VERSION ""

NS_ :

BS_:

BU_: EHR_Spare FEHR_3 PTO_SpeedSelector Dummy_Node_Ch2 FEHR_2 TrailerBrake OffBoardDiagnosticTool1_Ch2 PowerTakeOff_Ch2 Transmission1_Ch2 FEHR_1 REHR_5 REHR_4 REHR_3 REHR_2 REHR_1 InstrumentCluster_Ch2 ManagementComputer_Ch2 GWAY_OnBoardDiagnosticUnit_Ch2 GWAY_OffBoardDiagTool1_VB1_Ch2 GWAY_Engine1_Ch2 GWAY_CabDisplay1_Ch2 AuxiliaryValveControl_Ch2

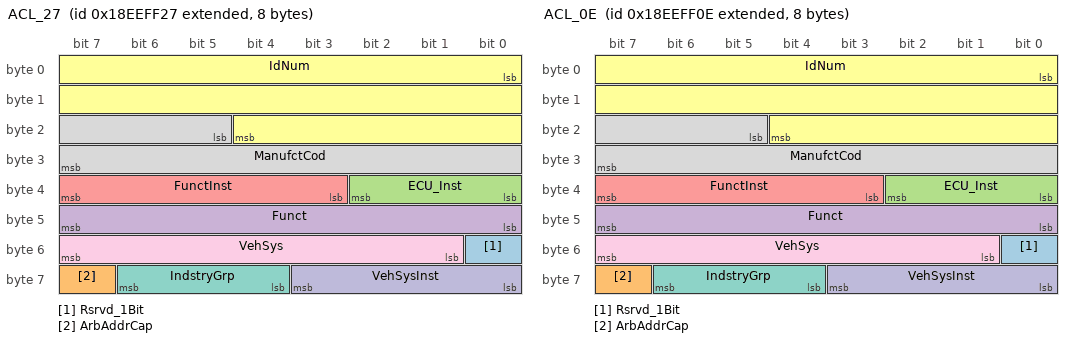
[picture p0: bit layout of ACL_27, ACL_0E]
BO_ 2565799719 ACL_27: 8 ManagementComputer_Ch2
 SG_ Rsrvd_1Bit : 48|1@1+ (1,0) [0|1] ""  Dummy_Node_Ch2
 SG_ ArbAddrCap : 63|1@1+ (1,0) [0|1] ""  Dummy_Node_Ch2
 SG_ ECU_Inst : 32|3@1+ (1,0) [0|7] ""  Dummy_Node_Ch2
 SG_ Funct : 40|8@1+ (1,0) [0|255] ""  Dummy_Node_Ch2
 SG_ FunctInst : 35|5@1+ (1,0) [0|31] ""  Dummy_Node_Ch2
 SG_ IdNum : 0|21@1+ (1,0) [0|2097151] ""  Dummy_Node_Ch2
 SG_ IndstryGrp M : 60|3@1+ (1,0) [0|7] ""  Dummy_Node_Ch2
 SG_ ManufctCod : 21|11@1+ (1,0) [0|2047] ""  Dummy_Node_Ch2
 SG_ VehSys : 49|7@1+ (1,0) [0|127] ""  Dummy_Node_Ch2
 SG_ VehSysInst : 56|4@1+ (1,0) [0|15] ""  Dummy_Node_Ch2

BO_ 2566838798 SOFT_0E: 60 TrailerBrake
 SG_ SupplrSW_VerNum_Byte_13 : 240|8@1+ (1,0) [0|255] ""  ManagementComputer_Ch2
 SG_ SupplrSW_VerNum_Byte_14 : 248|8@1+ (1,0) [0|255] ""  ManagementComputer_Ch2
 SG_ WarnErrDbVer : 472|8@1+ (1,0) [0|255] ""  ManagementComputer_Ch2
 SG_ ApplSW_PN : 8|8@1+ (1,0) [0|255] ""  ManagementComputer_Ch2
 SG_ ApplSW_PN_Byte_01 : 16|8@1+ (1,0) [0|255] ""  ManagementComputer_Ch2
 SG_ ApplSW_PN_Byte_02 : 24|8@1+ (1,0) [0|255] ""  ManagementComputer_Ch2
 SG_ ApplSW_PN_Byte_03 : 32|8@1+ (1,0) [0|255] ""  ManagementComputer_Ch2
 SG_ ApplSW_PN_Byte_04 : 40|8@1+ (1,0) [0|255] ""  ManagementComputer_Ch2
 SG_ ApplSW_PN_Byte_05 : 48|8@1+ (1,0) [0|255] ""  ManagementComputer_Ch2
 SG_ ApplSW_PN_Byte_06 : 56|8@1+ (1,0) [0|255] ""  ManagementComputer_Ch2
 SG_ ApplSW_PN_Byte_07 : 64|8@1+ (1,0) [0|255] ""  ManagementComputer_Ch2
 SG_ ApplSW_PN_Byte_08 : 72|8@1+ (1,0) [0|255] ""  ManagementComputer_Ch2
 SG_ ApplSW_PN_Byte_09 : 80|8@1+ (1,0) [0|255] ""  ManagementComputer_Ch2
 SG_ ApplSW_PN_Byte_10 : 88|8@1+ (1,0) [0|255] ""  ManagementComputer_Ch2
 SG_ ApplSW_PN_Byte_11 : 96|8@1+ (1,0) [0|255] ""  ManagementComputer_Ch2
 SG_ ApplSW_PN_Byte_12 : 104|8@1+ (1,0) [0|255] ""  ManagementComputer_Ch2
 SG_ ApplSW_PN_Byte_13 : 112|8@1+ (1,0) [0|255] ""  ManagementComputer_Ch2
 SG_ ApplSW_PN_Byte_14 : 120|8@1+ (1,0) [0|255] ""  ManagementComputer_Ch2
 SG_ CalibrId : 336|8@1+ (1,0) [0|255] "ASCII"  ManagementComputer_Ch2
 SG_ CalibrId_Byte_01 : 344|8@1+ (1,0) [0|255] "ASCII"  ManagementComputer_Ch2
 SG_ CalibrId_Byte_02 : 352|8@1+ (1,0) [0|255] "ASCII"  ManagementComputer_Ch2
 SG_ CalibrId_Byte_03 : 360|8@1+ (1,0) [0|255] "ASCII"  ManagementComputer_Ch2
 SG_ CalibrId_Byte_04 : 368|8@1+ (1,0) [0|255] "ASCII"  ManagementComputer_Ch2
 SG_ CalibrId_Byte_05 : 376|8@1+ (1,0) [0|255] "ASCII"  ManagementComputer_Ch2
 SG_ CalibrId_Byte_06 : 384|8@1+ (1,0) [0|255] "ASCII"  ManagementComputer_Ch2
 SG_ CalibrId_Byte_07 : 392|8@1+ (1,0) [0|255] "ASCII"  ManagementComputer_Ch2
 SG_ CalibrId_Byte_08 : 400|8@1+ (1,0) [0|255] "ASCII"  ManagementComputer_Ch2
 SG_ CalibrId_Byte_09 : 408|8@1+ (1,0) [0|255] "ASCII"  ManagementComputer_Ch2
 SG_ CalibrId_Byte_10 : 416|8@1+ (1,0) [0|255] "ASCII"  ManagementComputer_Ch2
 SG_ CalibrId_Byte_11 : 424|8@1+ (1,0) [0|255] "ASCII"  ManagementComputer_Ch2
 SG_ CalibrId_Byte_12 : 432|8@1+ (1,0) [0|255] "ASCII"  ManagementComputer_Ch2
 SG_ CalibrId_Byte_13 : 440|8@1+ (1,0) [0|255] "ASCII"  ManagementComputer_Ch2
 SG_ CalibrId_Byte_14 : 448|8@1+ (1,0) [0|255] "ASCII"  ManagementComputer_Ch2
 SG_ CalibrId_Byte_15 : 456|8@1+ (1,0) [0|255] "ASCII"  ManagementComputer_Ch2
 SG_ EndStrng_00 : 128|8@1+ (1,0) [0|255] "per byte"  ManagementComputer_Ch2
 SG_ EndStrng_01 : 256|8@1+ (1,0) [0|255] "per byte"  ManagementComputer_Ch2
 SG_ EndStrng_02 : 328|8@1+ (1,0) [0|255] ""  ManagementComputer_Ch2
 SG_ EndStrng_03 : 464|8@1+ (1,0) [0|255] ""  ManagementComputer_Ch2
 SG_ NumSW_IdField : 0|8@1+ (1,0) [0|250] "step"  ManagementComputer_Ch2
 SG_ ProgDate : 264|8@1+ (1,0) [0|255] ""  ManagementComputer_Ch2
 SG_ ProgDate_Byte_01 : 272|8@1+ (1,0) [0|255] ""  ManagementComputer_Ch2
 SG_ ProgDate_Byte_02 : 280|8@1+ (1,0) [0|255] ""  ManagementComputer_Ch2
 SG_ ProgDate_Byte_03 : 288|8@1+ (1,0) [0|255] ""  ManagementComputer_Ch2
 SG_ ProgDate_Byte_04 : 296|8@1+ (1,0) [0|255] ""  ManagementComputer_Ch2
 SG_ ProgDate_Byte_05 : 304|8@1+ (1,0) [0|255] ""  ManagementComputer_Ch2
 SG_ ProgDate_Byte_06 : 312|8@1+ (1,0) [0|255] ""  ManagementComputer_Ch2
 SG_ ProgDate_Byte_07 : 320|8@1+ (1,0) [0|255] ""  ManagementComputer_Ch2
 SG_ SupplrSW_VerNum : 136|8@1+ (1,0) [0|255] ""  ManagementComputer_Ch2
 SG_ SupplrSW_VerNum_Byte_01 : 144|8@1+ (1,0) [0|255] ""  ManagementComputer_Ch2
 SG_ SupplrSW_VerNum_Byte_02 : 152|8@1+ (1,0) [0|255] ""  ManagementComputer_Ch2
 SG_ SupplrSW_VerNum_Byte_03 : 160|8@1+ (1,0) [0|255] ""  ManagementComputer_Ch2
 SG_ SupplrSW_VerNum_Byte_04 : 168|8@1+ (1,0) [0|255] ""  ManagementComputer_Ch2
 SG_ SupplrSW_VerNum_Byte_05 : 176|8@1+ (1,0) [0|255] ""  ManagementComputer_Ch2
 SG_ SupplrSW_VerNum_Byte_06 : 184|8@1+ (1,0) [0|255] ""  ManagementComputer_Ch2
 SG_ SupplrSW_VerNum_Byte_07 : 192|8@1+ (1,0) [0|255] ""  ManagementComputer_Ch2
 SG_ SupplrSW_VerNum_Byte_08 : 200|8@1+ (1,0) [0|255] ""  ManagementComputer_Ch2
 SG_ SupplrSW_VerNum_Byte_09 : 208|8@1+ (1,0) [0|255] ""  ManagementComputer_Ch2
 SG_ SupplrSW_VerNum_Byte_10 : 216|8@1+ (1,0) [0|255] ""  ManagementComputer_Ch2
 SG_ SupplrSW_VerNum_Byte_11 : 224|8@1+ (1,0) [0|255] ""  ManagementComputer_Ch2
 SG_ SupplrSW_VerNum_Byte_12 : 232|8@1+ (1,0) [0|255] ""  ManagementComputer_Ch2

BO_ 2566835470 DM4_0E: 31 TrailerBrake
 SG_ EngIntakManifld_1Prs : 48|8@1+ (2,0) [0|500] "kPa"  ManagementComputer_Ch2
 SG_ EngSpd : 56|16@1+ (0.125,0) [0|8031.88] "rpm"  ManagementComputer_Ch2
 SG_ EngTorqMode : 40|4@1+ (1,0) [0|15] ""  ManagementComputer_Ch2
 SG_ EngTotHourOp : 200|32@1+ (0.05,0) [0|210554000] "h"  ManagementComputer_Ch2
 SG_ FailModeId : 24|5@1+ (1,0) [0|31] ""  ManagementComputer_Ch2
 SG_ FreezeFrameLen : 0|8@1+ (1,0) [0|255] "count"  ManagementComputer_Ch2
 SG_ HiResolTotVehDist : 168|32@1+ (5,0) [0|21055406075] "m"  ManagementComputer_Ch2
 SG_ Hour : 136|8@1+ (1,0) [0|250] "h"  ManagementComputer_Ch2
 SG_ Minut : 128|8@1+ (1,0) [0|250] "min"  ManagementComputer_Ch2
 SG_ Month : 152|8@1+ (1,0) [0|250] "months"  ManagementComputer_Ch2
 SG_ OC : 32|7@1+ (1,0) [0|127] "binary"  ManagementComputer_Ch2
 SG_ Sec : 120|8@1+ (0.25,0) [0|62.5] "s"  ManagementComputer_Ch2
 SG_ SPN : 8|16@1+ (1,0) [0|65535] ""  ManagementComputer_Ch2
 SG_ SPN1High : 29|3@1+ (1,0) [0|7] ""  ManagementComputer_Ch2
 SG_ SPN_CM : 39|1@1+ (1,0) [0|1] "bit"  ManagementComputer_Ch2
 SG_ WhBsdVehSpd : 88|16@1+ (0.00390625,0) [0|250.996] "km/h"  ManagementComputer_Ch2
 SG_ Year : 160|8@1+ (1,1985) [1985|2235] "years"  ManagementComputer_Ch2
 SG_ AmbrLmpDefSts : 234|2@1+ (1,0) [0|3] ""  ManagementComputer_Ch2
 SG_ EngCoolntTemp : 80|8@1+ (1,-40) [-40|210] "°C"  ManagementComputer_Ch2
 SG_ RedLmpDefSts : 236|2@1+ (1,0) [0|3] ""  ManagementComputer_Ch2
 SG_ AddrAssignNewSA : 240|8@1+ (1,0) [0|255] ""  ManagementComputer_Ch2
 SG_ BattPotentPwrInput_1 : 104|16@1+ (0.05,0) [0|3212.75] "V"  ManagementComputer_Ch2
 SG_ Day : 144|8@1+ (0.25,0) [0|62.5] "days"  ManagementComputer_Ch2
 SG_ Eng_pcLoadCurrSpd : 72|8@1+ (1,0) [0|250] "%"  ManagementComputer_Ch2

BO_ 2566843150 CI_0E: 34 TrailerBrake
 SG_ Make : 0|8@1+ (1,0) [0|255] "ASCII"  ManagementComputer_Ch2
 SG_ Mdl : 48|8@1+ (1,0) [0|255] "ASCII"  ManagementComputer_Ch2
 SG_ SN_2 : 176|8@1+ (1,0) [0|255] "ASCII"  ManagementComputer_Ch2
 SG_ UnitNumPwrUnit : 264|8@1+ (1,0) [0|255] "ASCII"  ManagementComputer_Ch2

BO_ 2566767886 ECUID_0E: 71 TrailerBrake
 SG_ EndStrng_04 : 560|8@1+ (1,0) [0|255] "" Vector__XXX
 SG_ EndStrng_03 : 432|8@1+ (1,0) [0|255] "" Vector__XXX
 SG_ EndStrng_02 : 296|8@1+ (1,0) [0|255] "" Vector__XXX
 SG_ EndStrng_01 : 208|8@1+ (1,0) [0|255] "per byte" Vector__XXX
 SG_ EndStrng_00 : 120|8@1+ (1,0) [0|255] "per byte" Vector__XXX
 SG_ ECU_SN_Byte_09 : 200|8@1+ (1,0) [0|255] "ASCII" Vector__XXX
 SG_ ECU_SN_Byte_08 : 192|8@1+ (1,0) [0|255] "ASCII" Vector__XXX
 SG_ ECU_SN_Byte_07 : 184|8@1+ (1,0) [0|255] "ASCII" Vector__XXX
 SG_ ECU_SN_Byte_06 : 176|8@1+ (1,0) [0|255] "ASCII" Vector__XXX
 SG_ ECU_SN_Byte_05 : 168|8@1+ (1,0) [0|255] "ASCII" Vector__XXX
 SG_ ECU_SN_Byte_04 : 160|8@1+ (1,0) [0|255] "ASCII" Vector__XXX
 SG_ ECU_SN_Byte_03 : 152|8@1+ (1,0) [0|255] "ASCII" Vector__XXX
 SG_ ECU_SN_Byte_02 : 144|8@1+ (1,0) [0|255] "ASCII" Vector__XXX
 SG_ ECU_SN_Byte_01 : 136|8@1+ (1,0) [0|255] "ASCII" Vector__XXX
 SG_ ECU_PN_Byte_14 : 112|8@1+ (1,0) [0|255] "ASCII" Vector__XXX
 SG_ ECU_PN_Byte_13 : 104|8@1+ (1,0) [0|255] "ASCII" Vector__XXX
 SG_ ECU_PN_Byte_12 : 96|8@1+ (1,0) [0|255] "ASCII" Vector__XXX
 SG_ ECU_PN_Byte_11 : 88|8@1+ (1,0) [0|255] "ASCII" Vector__XXX
 SG_ ECU_PN_Byte_10 : 80|8@1+ (1,0) [0|255] "ASCII" Vector__XXX
 SG_ ECU_PN_Byte_09 : 72|8@1+ (1,0) [0|255] "ASCII" Vector__XXX
 SG_ ECU_PN_Byte_08 : 64|8@1+ (1,0) [0|255] "ASCII" Vector__XXX
 SG_ ECU_PN_Byte_07 : 56|8@1+ (1,0) [0|255] "ASCII" Vector__XXX
 SG_ ECU_PN_Byte_06 : 48|8@1+ (1,0) [0|255] "ASCII" Vector__XXX
 SG_ ECU_PN_Byte_05 : 40|8@1+ (1,0) [0|255] "ASCII" Vector__XXX
 SG_ ECU_PN_Byte_04 : 32|8@1+ (1,0) [0|255] "ASCII" Vector__XXX
 SG_ ECU_PN_Byte_03 : 24|8@1+ (1,0) [0|255] "ASCII" Vector__XXX
 SG_ ECU_PN_Byte_02 : 16|8@1+ (1,0) [0|255] "ASCII" Vector__XXX
 SG_ ECU_PN_Byte_01 : 8|8@1+ (1,0) [0|255] "ASCII" Vector__XXX
 SG_ ECU_ManufctName_Byte_14 : 424|8@1+ (1,0) [0|255] "ASCII" Vector__XXX
 SG_ ECU_ManufctName_Byte_13 : 416|8@1+ (1,0) [0|255] "ASCII" Vector__XXX
 SG_ ECU_ManufctName_Byte_12 : 408|8@1+ (1,0) [0|255] "ASCII" Vector__XXX
 SG_ ECU_ManufctName_Byte_11 : 400|8@1+ (1,0) [0|255] "ASCII" Vector__XXX
 SG_ ECU_ManufctName_Byte_10 : 392|8@1+ (1,0) [0|255] "ASCII" Vector__XXX
 SG_ ECU_ManufctName_Byte_09 : 384|8@1+ (1,0) [0|255] "ASCII" Vector__XXX
 SG_ ECU_ManufctName_Byte_08 : 376|8@1+ (1,0) [0|255] "ASCII" Vector__XXX
 SG_ ECU_ManufctName_Byte_07 : 368|8@1+ (1,0) [0|255] "ASCII" Vector__XXX
 SG_ ECU_ManufctName_Byte_06 : 360|8@1+ (1,0) [0|255] "ASCII" Vector__XXX
 SG_ ECU_ManufctName_Byte_05 : 352|8@1+ (1,0) [0|255] "ASCII" Vector__XXX
 SG_ ECU_ManufctName_Byte_04 : 344|8@1+ (1,0) [0|255] "ASCII" Vector__XXX
 SG_ ECU_ManufctName_Byte_03 : 336|8@1+ (1,0) [0|255] "ASCII" Vector__XXX
 SG_ ECU_ManufctName_Byte_02 : 328|8@1+ (1,0) [0|255] "ASCII" Vector__XXX
 SG_ ECU_ManufctName_Byte_01 : 320|8@1+ (1,0) [0|255] "ASCII" Vector__XXX
 SG_ ECU_Locat_Byte_09 : 288|8@1+ (1,0) [0|255] "ASCII" Vector__XXX
 SG_ ECU_Locat_Byte_08 : 280|8@1+ (1,0) [0|255] "ASCII" Vector__XXX
 SG_ ECU_Locat_Byte_07 : 272|8@1+ (1,0) [0|255] "ASCII" Vector__XXX
 SG_ ECU_Locat_Byte_06 : 264|8@1+ (1,0) [0|255] "ASCII" Vector__XXX
 SG_ ECU_Locat_Byte_05 : 256|8@1+ (1,0) [0|255] "ASCII" Vector__XXX
 SG_ ECU_Locat_Byte_04 : 248|8@1+ (1,0) [0|255] "ASCII" Vector__XXX
 SG_ ECU_Locat_Byte_03 : 240|8@1+ (1,0) [0|255] "ASCII" Vector__XXX
 SG_ ECU_Locat_Byte_02 : 232|8@1+ (1,0) [0|255] "ASCII" Vector__XXX
 SG_ ECU_Locat_Byte_01 : 224|8@1+ (1,0) [0|255] "ASCII" Vector__XXX
 SG_ ECU_HW_Id_Byte_14 : 552|8@1+ (1,0) [0|255] "ASCII" Vector__XXX
 SG_ ECU_HW_Id_Byte_13 : 544|8@1+ (1,0) [0|255] "ASCII" Vector__XXX
 SG_ ECU_HW_Id_Byte_12 : 536|8@1+ (1,0) [0|255] "ASCII" Vector__XXX
 SG_ ECU_HW_Id_Byte_11 : 528|8@1+ (1,0) [0|255] "ASCII" Vector__XXX
 SG_ ECU_HW_Id_Byte_10 : 520|8@1+ (1,0) [0|255] "ASCII" Vector__XXX
 SG_ ECU_HW_Id_Byte_09 : 512|8@1+ (1,0) [0|255] "ASCII" Vector__XXX
 SG_ ECU_HW_Id_Byte_08 : 504|8@1+ (1,0) [0|255] "ASCII" Vector__XXX
 SG_ ECU_HW_Id_Byte_07 : 496|8@1+ (1,0) [0|255] "ASCII" Vector__XXX
 SG_ ECU_HW_Id_Byte_06 : 488|8@1+ (1,0) [0|255] "ASCII" Vector__XXX
 SG_ ECU_HW_Id_Byte_05 : 480|8@1+ (1,0) [0|255] "ASCII" Vector__XXX
 SG_ ECU_HW_Id_Byte_04 : 472|8@1+ (1,0) [0|255] "ASCII" Vector__XXX
 SG_ ECU_HW_Id_Byte_03 : 464|8@1+ (1,0) [0|255] "ASCII" Vector__XXX
 SG_ ECU_HW_Id_Byte_02 : 456|8@1+ (1,0) [0|255] "ASCII" Vector__XXX
 SG_ ECU_HW_Id_Byte_01 : 448|8@1+ (1,0) [0|255] "ASCII" Vector__XXX
 SG_ ECU_Locat : 216|8@1+ (1,0) [0|255] "ASCII"  ManagementComputer_Ch2
 SG_ ECU_ManufctName : 312|8@1+ (1,0) [0|255] "ASCII"  ManagementComputer_Ch2
 SG_ ECU_PN : 0|8@1+ (1,0) [0|255] "ASCII"  ManagementComputer_Ch2
 SG_ ECU_SN : 128|8@1+ (1,0) [0|255] "ASCII"  ManagementComputer_Ch2
 SG_ ECU_Typ : 304|8@1+ (1,0) [0|255] "ASCII"  ManagementComputer_Ch2
 SG_ ECUHardwareVersionIdentification : 440|8@1+ (1,0) [0|255] "ASCII"  ManagementComputer_Ch2

BO_ 2566837006 DM11_0E: 0 TrailerBrake

BO_ 2566835214 DM3_0E: 0 TrailerBrake

BO_ 2566834702 DM1_0E: 82 TrailerBrake
 SG_ AmbrWarnLmp : 2|2@1+ (1,0) [0|3] "" Vector__XXX
 SG_ DTC_01 : 16|32@1+ (1,0) [0|4294970000] "" Vector__XXX
 SG_ DTC_02 : 48|32@1+ (1,0) [0|4294970000] "" Vector__XXX
 SG_ DTC_03 : 80|32@1+ (1,0) [0|4294970000] "" Vector__XXX
 SG_ DTC_04 : 112|32@1+ (1,0) [0|4294970000] "" Vector__XXX
 SG_ DTC_05 : 144|32@1+ (1,0) [0|4294970000] "" Vector__XXX
 SG_ DTC_06 : 176|32@1+ (1,0) [0|4294970000] "" Vector__XXX
 SG_ DTC_07 : 208|32@1+ (1,0) [0|4294970000] "" Vector__XXX
 SG_ DTC_08 : 240|32@1+ (1,0) [0|4294970000] "" Vector__XXX
 SG_ DTC_09 : 272|32@1+ (1,0) [0|4294970000] "" Vector__XXX
 SG_ DTC_10 : 304|32@1+ (1,0) [0|4294970000] "" Vector__XXX
 SG_ DTC_11 : 336|32@1+ (1,0) [0|4294970000] "" Vector__XXX
 SG_ DTC_12 : 368|32@1+ (1,0) [0|4294970000] "" Vector__XXX
 SG_ DTC_13 : 400|32@1+ (1,0) [0|4294970000] "" Vector__XXX
 SG_ DTC_14 : 432|32@1+ (1,0) [0|4294970000] "" Vector__XXX
 SG_ DTC_15 : 464|32@1+ (1,0) [0|4294970000] "" Vector__XXX
 SG_ DTC_16 : 496|32@1+ (1,0) [0|4294970000] "" Vector__XXX
 SG_ DTC_17 : 528|32@1+ (1,0) [0|4294970000] "" Vector__XXX
 SG_ DTC_18 : 560|32@1+ (1,0) [0|4294970000] "" Vector__XXX
 SG_ DTC_19 : 592|32@1+ (1,0) [0|4294970000] "" Vector__XXX
 SG_ DTC_20 : 624|32@1+ (1,0) [0|4294970000] "" Vector__XXX
 SG_ FlashAmbrWarnLmpAWL : 10|2@1+ (1,0) [0|3] "" Vector__XXX
 SG_ FlashMIL : 14|2@1+ (1,0) [0|3] "" Vector__XXX
 SG_ FlashProtLmp : 8|2@1+ (1,0) [0|3] "" Vector__XXX
 SG_ FlashRedStopLmpRSL : 12|2@1+ (1,0) [0|3] "" Vector__XXX
 SG_ MIL : 6|2@1+ (1,0) [0|3] "" Vector__XXX
 SG_ ProtLmp : 0|2@1+ (1,0) [0|3] "" Vector__XXX
 SG_ RedStopLmp : 4|2@1+ (1,0) [0|3] "" Vector__XXX

BO_ 2566834958 DM2_0E: 82 TrailerBrake
 SG_ AmbrWarnLmp : 2|2@1+ (1,0) [0|3] "" Vector__XXX
 SG_ DTC_01 : 16|32@1+ (1,0) [0|4294970000] "" Vector__XXX
 SG_ DTC_02 : 48|32@1+ (1,0) [0|4294970000] "" Vector__XXX
 SG_ DTC_03 : 80|32@1+ (1,0) [0|4294970000] "" Vector__XXX
 SG_ DTC_04 : 112|32@1+ (1,0) [0|4294970000] "" Vector__XXX
 SG_ DTC_05 : 144|32@1+ (1,0) [0|4294970000] "" Vector__XXX
 SG_ DTC_06 : 176|32@1+ (1,0) [0|4294970000] "" Vector__XXX
 SG_ DTC_07 : 208|32@1+ (1,0) [0|4294970000] "" Vector__XXX
 SG_ DTC_08 : 240|32@1+ (1,0) [0|4294970000] "" Vector__XXX
 SG_ DTC_09 : 272|32@1+ (1,0) [0|4294970000] "" Vector__XXX
 SG_ DTC_10 : 304|32@1+ (1,0) [0|4294970000] "" Vector__XXX
 SG_ DTC_11 : 336|32@1+ (1,0) [0|4294970000] "" Vector__XXX
 SG_ DTC_12 : 368|32@1+ (1,0) [0|4294970000] "" Vector__XXX
 SG_ DTC_13 : 400|32@1+ (1,0) [0|4294970000] "" Vector__XXX
 SG_ DTC_14 : 432|32@1+ (1,0) [0|4294970000] "" Vector__XXX
 SG_ DTC_15 : 464|32@1+ (1,0) [0|4294970000] "" Vector__XXX
 SG_ DTC_16 : 496|32@1+ (1,0) [0|4294970000] "" Vector__XXX
 SG_ DTC_17 : 528|32@1+ (1,0) [0|4294970000] "" Vector__XXX
 SG_ DTC_18 : 560|32@1+ (1,0) [0|4294970000] "" Vector__XXX
 SG_ DTC_19 : 592|32@1+ (1,0) [0|4294970000] "" Vector__XXX
 SG_ DTC_20 : 624|32@1+ (1,0) [0|4294970000] "" Vector__XXX
 SG_ FlashAmbrWarnLmpAWL : 10|2@1+ (1,0) [0|3] "" Vector__XXX
 SG_ FlashMIL : 14|2@1+ (1,0) [0|3] "" Vector__XXX
 SG_ FlashProtLmp : 8|2@1+ (1,0) [0|3] "" Vector__XXX
 SG_ FlashRedStopLmpRSL : 12|2@1+ (1,0) [0|3] "" Vector__XXX
 SG_ MIL : 6|2@1+ (1,0) [0|3] "" Vector__XXX
 SG_ ProtLmp : 0|2@1+ (1,0) [0|3] "" Vector__XXX
 SG_ RedStopLmp : 4|2@1+ (1,0) [0|3] "" Vector__XXX

BO_ 2565799694 ACL_0E: 8 TrailerBrake
 SG_ Rsrvd_1Bit : 48|1@1+ (1,0) [0|1] ""  ManagementComputer_Ch2
 SG_ ArbAddrCap : 63|1@1+ (1,0) [0|1] ""  ManagementComputer_Ch2
 SG_ ECU_Inst : 32|3@1+ (1,0) [0|7] ""  ManagementComputer_Ch2
 SG_ Funct : 40|8@1+ (1,0) [0|255] ""  ManagementComputer_Ch2
 SG_ FunctInst : 35|5@1+ (1,0) [0|31] ""  ManagementComputer_Ch2
 SG_ IdNum : 0|21@1+ (1,0) [0|2097151] ""  ManagementComputer_Ch2
 SG_ IndstryGrp : 60|3@1+ (1,0) [0|7] ""  ManagementComputer_Ch2
 SG_ ManufctCod : 21|11@1+ (1,0) [0|2047] ""  ManagementComputer_Ch2
 SG_ VehSys : 49|7@1+ (1,0) [0|127] ""  ManagementComputer_Ch2
 SG_ VehSysInst : 56|4@1+ (1,0) [0|15] ""  ManagementComputer_Ch2

BO_ 2632777486 TPCM_0E: 8 TrailerBrake
 SG_ TotNumPktEoMA m19 : 24|8@1+ (1,0) [0|255] "" Vector__XXX
 SG_ CByteTPCM M : 0|8@1+ (1,0) [0|255] "" Vector__XXX
 SG_ ConnAbrtReason m255 : 8|8@1+ (1,0) [0|255] "" Vector__XXX
 SG_ MaxNumPktTPCM_RTS m16 : 32|8@1+ (1,0) [0|255] "" Vector__XXX
 SG_ NumPktSentTPCM_CTS m17 : 8|8@1+ (1,0) [0|255] "" Vector__XXX
 SG_ NxtPktNumSentTPCM_CTS m17 : 16|8@1+ (1,0) [0|255] "" Vector__XXX
 SG_ PGN_PktMsgTPCM_BAM m32 : 40|24@1+ (1,0) [0|16777200] "" Vector__XXX
 SG_ PGN_PktMsgTPCM_ConnAbort m255 : 40|24@1+ (1,0) [0|16777200] "" Vector__XXX
 SG_ PGN_PktMsgTPCM_CTS m17 : 40|24@1+ (1,0) [0|16777200] "" Vector__XXX
 SG_ PGN_PktMsgTPCM_RTS m16 : 40|24@1+ (1,0) [0|16777200] "" Vector__XXX
 SG_ PGN_PktMsgTPCM_RTS2 m19 : 40|24@1+ (1,0) [0|16777200] "" Vector__XXX
 SG_ TotMsgSizeBAM m32 : 8|16@1+ (1,0) [0|64255] "counts" Vector__XXX
 SG_ TotMsgSizeEoMA m19 : 8|16@1+ (1,0) [0|64255] "counts" Vector__XXX
 SG_ TotMsgSizeTPCM_RTS m16 : 8|16@1+ (1,0) [0|64255] "counts" Vector__XXX
 SG_ TotNumPktBAM m32 : 24|8@1+ (1,0) [0|255] "" Vector__XXX
 SG_ TotNumPktTPCM_RTS m16 : 24|8@1+ (1,0) [0|255] "" Vector__XXX

BO_ 2565352206 ACKM_0E_2B: 8 TrailerBrake
 SG_ AddrAccssDeny m2 : 32|8@1+ (1,0) [0|255] ""  GWAY_OnBoardDiagnosticUnit_Ch2
 SG_ AddrAck m0 : 32|8@1+ (1,0) [0|255] ""  GWAY_OnBoardDiagnosticUnit_Ch2
 SG_ AddrBusy m3 : 32|8@1+ (1,0) [0|255] ""  GWAY_OnBoardDiagnosticUnit_Ch2
 SG_ AddrNegAck m1 : 32|8@1+ (1,0) [0|255] ""  GWAY_OnBoardDiagnosticUnit_Ch2
 SG_ CByteAckm M : 0|8@1+ (1,0) [0|255] ""  GWAY_OnBoardDiagnosticUnit_Ch2
 SG_ GrpFunctValAck : 8|8@1+ (1,0) [0|255] ""  GWAY_OnBoardDiagnosticUnit_Ch2
 SG_ PGN_RQST2_0E_28 : 40|24@1+ (1,0) [0|16777200] ""  GWAY_OnBoardDiagnosticUnit_Ch2

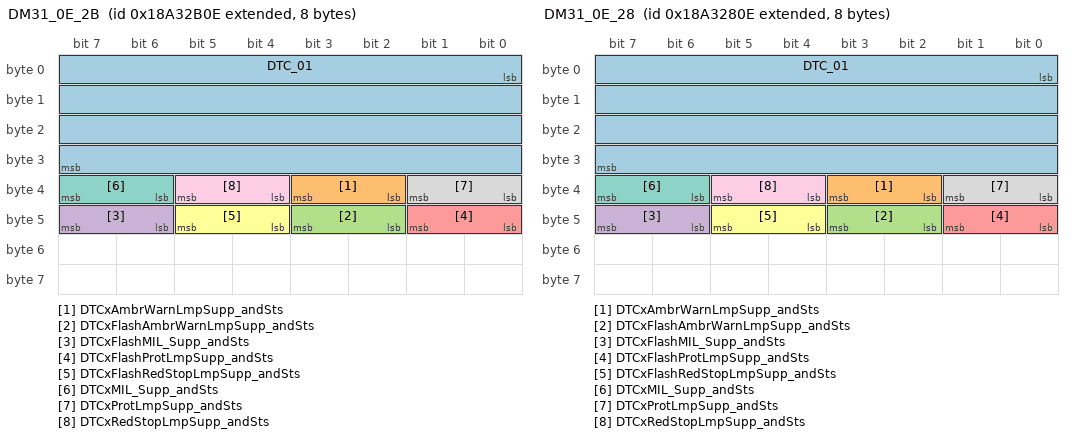
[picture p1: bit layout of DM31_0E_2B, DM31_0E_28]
BO_ 2560830222 DM31_0E_2B: 8 TrailerBrake
 SG_ DTC_01 : 0|32@1+ (1,0) [0|4294970000] ""  GWAY_OnBoardDiagnosticUnit_Ch2
 SG_ DTCxAmbrWarnLmpSupp_andSts : 34|2@1+ (1,0) [0|3] ""  GWAY_OnBoardDiagnosticUnit_Ch2
 SG_ DTCxFlashAmbrWarnLmpSupp_andSts : 42|2@1+ (1,0) [0|3] ""  GWAY_OnBoardDiagnosticUnit_Ch2
 SG_ DTCxFlashMIL_Supp_andSts : 46|2@1+ (1,0) [0|3] ""  GWAY_OnBoardDiagnosticUnit_Ch2
 SG_ DTCxFlashProtLmpSupp_andSts : 40|2@1+ (1,0) [0|3] ""  GWAY_OnBoardDiagnosticUnit_Ch2
 SG_ DTCxFlashRedStopLmpSupp_andSts : 44|2@1+ (1,0) [0|3] ""  GWAY_OnBoardDiagnosticUnit_Ch2
 SG_ DTCxMIL_Supp_andSts : 38|2@1+ (1,0) [0|3] ""  GWAY_OnBoardDiagnosticUnit_Ch2
 SG_ DTCxProtLmpSupp_andSts : 32|2@1+ (1,0) [0|3] ""  GWAY_OnBoardDiagnosticUnit_Ch2
 SG_ DTCxRedStopLmpSupp_andSts : 36|2@1+ (1,0) [0|3] ""  GWAY_OnBoardDiagnosticUnit_Ch2

BO_ 2565537579 RQST_2B: 3 GWAY_OnBoardDiagnosticUnit_Ch2
 SG_ PGN_RQST_2B : 0|24@1+ (1,0) [0|16777200] ""  TrailerBrake

BO_ 2565475883 RQST_2B_0E: 3 GWAY_OnBoardDiagnosticUnit_Ch2
 SG_ PGN_RQST_2B_0E : 0|24@1+ (1,0) [0|16777200] ""  TrailerBrake

BO_ 2564487438 ISO15765_Phys_0E_F9: 8 TrailerBrake
 SG_ BlkSize m3 : 8|8@1+ (1,0) [0|255] ""  GWAY_OffBoardDiagTool1_VB1_Ch2
 SG_ FlowSts m3 : 0|4@1+ (1,0) [0|3] ""  GWAY_OffBoardDiagTool1_VB1_Ch2
 SG_ N1FrameDataLen m1 : 3|12@0+ (1,0) [0|4095] "Byte"  GWAY_OffBoardDiagTool1_VB1_Ch2
 SG_ ProtocCntrlInfo M : 4|4@1+ (1,0) [0|3] ""  GWAY_OffBoardDiagTool1_VB1_Ch2
 SG_ SepTime m3 : 16|8@1+ (1,0) [0|255] "ms"  GWAY_OffBoardDiagTool1_VB1_Ch2
 SG_ SingFrameDataLen m0 : 0|4@1+ (1,0) [0|7] "Byte"  GWAY_OffBoardDiagTool1_VB1_Ch2
 SG_ SN m2 : 0|4@1+ (1,0) [0|15] ""  GWAY_OffBoardDiagTool1_VB1_Ch2

BO_ 2564427513 ISO15765_Phys_F9_0E: 8 GWAY_OffBoardDiagTool1_VB1_Ch2
 SG_ BlkSize m3 : 8|8@1+ (1,0) [0|255] ""  TrailerBrake
 SG_ FlowSts m3 : 0|4@1+ (1,0) [0|3] ""  TrailerBrake
 SG_ N1FrameDataLen m1 : 3|12@0+ (1,0) [0|4095] "Byte"  TrailerBrake
 SG_ ProtocCntrlInfo M : 4|4@1+ (1,0) [0|3] ""  TrailerBrake
 SG_ SepTime m3 : 16|8@1+ (1,0) [0|255] "ms"  TrailerBrake
 SG_ SingFrameDataLen m0 : 0|4@1+ (1,0) [0|7] "Byte"  TrailerBrake
 SG_ SN m2 : 0|4@1+ (1,0) [0|15] ""  TrailerBrake

BO_ 2565351438 ACKM_0E_28: 8 TrailerBrake
 SG_ AddrAccssDeny m2 : 32|8@1+ (1,0) [0|255] ""  GWAY_CabDisplay1_Ch2
 SG_ AddrAck m0 : 32|8@1+ (1,0) [0|255] ""  GWAY_CabDisplay1_Ch2
 SG_ AddrBusy m3 : 32|8@1+ (1,0) [0|255] ""  GWAY_CabDisplay1_Ch2
 SG_ AddrNegAck m1 : 32|8@1+ (1,0) [0|255] ""  GWAY_CabDisplay1_Ch2
 SG_ CByteAckm M : 0|8@1+ (1,0) [0|255] ""  GWAY_CabDisplay1_Ch2
 SG_ GrpFunctValAck : 8|8@1+ (1,0) [0|255] ""  GWAY_CabDisplay1_Ch2
 SG_ PGN_RQST2_0E_28 : 40|24@1+ (1,0) [0|16777200] ""  GWAY_CabDisplay1_Ch2

BO_ 2560829454 DM31_0E_28: 8 TrailerBrake
 SG_ DTC_01 : 0|32@1+ (1,0) [0|4294970000] ""  GWAY_CabDisplay1_Ch2
 SG_ DTCxAmbrWarnLmpSupp_andSts : 34|2@1+ (1,0) [0|3] ""  GWAY_CabDisplay1_Ch2
 SG_ DTCxFlashAmbrWarnLmpSupp_andSts : 42|2@1+ (1,0) [0|3] ""  GWAY_CabDisplay1_Ch2
 SG_ DTCxFlashMIL_Supp_andSts : 46|2@1+ (1,0) [0|3] ""  GWAY_CabDisplay1_Ch2
 SG_ DTCxFlashProtLmpSupp_andSts : 40|2@1+ (1,0) [0|3] ""  GWAY_CabDisplay1_Ch2
 SG_ DTCxFlashRedStopLmpSupp_andSts : 44|2@1+ (1,0) [0|3] ""  GWAY_CabDisplay1_Ch2
 SG_ DTCxMIL_Supp_andSts : 38|2@1+ (1,0) [0|3] ""  GWAY_CabDisplay1_Ch2
 SG_ DTCxProtLmpSupp_andSts : 32|2@1+ (1,0) [0|3] ""  GWAY_CabDisplay1_Ch2
 SG_ DTCxRedStopLmpSupp_andSts : 36|2@1+ (1,0) [0|3] ""  GWAY_CabDisplay1_Ch2

BO_ 2565537576 RQST_28: 3 GWAY_CabDisplay1_Ch2
 SG_ PGN_RQST_28 : 0|24@1+ (1,0) [0|16777200] ""  TrailerBrake

BO_ 2565475880 RQST_28_0E: 3 GWAY_CabDisplay1_Ch2
 SG_ PGN_RQST_28_0E : 0|24@1+ (1,0) [0|16777200] ""  TrailerBrake

BO_ 2564489209 ISO15765_Phys_F9: 8 GWAY_OffBoardDiagTool1_VB1_Ch2
 SG_ BlkSize m3 : 8|8@1+ (1,0) [0|255] ""  FEHR_3,TrailerBrake,FEHR_2,FEHR_1,REHR_5,REHR_4,REHR_3,REHR_2,REHR_1
 SG_ FlowSts m3 : 0|4@1+ (1,0) [0|3] ""  FEHR_3,TrailerBrake,FEHR_2,FEHR_1,REHR_5,REHR_4,REHR_3,REHR_2,REHR_1
 SG_ N1FrameDataLen m1 : 3|12@0+ (1,0) [0|4095] "Byte"  FEHR_3,TrailerBrake,FEHR_2,FEHR_1,REHR_5,REHR_4,REHR_3,REHR_2,REHR_1
 SG_ ProtocCntrlInfo M : 4|4@1+ (1,0) [0|3] ""  FEHR_3,TrailerBrake,FEHR_2,FEHR_1,REHR_5,REHR_4,REHR_3,REHR_2,REHR_1
 SG_ SepTime m3 : 16|8@1+ (1,0) [0|255] "ms"  FEHR_3,TrailerBrake,FEHR_2,FEHR_1,REHR_5,REHR_4,REHR_3,REHR_2,REHR_1
 SG_ SingFrameDataLen m0 : 0|4@1+ (1,0) [0|7] "Byte"  FEHR_3,TrailerBrake,FEHR_2,FEHR_1,REHR_5,REHR_4,REHR_3,REHR_2,REHR_1
 SG_ SN m2 : 0|4@1+ (1,0) [0|15] ""  FEHR_3,TrailerBrake,FEHR_2,FEHR_1,REHR_5,REHR_4,REHR_3,REHR_2,REHR_1

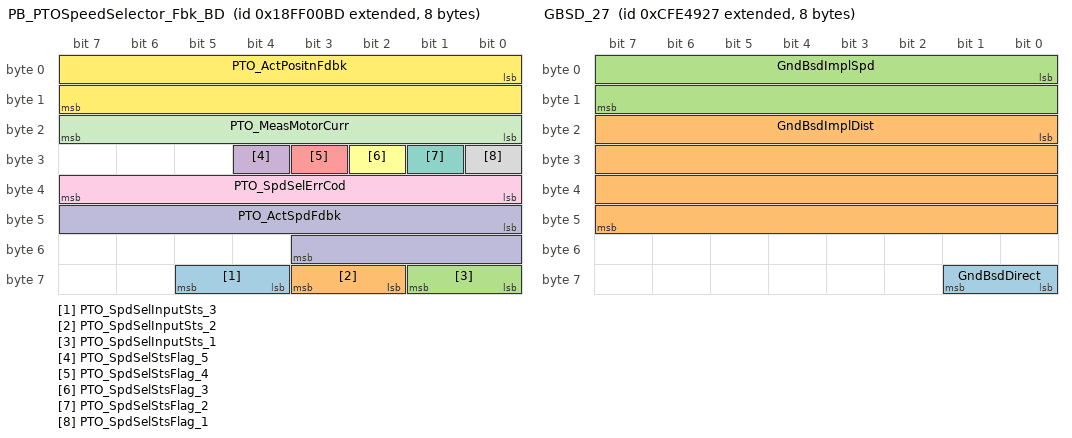
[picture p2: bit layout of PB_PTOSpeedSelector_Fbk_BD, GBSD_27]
BO_ 2566848701 PB_PTOSpeedSelector_Fbk_BD: 8 PTO_SpeedSelector
 SG_ PTO_SpdSelInputSts_3 : 60|2@1+ (25,25) [25|100] "%"  Transmission1_Ch2
 SG_ PTO_SpdSelInputSts_2 : 58|2@1+ (25,25) [25|100] "%"  Transmission1_Ch2
 SG_ PTO_SpdSelInputSts_1 : 56|2@1+ (25,25) [25|100] "%"  Transmission1_Ch2
 SG_ PTO_SpdSelStsFlag_5 : 28|1@1+ (1,0) [0|1] ""  Transmission1_Ch2
 SG_ PTO_SpdSelStsFlag_4 : 27|1@1+ (1,0) [0|1] ""  Transmission1_Ch2
 SG_ PTO_SpdSelStsFlag_3 : 26|1@1+ (1,0) [0|1] ""  Transmission1_Ch2
 SG_ PTO_SpdSelStsFlag_2 : 25|1@1+ (1,0) [0|1] ""  Transmission1_Ch2
 SG_ PTO_SpdSelStsFlag_1 : 24|1@1+ (1,0) [0|1] ""  Transmission1_Ch2
 SG_ PTO_SpdSelErrCod : 32|8@1+ (1,0) [0|255] ""  Transmission1_Ch2
 SG_ PTO_ActSpdFdbk : 40|12@1+ (0.1,0) [0|409.5] "mm/s"  Transmission1_Ch2
 SG_ PTO_MeasMotorCurr : 16|8@1+ (0.25,0) [0|62.5] "A"  Transmission1_Ch2
 SG_ PTO_ActPositnFdbk : 0|16@1+ (0.1,0) [0|6425.5] "mm"  Transmission1_Ch2

BO_ 2365475111 GBSD_27: 8 ManagementComputer_Ch2
 SG_ GndBsdDirect : 56|2@1+ (1,0) [0|3] ""  InstrumentCluster_Ch2
 SG_ GndBsdImplDist : 16|32@1+ (0.001,0) [0|4211081.215] "m"  InstrumentCluster_Ch2
 SG_ GndBsdImplSpd : 0|16@1+ (0.001,0) [0|64255] "m/s"  Transmission1_Ch2,InstrumentCluster_Ch2

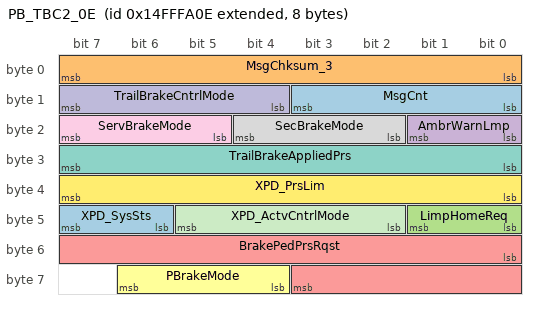
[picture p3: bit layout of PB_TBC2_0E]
BO_ 2499803662 PB_TBC2_0E: 8 TrailerBrake
 SG_ MsgCnt : 8|4@1+ (1,0) [0|15] "count"  ManagementComputer_Ch2
 SG_ MsgChksum_3 : 0|8@1+ (1,0) [0|255] "count"  ManagementComputer_Ch2
 SG_ LimpHomeReq : 40|2@1+ (1,0) [0|3] ""  ManagementComputer_Ch2
 SG_ AmbrWarnLmp : 16|2@1+ (1,0) [0|3] ""  ManagementComputer_Ch2
 SG_ BrakePedPrsRqst : 48|12@1+ (5,0) [0|20475] "kPa"  ManagementComputer_Ch2
 SG_ PBrakeMode : 60|3@1+ (1,0) [0|7] ""  ManagementComputer_Ch2
 SG_ TrailBrakeAppliedPrs : 24|8@1+ (5,0) [0|1250] "kPa"  ManagementComputer_Ch2
 SG_ SecBrakeMode : 18|3@1+ (1,0) [0|7] ""  ManagementComputer_Ch2
 SG_ ServBrakeMode : 21|3@1+ (1,0) [0|7] ""  ManagementComputer_Ch2
 SG_ TrailBrakeCntrlMode : 12|4@1+ (1,0) [0|15] ""  ManagementComputer_Ch2
 SG_ XPD_ActvCntrlMode : 42|4@1+ (1,0) [0|15] ""  ManagementComputer_Ch2
 SG_ XPD_PrsLim : 32|8@1+ (5,0) [0|1250] "kPa"  ManagementComputer_Ch2
 SG_ XPD_SysSts : 46|2@1+ (1,0) [0|3] ""  ManagementComputer_Ch2

BO_ 2564459257 ISO15765_Phys_F9_8A: 8 OffBoardDiagnosticTool1_Ch2
 SG_ SingFrameDataLen m0 : 0|4@1+ (1,0) [0|7] "Byte" Vector__XXX
 SG_ SN m2 : 0|4@1+ (1,0) [0|15] "" Vector__XXX
 SG_ ProtocCntrlInfo M : 4|4@1+ (1,0) [0|3] ""  FEHR_2
 SG_ N1FrameDataLen m1 : 3|12@0+ (1,0) [0|4095] "Byte" Vector__XXX
 SG_ BlkSize m3 : 8|8@1+ (1,0) [0|255] "" Vector__XXX
 SG_ FlowSts m3 : 0|4@1+ (1,0) [0|3] "" Vector__XXX
 SG_ SepTime m3 : 16|8@1+ (1,0) [0|255] "ms" Vector__XXX

BO_TX_BU_ 2564489209 : OffBoardDiagnosticTool1_Ch2,GWAY_OffBoardDiagTool1_VB1_Ch2;
CM_ BO_ 2565799719 "Address Claimed";
CM_ SG_ 2565799719 Rsrvd_1Bit "Set to 0 for J1939-81";
CM_ BO_ 2566838798 "Byte: 1 Number of software identification fields. 2-n Software identification(s) . Delimiter (ASCII “*”)  NOTE- The software identification field is variable in length and may contain up to 125 software identification designators.";
CM_ SG_ 2566838798 SupplrSW_VerNum_Byte_13 "Software ID. ";
CM_ SG_ 2566838798 SupplrSW_VerNum_Byte_14 "Software ID. ";
CM_ SG_ 2566838798 WarnErrDbVer "Software ID. Set to P826vxx or to P662vxx";
CM_ SG_ 2566838798 ApplSW_PN "Software ID. ";
CM_ SG_ 2566838798 ApplSW_PN_Byte_01 "Software ID. ";
CM_ SG_ 2566838798 ApplSW_PN_Byte_02 "Software ID. ";
CM_ SG_ 2566838798 ApplSW_PN_Byte_03 "Software ID. ";
CM_ SG_ 2566838798 ApplSW_PN_Byte_04 "Software ID. ";
CM_ SG_ 2566838798 ApplSW_PN_Byte_05 "Software ID. ";
CM_ SG_ 2566838798 ApplSW_PN_Byte_06 "Software ID. ";
CM_ SG_ 2566838798 ApplSW_PN_Byte_07 "Software ID. ";
CM_ SG_ 2566838798 ApplSW_PN_Byte_08 "Software ID. ";
CM_ SG_ 2566838798 ApplSW_PN_Byte_09 "Software ID. ";
CM_ SG_ 2566838798 ApplSW_PN_Byte_10 "Software ID. ";
CM_ SG_ 2566838798 ApplSW_PN_Byte_11 "Software ID. ";
CM_ SG_ 2566838798 ApplSW_PN_Byte_12 "Software ID. ";
CM_ SG_ 2566838798 ApplSW_PN_Byte_13 "Software ID. ";
CM_ SG_ 2566838798 ApplSW_PN_Byte_14 "Software ID. ";
CM_ SG_ 2566838798 CalibrId "this signal has a lenght of 16 bytes";
CM_ SG_ 2566838798 CalibrId_Byte_01 "this signal has a lenght of 16 bytes";
CM_ SG_ 2566838798 CalibrId_Byte_02 "this signal has a lenght of 16 bytes";
CM_ SG_ 2566838798 CalibrId_Byte_03 "this signal has a lenght of 16 bytes";
CM_ SG_ 2566838798 CalibrId_Byte_04 "this signal has a lenght of 16 bytes";
CM_ SG_ 2566838798 CalibrId_Byte_05 "this signal has a lenght of 16 bytes";
CM_ SG_ 2566838798 CalibrId_Byte_06 "this signal has a lenght of 16 bytes";
CM_ SG_ 2566838798 CalibrId_Byte_07 "this signal has a lenght of 16 bytes";
CM_ SG_ 2566838798 CalibrId_Byte_08 "this signal has a lenght of 16 bytes";
CM_ SG_ 2566838798 CalibrId_Byte_09 "this signal has a lenght of 16 bytes";
CM_ SG_ 2566838798 CalibrId_Byte_10 "this signal has a lenght of 16 bytes";
CM_ SG_ 2566838798 CalibrId_Byte_11 "this signal has a lenght of 16 bytes";
CM_ SG_ 2566838798 CalibrId_Byte_12 "this signal has a lenght of 16 bytes";
CM_ SG_ 2566838798 CalibrId_Byte_13 "this signal has a lenght of 16 bytes";
CM_ SG_ 2566838798 CalibrId_Byte_14 "this signal has a lenght of 16 bytes";
CM_ SG_ 2566838798 CalibrId_Byte_15 "this signal has a lenght of 16 bytes";
CM_ SG_ 2566838798 EndStrng_00 "Software ID. ";
CM_ SG_ 2566838798 EndStrng_01 "Software ID. ";
CM_ SG_ 2566838798 EndStrng_02 "Software ID. ";
CM_ SG_ 2566838798 EndStrng_03 "Software ID. ";
CM_ SG_ 2566838798 NumSW_IdField "Number of software identification designators represented in the software identification parameter group.";
CM_ SG_ 2566838798 ProgDate "Software ID. Set to P826vxx or to P662vxx";
CM_ SG_ 2566838798 ProgDate_Byte_01 "Software ID. Set to P826vxx or to P662vxx";
CM_ SG_ 2566838798 ProgDate_Byte_02 "Software ID. Set to P826vxx or to P662vxx";
CM_ SG_ 2566838798 ProgDate_Byte_03 "Software ID. Set to P826vxx or to P662vxx";
CM_ SG_ 2566838798 ProgDate_Byte_04 "Software ID. Set to P826vxx or to P662vxx";
CM_ SG_ 2566838798 ProgDate_Byte_05 "Software ID. Set to P826vxx or to P662vxx";
CM_ SG_ 2566838798 ProgDate_Byte_06 "Software ID. Set to P826vxx or to P662vxx";
CM_ SG_ 2566838798 ProgDate_Byte_07 "Software ID. Set to P826vxx or to P662vxx";
CM_ SG_ 2566838798 SupplrSW_VerNum "Software ID. ";
CM_ SG_ 2566838798 SupplrSW_VerNum_Byte_01 "Software ID. ";
CM_ SG_ 2566838798 SupplrSW_VerNum_Byte_02 "Software ID. ";
CM_ SG_ 2566838798 SupplrSW_VerNum_Byte_03 "Software ID. ";
CM_ SG_ 2566838798 SupplrSW_VerNum_Byte_04 "Software ID. ";
CM_ SG_ 2566838798 SupplrSW_VerNum_Byte_05 "Software ID. ";
CM_ SG_ 2566838798 SupplrSW_VerNum_Byte_06 "Software ID. ";
CM_ SG_ 2566838798 SupplrSW_VerNum_Byte_07 "Software ID. ";
CM_ SG_ 2566838798 SupplrSW_VerNum_Byte_08 "Software ID. ";
CM_ SG_ 2566838798 SupplrSW_VerNum_Byte_09 "Software ID. ";
CM_ SG_ 2566838798 SupplrSW_VerNum_Byte_10 "Software ID. ";
CM_ SG_ 2566838798 SupplrSW_VerNum_Byte_11 "Software ID. ";
CM_ SG_ 2566838798 SupplrSW_VerNum_Byte_12 "Software ID. ";
CM_ BO_ 2566835470 "Freeze frame parameters";
CM_ SG_ 2566835470 EngIntakManifld_1Prs "The gage pressure measurement of the air intake manifold. Boost pressure. This value is absolute pressure, not relative.";
CM_ SG_ 2566835470 EngSpd "Actual engine speed which is calculated over a minimum crankshaft angle of 720 degrees divided by the number of cylinders. Current engine speed as sensed at crankshaft 0xFE00 in case of error";
CM_ SG_ 2566835470 EngTorqMode "State signal which indicates which engine or retarder torque mode is currently generating, limiting, or controlling the torque. Other modes are under control of VCM";
CM_ SG_ 2566835470 EngTotHourOp "Accumulated time of operation of engine.";
CM_ SG_ 2566835470 FailModeId "The FMI defines the type of failure detected in the subsystem identified by an SPN.";
CM_ SG_ 2566835470 FreezeFrameLen "The freeze frame length shall be equal to the number of bytes in the required parameters plus the number of bytes in the...";
CM_ SG_ 2566835470 HiResolTotVehDist "Accumulated distance traveled by the vehicle during its operation.";
CM_ SG_ 2566835470 Hour "Description_Ref:_A003";
CM_ SG_ 2566835470 Minut "Description_Ref:_A002";
CM_ SG_ 2566835470 Month "Description_Ref:_A004";
CM_ SG_ 2566835470 OC "The 7-bit occurrence count field contains the number of times a fault has been independently detected.  The occurrence count is reported as 1 the first time the DTC is detected. The occurrence count is not incremented again, until after the DTC has go...";
CM_ SG_ 2566835470 Sec "Description_Ref:_A001";
CM_ SG_ 2566835470 SPN "SPN #1 (Conversion Version 4)";
CM_ SG_ 2566835470 SPN1High "SPN #1 (Conversion Version 4)";
CM_ SG_ 2566835470 SPN_CM "When this 1-bit field is equal to a zero, the SPN should be converted as it is defined.  The February 1996 version of J1939-73 contained inadequate definitions to assure consistent implementations. Products implementing to February 1996 version of the...";
CM_ SG_ 2566835470 WhBsdVehSpd "A value of the speed of a machine as calculated from the measured wheel or tail shaft speed. If available from VCM. Out of operating range values are not considered and 0 km/h replacement value is used";
CM_ SG_ 2566835470 Year "Description_Ref:_A006";
CM_ SG_ 2566835470 AmbrLmpDefSts "Values 10b and 11b are interpreted by the display the same as 00b.  If a fault does not support any lamp (not Amber or Red), then both the Amber and Red Lamp Definition Status values shall be 00b.";
CM_ SG_ 2566835470 EngCoolntTemp "Temperature of liquid found in engine cooling system. FEh in case of defective sensor.";
CM_ SG_ 2566835470 RedLmpDefSts "Values 10b and 11b are interpreted by the display the same as 00b.  If a fault does not support any lamp (not Amber or Red), then both the Amber and Red Lamp Definition Status values shall be 00b.";
CM_ SG_ 2566835470 AddrAssignNewSA "The source address that is to be assigned to the CA that has the NAME corresponding to the one conveyed in the first eight bytes of this Commanded Address message.";
CM_ SG_ 2566835470 BattPotentPwrInput_1 "For SFB: Battery potential measured at the input of the electronic control unit supplied direct from battery. For Engine: This parameter measures the first source of battery potential as measured at the input of the ECM/actuator etc.";
CM_ SG_ 2566835470 Day "Description_Ref:_A005";
CM_ SG_ 2566835470 Eng_pcLoadCurrSpd "The ratio of current engine inner torque to the maximum inner torque available at the current engine speed, clipped to zero torque during engine braking";
CM_ BO_ 2566843150 "Component Identificator.NOTE - The make, model, serial number and unit number fields in this message are optional and separated by an ASCII  “*”.  It is not necessary to include all fields;the delimiter (“*”) is always required.";
CM_ SG_ 2566843150 Make "Owner assigned unit number for the power unit of the vehicle.";
CM_ SG_ 2566843150 Mdl "Model of the component.";
CM_ SG_ 2566843150 SN_2 "Serial number of the component.";
CM_ SG_ 2566843150 UnitNumPwrUnit "Owner assigned unit number for the power unit of the vehicle.";
CM_ BO_ 2566767886 "Message for reporting identification and information about the physical ECU and its hardware, such as the ECU's part  number, serial number, build date, etc.  Information about the software within the ECU should be reported using the Software Identifi";
CM_ SG_ 2566767886 EndStrng_04 "Software ID. ";
CM_ SG_ 2566767886 EndStrng_03 "Software ID. ";
CM_ SG_ 2566767886 EndStrng_02 "Software ID. ";
CM_ SG_ 2566767886 EndStrng_01 "Software ID. ";
CM_ SG_ 2566767886 EndStrng_00 "Software ID. ";
CM_ SG_ 2566767886 ECU_SN_Byte_09 "The serial number of the physical ECU.";
CM_ SG_ 2566767886 ECU_SN_Byte_08 "The serial number of the physical ECU.";
CM_ SG_ 2566767886 ECU_SN_Byte_07 "The serial number of the physical ECU.";
CM_ SG_ 2566767886 ECU_SN_Byte_06 "The serial number of the physical ECU.";
CM_ SG_ 2566767886 ECU_SN_Byte_05 "The serial number of the physical ECU.";
CM_ SG_ 2566767886 ECU_SN_Byte_04 "The serial number of the physical ECU.";
CM_ SG_ 2566767886 ECU_SN_Byte_03 "The serial number of the physical ECU.";
CM_ SG_ 2566767886 ECU_SN_Byte_02 "The serial number of the physical ECU.";
CM_ SG_ 2566767886 ECU_SN_Byte_01 "The serial number of the physical ECU.";
CM_ SG_ 2566767886 ECU_PN_Byte_14 "The part number of the physical ECU.";
CM_ SG_ 2566767886 ECU_PN_Byte_13 "The part number of the physical ECU.";
CM_ SG_ 2566767886 ECU_PN_Byte_12 "The part number of the physical ECU.";
CM_ SG_ 2566767886 ECU_PN_Byte_11 "The part number of the physical ECU.";
CM_ SG_ 2566767886 ECU_PN_Byte_10 "The part number of the physical ECU.";
CM_ SG_ 2566767886 ECU_PN_Byte_09 "The part number of the physical ECU.";
CM_ SG_ 2566767886 ECU_PN_Byte_08 "The part number of the physical ECU.";
CM_ SG_ 2566767886 ECU_PN_Byte_07 "The part number of the physical ECU.";
CM_ SG_ 2566767886 ECU_PN_Byte_06 "The part number of the physical ECU.";
CM_ SG_ 2566767886 ECU_PN_Byte_05 "The part number of the physical ECU.";
CM_ SG_ 2566767886 ECU_PN_Byte_04 "The part number of the physical ECU.";
CM_ SG_ 2566767886 ECU_PN_Byte_03 "The part number of the physical ECU.";
CM_ SG_ 2566767886 ECU_PN_Byte_02 "The part number of the physical ECU.";
CM_ SG_ 2566767886 ECU_PN_Byte_01 "The part number of the physical ECU.";
CM_ SG_ 2566767886 ECU_Locat_Byte_09 "The location of the ECU within a network.";
CM_ SG_ 2566767886 ECU_Locat_Byte_08 "The location of the ECU within a network.";
CM_ SG_ 2566767886 ECU_Locat_Byte_07 "The location of the ECU within a network.";
CM_ SG_ 2566767886 ECU_Locat_Byte_06 "The location of the ECU within a network.";
CM_ SG_ 2566767886 ECU_Locat_Byte_05 "The location of the ECU within a network.";
CM_ SG_ 2566767886 ECU_Locat_Byte_04 "The location of the ECU within a network.";
CM_ SG_ 2566767886 ECU_Locat_Byte_03 "The location of the ECU within a network.";
CM_ SG_ 2566767886 ECU_Locat_Byte_02 "The location of the ECU within a network.";
CM_ SG_ 2566767886 ECU_Locat_Byte_01 "The location of the ECU within a network.";
CM_ SG_ 2566767886 ECU_HW_Id_Byte_14 "The part number of the physical ECU.";
CM_ SG_ 2566767886 ECU_HW_Id_Byte_13 "The part number of the physical ECU.";
CM_ SG_ 2566767886 ECU_HW_Id_Byte_12 "The part number of the physical ECU.";
CM_ SG_ 2566767886 ECU_HW_Id_Byte_11 "The part number of the physical ECU.";
CM_ SG_ 2566767886 ECU_HW_Id_Byte_10 "The part number of the physical ECU.";
CM_ SG_ 2566767886 ECU_HW_Id_Byte_09 "The part number of the physical ECU.";
CM_ SG_ 2566767886 ECU_HW_Id_Byte_08 "The part number of the physical ECU.";
CM_ SG_ 2566767886 ECU_HW_Id_Byte_07 "The part number of the physical ECU.";
CM_ SG_ 2566767886 ECU_HW_Id_Byte_06 "The part number of the physical ECU.";
CM_ SG_ 2566767886 ECU_HW_Id_Byte_05 "The part number of the physical ECU.";
CM_ SG_ 2566767886 ECU_HW_Id_Byte_04 "The part number of the physical ECU.";
CM_ SG_ 2566767886 ECU_HW_Id_Byte_03 "The part number of the physical ECU.";
CM_ SG_ 2566767886 ECU_HW_Id_Byte_02 "The part number of the physical ECU.";
CM_ SG_ 2566767886 ECU_HW_Id_Byte_01 "The part number of the physical ECU.";
CM_ SG_ 2566767886 ECU_Locat "The location of the ECU within a network.";
CM_ SG_ 2566767886 ECU_PN "The part number of the physical ECU.";
CM_ SG_ 2566767886 ECU_SN "The serial number of the physical ECU.";
CM_ SG_ 2566767886 ECU_Typ "The type of ECU.  One example of a use of the ECU type could be for classifying ECU capabilities, such as I/O.";
CM_ SG_ 2566767886 ECUHardwareVersionIdentification "The part number of the physical ECU.";
CM_ BO_ 2566837006 "Diagnostic data clear/Reset for active DTCs";
CM_ BO_ 2566835214 "Diagnostic data clear/reset of previously active DTCs.";
CM_ BO_ 2566834702 "Active diagnostic trouble codes";
CM_ SG_ 2566834702 AmbrWarnLmp "This lamp is used to relay trouble code information that is reporting a problem with the vehicle system but the vehicle need...";
CM_ SG_ 2566834702 DTC_01 "Diagnostic Trouble Code";
CM_ SG_ 2566834702 DTC_02 "Diagnostic Trouble Code";
CM_ SG_ 2566834702 DTC_03 "Diagnostic Trouble Code";
CM_ SG_ 2566834702 DTC_04 "Diagnostic Trouble Code";
CM_ SG_ 2566834702 DTC_05 "Diagnostic Trouble Code";
CM_ SG_ 2566834702 DTC_06 "Diagnostic Trouble Code";
CM_ SG_ 2566834702 DTC_07 "Diagnostic Trouble Code";
CM_ SG_ 2566834702 DTC_08 "Diagnostic Trouble Code";
CM_ SG_ 2566834702 DTC_09 "Diagnostic Trouble Code";
CM_ SG_ 2566834702 DTC_10 "Diagnostic Trouble Code";
CM_ SG_ 2566834702 DTC_11 "Diagnostic Trouble Code";
CM_ SG_ 2566834702 DTC_12 "Diagnostic Trouble Code";
CM_ SG_ 2566834702 DTC_13 "Diagnostic Trouble Code";
CM_ SG_ 2566834702 DTC_14 "Diagnostic Trouble Code";
CM_ SG_ 2566834702 DTC_15 "Diagnostic Trouble Code";
CM_ SG_ 2566834702 DTC_16 "Diagnostic Trouble Code";
CM_ SG_ 2566834702 DTC_17 "Diagnostic Trouble Code";
CM_ SG_ 2566834702 DTC_18 "Diagnostic Trouble Code";
CM_ SG_ 2566834702 DTC_19 "Diagnostic Trouble Code";
CM_ SG_ 2566834702 DTC_20 "Diagnostic Trouble Code";
CM_ SG_ 2566834702 FlashAmbrWarnLmpAWL "This parameter provides the capability to flash the AWL (SPN 3040).";
CM_ SG_ 2566834702 FlashMIL "This parameter provides the capability to flash the MIL (SPN 3038).";
CM_ SG_ 2566834702 FlashProtLmp "This parameter provides the capability to flash the engine protect lamp (SPN 3041).";
CM_ SG_ 2566834702 FlashRedStopLmpRSL "This parameter provides the capability to flash the RSL (SPN 3039).";
CM_ SG_ 2566834702 MIL "A lamp used to relay only emissions-related trouble code information.";
CM_ SG_ 2566834702 ProtLmp "This lamp is used to relay trouble code informatio that is reporting a problem with a vehicle system that is most...";
CM_ SG_ 2566834702 RedStopLmp "This lamp is used to relay trouble code information that is of a severe enought condition that it warrants stopping the vehicle.";
CM_ BO_ 2566834958 "Previously active diagnostic trouble codes";
CM_ SG_ 2566834958 AmbrWarnLmp "This lamp is used to relay trouble code information that is reporting a problem with the vehicle system but the vehicle need...";
CM_ SG_ 2566834958 DTC_01 "Diagnostic Trouble Code";
CM_ SG_ 2566834958 DTC_02 "Diagnostic Trouble Code";
CM_ SG_ 2566834958 DTC_03 "Diagnostic Trouble Code";
CM_ SG_ 2566834958 DTC_04 "Diagnostic Trouble Code";
CM_ SG_ 2566834958 DTC_05 "Diagnostic Trouble Code";
CM_ SG_ 2566834958 DTC_06 "Diagnostic Trouble Code";
CM_ SG_ 2566834958 DTC_07 "Diagnostic Trouble Code";
CM_ SG_ 2566834958 DTC_08 "Diagnostic Trouble Code";
CM_ SG_ 2566834958 DTC_09 "Diagnostic Trouble Code";
CM_ SG_ 2566834958 DTC_10 "Diagnostic Trouble Code";
CM_ SG_ 2566834958 DTC_11 "Diagnostic Trouble Code";
CM_ SG_ 2566834958 DTC_12 "Diagnostic Trouble Code";
CM_ SG_ 2566834958 DTC_13 "Diagnostic Trouble Code";
CM_ SG_ 2566834958 DTC_14 "Diagnostic Trouble Code";
CM_ SG_ 2566834958 DTC_15 "Diagnostic Trouble Code";
CM_ SG_ 2566834958 DTC_16 "Diagnostic Trouble Code";
CM_ SG_ 2566834958 DTC_17 "Diagnostic Trouble Code";
CM_ SG_ 2566834958 DTC_18 "Diagnostic Trouble Code";
CM_ SG_ 2566834958 DTC_19 "Diagnostic Trouble Code";
CM_ SG_ 2566834958 DTC_20 "Diagnostic Trouble Code";
CM_ SG_ 2566834958 FlashAmbrWarnLmpAWL "This parameter provides the capability to flash the AWL (SPN 3040).";
CM_ SG_ 2566834958 FlashMIL "This parameter provides the capability to flash the MIL (SPN 3038).";
CM_ SG_ 2566834958 FlashProtLmp "This parameter provides the capability to flash the engine protect lamp (SPN 3041).";
CM_ SG_ 2566834958 FlashRedStopLmpRSL "This parameter provides the capability to flash the RSL (SPN 3039).";
CM_ SG_ 2566834958 MIL "A lamp used to relay only emissions-related trouble code information.";
CM_ SG_ 2566834958 ProtLmp "This lamp is used to relay trouble code informatio that is reporting a problem with a vehicle system that is most...";
CM_ SG_ 2566834958 RedStopLmp "This lamp is used to relay trouble code information that is of a severe enought condition that it warrants stopping the vehicle.";
CM_ BO_ 2565799694 "Address Claimed";
CM_ SG_ 2565799694 Rsrvd_1Bit "Set to 0 for J1939-81";
CM_ BO_ 2632777486 "Transport Protocol - Connection Management";
CM_ SG_ 2632777486 TotNumPktEoMA "Total number of packets for BAM message.Total number of packets received for RTS/CTS message.Total number of packets for RTS/CTS message.";
CM_ SG_ 2632777486 ConnAbrtReason "Reason for connection abort message.";
CM_ SG_ 2632777486 MaxNumPktTPCM_RTS "Maximum number of packets for RTS/CTS message.";
CM_ SG_ 2632777486 NumPktSentTPCM_CTS "Number of Packets that can be sent (TP.CM_CTS)";
CM_ SG_ 2632777486 NxtPktNumSentTPCM_CTS "Next Packet Number to be sent (TP.CM_CTS)";
CM_ SG_ 2632777486 TotMsgSizeBAM "Total message size (in bytes) for BAM message.Total message size (in bytes) for RTS/CTS message.Total message size (in bytes) for RTS/CTS message.";
CM_ SG_ 2632777486 TotMsgSizeEoMA "Total message size (in bytes) for BAM message.Total message size (in bytes) for RTS/CTS message.Total message size (in bytes) for RTS/CTS message.";
CM_ SG_ 2632777486 TotMsgSizeTPCM_RTS "Total message size (in bytes) for BAM message.Total message size (in bytes) for RTS/CTS message.Total message size (in bytes) for RTS/CTS message.";
CM_ SG_ 2632777486 TotNumPktBAM "Total number of packets for BAM message.Total number of packets received for RTS/CTS message.Total number of packets for RTS/CTS message.";
CM_ SG_ 2632777486 TotNumPktTPCM_RTS "Total number of packets for BAM message.Total number of packets received for RTS/CTS message.Total number of packets for RTS/CTS message.";
CM_ BO_ 2565352206 "The Acknowledgment PG is used to provide a handshake mechanism between transmitting and receiving devices";
CM_ SG_ 2565352206 GrpFunctValAck "Group Function of PGN being acknowledged. This field identifies for a device the specific group function of a PGN being acknowledged or declined.  This field is not used if the PGN being acknowledged or declined is not a group function PGN.";
CM_ SG_ 2565352206 PGN_RQST2_0E_28 "PGN which is requested by Request2 message";
CM_ BO_ 2560830222 "This message shall provide the applicable lamp for each individual DTC";
CM_ SG_ 2560830222 DTC_01 "Diagnostic Trouble Code";
CM_ SG_ 2560830222 DTCxAmbrWarnLmpSupp_andSts "Lamp support status";
CM_ SG_ 2560830222 DTCxFlashAmbrWarnLmpSupp_andSts "Lamp support status. Not evaluated by ECM.";
CM_ SG_ 2560830222 DTCxFlashMIL_Supp_andSts "Lamp support status. Not evaluated by ECM.";
CM_ SG_ 2560830222 DTCxFlashProtLmpSupp_andSts "Lamp support status. Not evaluated by ECM.";
CM_ SG_ 2560830222 DTCxFlashRedStopLmpSupp_andSts "Lamp support status. Not evaluated by ECM.";
CM_ SG_ 2560830222 DTCxMIL_Supp_andSts "Lamp support status";
CM_ SG_ 2560830222 DTCxProtLmpSupp_andSts "Lamp support status";
CM_ SG_ 2560830222 DTCxRedStopLmpSupp_andSts "Lamp support status";
CM_ BO_ 2565537579 "Used to Request a PGN from network device or devices.";
CM_ SG_ 2565537579 PGN_RQST_2B "ACKN on PGN which is requested by Request message";
CM_ BO_ 2565475883 "Used to Request a PGN from network device or devices.";
CM_ SG_ 2565475883 PGN_RQST_2B_0E "Whenever it is necessary to identify a Parameter Group Number in the data field of a CAN data frame, it will be expressed in 24 bits.";
CM_ BO_ 2564487438 "Reserved for ISO 15765";
CM_ SG_ 2564487438 ProtocCntrlInfo "Part of Network Protocol Control Information (N_PCI) of a ISO 15765 message.";
CM_ BO_ 2564427513 "Reserved for ISO 15765";
CM_ SG_ 2564427513 ProtocCntrlInfo "Part of Network Protocol Control Information (N_PCI) of a ISO 15765 message.";
CM_ BO_ 2565351438 "The Acknowledgment PG is used to provide a handshake mechanism between transmitting and receiving devices";
CM_ SG_ 2565351438 GrpFunctValAck "Group Function of PGN being acknowledged. This field identifies for a device the specific group function of a PGN being acknowledged or declined.  This field is not used if the PGN being acknowledged or declined is not a group function PGN.";
CM_ SG_ 2565351438 PGN_RQST2_0E_28 "PGN which is requested by Request2 message";
CM_ BO_ 2560829454 "This message shall provide the applicable lamp for each individual DTC";
CM_ SG_ 2560829454 DTC_01 "Diagnostic Trouble Code";
CM_ SG_ 2560829454 DTCxAmbrWarnLmpSupp_andSts "Lamp support status";
CM_ SG_ 2560829454 DTCxFlashAmbrWarnLmpSupp_andSts "Lamp support status. Not evaluated by ECM.";
CM_ SG_ 2560829454 DTCxFlashMIL_Supp_andSts "Lamp support status. Not evaluated by ECM.";
CM_ SG_ 2560829454 DTCxFlashProtLmpSupp_andSts "Lamp support status. Not evaluated by ECM.";
CM_ SG_ 2560829454 DTCxFlashRedStopLmpSupp_andSts "Lamp support status. Not evaluated by ECM.";
CM_ SG_ 2560829454 DTCxMIL_Supp_andSts "Lamp support status";
CM_ SG_ 2560829454 DTCxProtLmpSupp_andSts "Lamp support status";
CM_ SG_ 2560829454 DTCxRedStopLmpSupp_andSts "Lamp support status";
CM_ BO_ 2565537576 "Used to Request a PGN from network device or devices.";
CM_ SG_ 2565537576 PGN_RQST_28 "ACKN on PGN which is requested by Request message";
CM_ BO_ 2565475880 "Used to Request a PGN from network device or devices.";
CM_ SG_ 2565475880 PGN_RQST_28_0E "Whenever it is necessary to identify a Parameter Group Number in the data field of a CAN data frame, it will be expressed in 24 bits.";
CM_ BO_ 2564489209 "UDS or Keyword 2000 protocol. Reserved for ISO 15765.";
CM_ SG_ 2564489209 ProtocCntrlInfo "Part of Network Protocol Control Information (N_PCI) of a ISO 15765 message.";
CM_ BO_ 2365475111 "Ground-based Speed and Distance";
CM_ BO_ 2499803662 "Used for information on brake control.";
CM_ SG_ 2499803662 MsgCnt "Init Value 12. The transmitter will increase the counter in every cycle,  0 to 11 and then wrap.14 Error, 15 NA. Used to detect situations where the transmitting ECU malfunction repeats the same frame all the time";
CM_ SG_ 2499803662 MsgChksum_3 "The message checksum is used to verify the signal path from the transmitting device to the receiving device. The message checksum is calculated using the first 7 data bytes, the message counter and the bytes of the message identifier. It is calculated...";
CM_ SG_ 2499803662 AmbrWarnLmp "This lamp is used to relay trouble code information that is reporting a problem with the vehicle system but the vehicle need...";
CM_ SG_ 2499803662 PBrakeMode "Not relevant for CNHi";
CM_ SG_ 2499803662 SecBrakeMode "Signal which indicates the current mode of Secondary brake function.";
CM_ SG_ 2499803662 ServBrakeMode "Signal which indicates the current mode of Service brake function.";
CM_ SG_ 2499803662 TrailBrakeCntrlMode "Trailer Brake Control Mode";
CM_ SG_ 2499803662 XPD_ActvCntrlMode "This parameter indicates which Control Mode is executed by the brake system.";
CM_ SG_ 2499803662 XPD_PrsLim "The brake system may temporarily or generally limit the maximum brake performance available for external systems.";
CM_ SG_ 2499803662 XPD_SysSts "This parameter indicates which external pressure control is allowed.";
CM_ BO_ 2564459257 "Reserved for ISO 15765";
CM_ SG_ 2564459257 ProtocCntrlInfo "Part of Network Protocol Control Information (N_PCI) of a ISO 15765 message.";
BA_DEF_ SG_  "GenSigReceiveSetting" STRING ;
BA_DEF_ SG_  "GenSigPreSetting" STRING ;
BA_DEF_ SG_  "GenSigPreIfSetting" STRING ;
BA_DEF_ SG_  "GenSigPostSetting" STRING ;
BA_DEF_ SG_  "GenSigPostIfSetting" STRING ;
BA_DEF_ SG_  "GenSigEnvVarType" ENUM  "int","float","undef";
BA_DEF_ SG_  "GenSigConditionalSend" STRING ;
BA_DEF_ SG_  "GenSigAutoGenSnd" ENUM  "No","Yes";
BA_DEF_ SG_  "GenSigAutoGenDsp" ENUM  "No","Yes";
BA_DEF_ SG_  "GenSigAssignSetting" STRING ;
BA_DEF_ SG_  "GenSigAltSetting" STRING ;
BA_DEF_ SG_  "SPN_Definition" STRING ;
BA_DEF_ SG_  "External_Reference_decod" STRING ;
BA_DEF_ SG_  "UtilizationOnNetwork" ENUM  "Used","NOT USED";
BA_DEF_ SG_  "CI_RepetitionNum" ENUM  "1","2";
BA_DEF_ SG_  "CI_RepetitionType" ENUM  "NA","1","2","3","4";
BA_DEF_ SG_  "CI_RepetitionComplemented" ENUM  "0","1","vector_leerstring";
BA_DEF_ SG_  "DDI" INT 0 65535;
BA_DEF_ SG_  "CI_FullName" STRING ;
BA_DEF_ SG_  "GenSigTimeoutTime" INT 0 3600000;
BA_DEF_ SG_  "CI_ParId" STRING ;
BA_DEF_ SG_  "CI_SLOT_Name" STRING ;
BA_DEF_ SG_  "CI_ParVersion" STRING ;
BA_DEF_ SG_  "GenSigSendType" ENUM  "Cyclic","OnWrite","OnWriteWithRepetition","OnChange","OnChangeWithRepetition","IfActive","IfActiveWithRepetition","NoSigSendType";
BA_DEF_ SG_  "GenSigInactiveValue" INT 0 2147483647;
BA_DEF_ SG_  "GenSigStartValue" INT 0 2147483647;
BA_DEF_ SG_  "GenSigEVName" STRING ;
BA_DEF_ SG_  "SPN" INT 0 524287;
BA_DEF_ SG_  "SigType" ENUM  "Default","Range","RangeSigned","ASCII","Discrete","Control","ReferencePGN","DTC","StringDelimiter","StringLength","StringLengthControl";
BA_DEF_ SG_  "GenSigILSupport" ENUM  "Yes","No";
BA_DEF_ BO_  "ShowSignals" INT -1 0;
BA_DEF_ BO_  "GroupSignals" INT 1 100;
BA_DEF_ BO_  "PGN_Definition" STRING ;
BA_DEF_ BO_  "External_Reference" STRING ;
BA_DEF_ BO_  "SingleFrame" INT 0 1;
BA_DEF_ BO_  "CI_AllowedLostMessages" ENUM  "NA","0","1","2","3","4";
BA_DEF_ BO_  "CI_AliveTimeout" INT 0 3600000;
BA_DEF_ BO_  "TpJ1939VarDlc" ENUM  "No","Yes";
BA_DEF_ BO_  "CI_ShowSignals" INT -1 0;
BA_DEF_ BO_  "CI_PgVersion" STRING ;
BA_DEF_ BO_  "CI_GroupSignals" INT 1 100;
BA_DEF_ BO_  "DiagUUDTResponse" ENUM  "No","Yes";
BA_DEF_ BO_  "DiagState" ENUM  "No","Yes";
BA_DEF_ BO_  "DiagResponse" ENUM  "No","Yes";
BA_DEF_ BO_  "DiagRequest" ENUM  "No","Yes";
BA_DEF_ BO_  "DiagConnection" INT 0 65535;
BA_DEF_ BO_  "GenMsgNrOfRepetition" INT 0 1000000;
BA_DEF_ BO_  "GenMsgILSupport" ENUM  "No","Yes";
BA_DEF_ BO_  "GenMsgFastOnStart" INT 0 100000;
BA_DEF_ BO_  "GenMsgCycleTimeFast" INT 0 3600000;
BA_DEF_ BO_  "GenMsgStartDelayTime" INT 0 100000;
BA_DEF_ BO_  "GenMsgDelayTime" INT 0 3600000;
BA_DEF_ BO_  "VFrameFormat" ENUM  "StandardCAN","ExtendedCAN","reserved","J1939PG";
BA_DEF_ BO_  "GenMsgCycleTime" INT 0 3600000;
BA_DEF_ BO_  "GenMsgRequestable" INT 0 1;
BA_DEF_ BO_  "GenMsgSendType" ENUM  "cyclic","reserved","cyclicIfActive","reserved","reserved","reserved","reserved","reserved","noMsgSendType";
BA_DEF_DEF_  "GenSigReceiveSetting" "";
BA_DEF_DEF_  "GenSigPreSetting" "";
BA_DEF_DEF_  "GenSigPreIfSetting" "";
BA_DEF_DEF_  "GenSigPostSetting" "";
BA_DEF_DEF_  "GenSigPostIfSetting" "";
BA_DEF_DEF_  "GenSigEnvVarType" "undef";
BA_DEF_DEF_  "GenSigConditionalSend" "";
BA_DEF_DEF_  "GenSigAutoGenSnd" "";
BA_DEF_DEF_  "GenSigAutoGenDsp" "";
BA_DEF_DEF_  "GenSigAssignSetting" "";
BA_DEF_DEF_  "GenSigAltSetting" "";
BA_DEF_DEF_  "SPN_Definition" "";
BA_DEF_DEF_  "External_Reference_decod" "";
BA_DEF_DEF_  "UtilizationOnNetwork" "Used";
BA_DEF_DEF_  "CI_RepetitionNum" "1";
BA_DEF_DEF_  "CI_RepetitionType" "NA";
BA_DEF_DEF_  "CI_RepetitionComplemented" "0";
BA_DEF_DEF_  "DDI" 0;
BA_DEF_DEF_  "CI_FullName" "";
BA_DEF_DEF_  "GenSigTimeoutTime" 0;
BA_DEF_DEF_  "CI_ParId" "";
BA_DEF_DEF_  "CI_SLOT_Name" "0";
BA_DEF_DEF_  "CI_ParVersion" "0";
BA_DEF_DEF_  "GenSigSendType" "NoSigSendType";
BA_DEF_DEF_  "GenSigInactiveValue" 0;
BA_DEF_DEF_  "GenSigStartValue" 0;
BA_DEF_DEF_  "GenSigEVName" "Env@Nodename_@Signame";
BA_DEF_DEF_  "SPN" 0;
BA_DEF_DEF_  "SigType" "Default";
BA_DEF_DEF_  "GenSigILSupport" "Yes";
BA_DEF_DEF_  "ShowSignals" -1;
BA_DEF_DEF_  "GroupSignals" 1;
BA_DEF_DEF_  "PGN_Definition" "N/A";
BA_DEF_DEF_  "External_Reference" "";
BA_DEF_DEF_  "SingleFrame" 1;
BA_DEF_DEF_  "CI_AllowedLostMessages" "NA";
BA_DEF_DEF_  "CI_AliveTimeout" 0;
BA_DEF_DEF_  "TpJ1939VarDlc" "No";
BA_DEF_DEF_  "CI_ShowSignals" -1;
BA_DEF_DEF_  "CI_PgVersion" "0";
BA_DEF_DEF_  "CI_GroupSignals" 1;
BA_DEF_DEF_  "DiagUUDTResponse" "No";
BA_DEF_DEF_  "DiagState" "No";
BA_DEF_DEF_  "DiagResponse" "No";
BA_DEF_DEF_  "DiagRequest" "No";
BA_DEF_DEF_  "DiagConnection" 0;
BA_DEF_DEF_  "GenMsgNrOfRepetition" 0;
BA_DEF_DEF_  "GenMsgILSupport" "Yes";
BA_DEF_DEF_  "GenMsgFastOnStart" 0;
BA_DEF_DEF_  "GenMsgCycleTimeFast" 0;
BA_DEF_DEF_  "GenMsgStartDelayTime" 0;
BA_DEF_DEF_  "GenMsgDelayTime" 1;
BA_DEF_DEF_  "VFrameFormat" "J1939PG";
BA_DEF_DEF_  "GenMsgCycleTime" 0;
BA_DEF_DEF_  "GenMsgRequestable" 0;
BA_DEF_DEF_  "GenMsgSendType" "noMsgSendType";
BA_ "TpJ1939VarDlc" BO_ 2565799719 1;
BA_ "CI_ShowSignals" BO_ 2565799719 0;
BA_ "TpJ1939VarDlc" BO_ 2566838798 1;
BA_ "CI_GroupSignals" BO_ 2566838798 4;
BA_ "GenMsgRequestable" BO_ 2566838798 1;
BA_ "TpJ1939VarDlc" BO_ 2566835470 1;
BA_ "CI_GroupSignals" BO_ 2566835470 2;
BA_ "GenMsgRequestable" BO_ 2566835470 1;
BA_ "TpJ1939VarDlc" BO_ 2566843150 1;
BA_ "CI_ShowSignals" BO_ 2566843150 0;
BA_ "GenMsgRequestable" BO_ 2566843150 1;
BA_ "TpJ1939VarDlc" BO_ 2566767886 1;
BA_ "CI_GroupSignals" BO_ 2566767886 3;
BA_ "GenMsgRequestable" BO_ 2566767886 1;
BA_ "TpJ1939VarDlc" BO_ 2566837006 1;
BA_ "GenMsgRequestable" BO_ 2566837006 1;
BA_ "TpJ1939VarDlc" BO_ 2566835214 1;
BA_ "CI_GroupSignals" BO_ 2566835214 3;
BA_ "GenMsgRequestable" BO_ 2566835214 1;
BA_ "CI_AliveTimeout" BO_ 2566834702 4000;
BA_ "TpJ1939VarDlc" BO_ 2566834702 1;
BA_ "CI_ShowSignals" BO_ 2566834702 0;
BA_ "CI_GroupSignals" BO_ 2566834702 3;
BA_ "GenMsgCycleTime" BO_ 2566834702 1000;
BA_ "GenMsgSendType" BO_ 2566834702 0;
BA_ "TpJ1939VarDlc" BO_ 2566834958 1;
BA_ "CI_ShowSignals" BO_ 2566834958 0;
BA_ "CI_GroupSignals" BO_ 2566834958 2;
BA_ "GenMsgRequestable" BO_ 2566834958 1;
BA_ "CI_ShowSignals" BO_ 2565799694 0;
BA_ "GenMsgRequestable" BO_ 2565799694 1;
BA_ "TpJ1939VarDlc" BO_ 2632777486 1;
BA_ "CI_ShowSignals" BO_ 2632777486 0;
BA_ "CI_ShowSignals" BO_ 2565352206 0;
BA_ "CI_PgVersion" BO_ 2565352206 "-1";
BA_ "CI_GroupSignals" BO_ 2565352206 9;
BA_ "TpJ1939VarDlc" BO_ 2560830222 1;
BA_ "CI_ShowSignals" BO_ 2560830222 0;
BA_ "GenMsgRequestable" BO_ 2560830222 1;
BA_ "CI_PgVersion" BO_ 2565537579 "-1";
BA_ "CI_GroupSignals" BO_ 2565537579 34;
BA_ "TpJ1939VarDlc" BO_ 2565475883 1;
BA_ "CI_GroupSignals" BO_ 2565475883 71;
BA_ "GenMsgRequestable" BO_ 2565475883 1;
BA_ "TpJ1939VarDlc" BO_ 2564487438 1;
BA_ "CI_ShowSignals" BO_ 2564487438 0;
BA_ "DiagResponse" BO_ 2564487438 1;
BA_ "GenMsgRequestable" BO_ 2564487438 1;
BA_ "TpJ1939VarDlc" BO_ 2564427513 1;
BA_ "DiagRequest" BO_ 2564427513 1;
BA_ "GenMsgRequestable" BO_ 2564427513 1;
BA_ "CI_ShowSignals" BO_ 2565351438 0;
BA_ "CI_PgVersion" BO_ 2565351438 "-1";
BA_ "CI_GroupSignals" BO_ 2565351438 7;
BA_ "TpJ1939VarDlc" BO_ 2560829454 1;
BA_ "CI_ShowSignals" BO_ 2560829454 0;
BA_ "GenMsgRequestable" BO_ 2560829454 1;
BA_ "CI_PgVersion" BO_ 2565537576 "-1";
BA_ "CI_GroupSignals" BO_ 2565537576 14;
BA_ "TpJ1939VarDlc" BO_ 2565475880 1;
BA_ "CI_GroupSignals" BO_ 2565475880 40;
BA_ "GenMsgRequestable" BO_ 2565475880 1;
BA_ "TpJ1939VarDlc" BO_ 2564489209 1;
BA_ "CI_ShowSignals" BO_ 2564489209 0;
BA_ "GenMsgRequestable" BO_ 2564489209 1;
BA_ "GenMsgCycleTime" BO_ 2566848701 50;
BA_ "GenMsgSendType" BO_ 2566848701 0;
BA_ "CI_AliveTimeout" BO_ 2365475111 400;
BA_ "GenMsgStartDelayTime" BO_ 2365475111 80;
BA_ "GenMsgCycleTime" BO_ 2365475111 100;
BA_ "GenMsgSendType" BO_ 2365475111 0;
BA_ "CI_AliveTimeout" BO_ 2499803662 300;
BA_ "TpJ1939VarDlc" BO_ 2499803662 1;
BA_ "GenMsgCycleTimeFast" BO_ 2499803662 10;
BA_ "GenMsgCycleTime" BO_ 2499803662 100;
BA_ "GenMsgSendType" BO_ 2499803662 0;
BA_ "TpJ1939VarDlc" BO_ 2564459257 1;
BA_ "CI_ShowSignals" BO_ 2564459257 0;
BA_ "DiagRequest" BO_ 2564459257 1;
BA_ "CI_FullName" SG_ 2565799719 Rsrvd_1Bit "Reserved 1 Bit";
BA_ "CI_ParId" SG_ 2565799719 Rsrvd_1Bit "ESMD_23062";
BA_ "GenSigAutoGenSnd" SG_ 2565799719 ArbAddrCap 0;
BA_ "GenSigAutoGenDsp" SG_ 2565799719 ArbAddrCap 0;
BA_ "CI_RepetitionComplemented" SG_ 2565799719 ArbAddrCap 2;
BA_ "CI_FullName" SG_ 2565799719 ArbAddrCap "Arbitrary Address Capable";
BA_ "CI_ParId" SG_ 2565799719 ArbAddrCap "ESMD_08115";
BA_ "SPN" SG_ 2565799719 ArbAddrCap 2844;
BA_ "GenSigAutoGenSnd" SG_ 2565799719 ECU_Inst 0;
BA_ "GenSigAutoGenDsp" SG_ 2565799719 ECU_Inst 0;
BA_ "CI_RepetitionComplemented" SG_ 2565799719 ECU_Inst 2;
BA_ "CI_FullName" SG_ 2565799719 ECU_Inst "ECU Instance";
BA_ "CI_ParId" SG_ 2565799719 ECU_Inst "ESMD_08387";
BA_ "SPN" SG_ 2565799719 ECU_Inst 2840;
BA_ "GenSigAutoGenSnd" SG_ 2565799719 Funct 0;
BA_ "GenSigAutoGenDsp" SG_ 2565799719 Funct 0;
BA_ "CI_RepetitionComplemented" SG_ 2565799719 Funct 2;
BA_ "CI_FullName" SG_ 2565799719 Funct "Function";
BA_ "CI_ParId" SG_ 2565799719 Funct "ESMD_08663";
BA_ "SPN" SG_ 2565799719 Funct 2841;
BA_ "GenSigAutoGenSnd" SG_ 2565799719 FunctInst 0;
BA_ "GenSigAutoGenDsp" SG_ 2565799719 FunctInst 0;
BA_ "CI_RepetitionComplemented" SG_ 2565799719 FunctInst 2;
BA_ "CI_FullName" SG_ 2565799719 FunctInst "Function Instance";
BA_ "CI_ParId" SG_ 2565799719 FunctInst "ESMD_08670";
BA_ "SPN" SG_ 2565799719 FunctInst 2839;
BA_ "GenSigAutoGenSnd" SG_ 2565799719 IdNum 0;
BA_ "GenSigAutoGenDsp" SG_ 2565799719 IdNum 0;
BA_ "CI_RepetitionComplemented" SG_ 2565799719 IdNum 2;
BA_ "CI_FullName" SG_ 2565799719 IdNum "Identity Number";
BA_ "CI_ParId" SG_ 2565799719 IdNum "ESMD_08726";
BA_ "SPN" SG_ 2565799719 IdNum 2837;
BA_ "GenSigAutoGenSnd" SG_ 2565799719 IndstryGrp 0;
BA_ "GenSigAutoGenDsp" SG_ 2565799719 IndstryGrp 0;
BA_ "CI_RepetitionComplemented" SG_ 2565799719 IndstryGrp 2;
BA_ "CI_FullName" SG_ 2565799719 IndstryGrp "Industry Group";
BA_ "CI_ParId" SG_ 2565799719 IndstryGrp "ESMD_02136";
BA_ "SPN" SG_ 2565799719 IndstryGrp 2846;
BA_ "GenSigAutoGenSnd" SG_ 2565799719 ManufctCod 0;
BA_ "GenSigAutoGenDsp" SG_ 2565799719 ManufctCod 0;
BA_ "CI_RepetitionComplemented" SG_ 2565799719 ManufctCod 2;
BA_ "CI_FullName" SG_ 2565799719 ManufctCod "Manufacturer Code";
BA_ "CI_ParId" SG_ 2565799719 ManufctCod "ESMD_08852";
BA_ "SPN" SG_ 2565799719 ManufctCod 2838;
BA_ "SigType" SG_ 2565799719 ManufctCod 1;
BA_ "GenSigAutoGenSnd" SG_ 2565799719 VehSys 0;
BA_ "GenSigAutoGenDsp" SG_ 2565799719 VehSys 0;
BA_ "CI_RepetitionComplemented" SG_ 2565799719 VehSys 2;
BA_ "CI_FullName" SG_ 2565799719 VehSys "Vehicle system";
BA_ "CI_ParId" SG_ 2565799719 VehSys "ESMD_16375";
BA_ "SPN" SG_ 2565799719 VehSys 2842;
BA_ "GenSigAutoGenSnd" SG_ 2565799719 VehSysInst 0;
BA_ "GenSigAutoGenDsp" SG_ 2565799719 VehSysInst 0;
BA_ "CI_RepetitionComplemented" SG_ 2565799719 VehSysInst 2;
BA_ "CI_FullName" SG_ 2565799719 VehSysInst "Vehicle System Instance";
BA_ "CI_ParId" SG_ 2565799719 VehSysInst "ESMD_09571";
BA_ "SPN" SG_ 2565799719 VehSysInst 2843;
BA_ "CI_FullName" SG_ 2566838798 SupplrSW_VerNum_Byte_13 "Software Identification";
BA_ "CI_ParId" SG_ 2566838798 SupplrSW_VerNum_Byte_13 "ESMD_03139";
BA_ "CI_SLOT_Name" SG_ 2566838798 SupplrSW_VerNum_Byte_13 "SAEatad0200";
BA_ "SPN" SG_ 2566838798 SupplrSW_VerNum_Byte_13 234;
BA_ "SigType" SG_ 2566838798 SupplrSW_VerNum_Byte_13 3;
BA_ "CI_FullName" SG_ 2566838798 SupplrSW_VerNum_Byte_14 "Software Identification";
BA_ "CI_ParId" SG_ 2566838798 SupplrSW_VerNum_Byte_14 "ESMD_03139";
BA_ "CI_SLOT_Name" SG_ 2566838798 SupplrSW_VerNum_Byte_14 "SAEatad0200";
BA_ "SPN" SG_ 2566838798 SupplrSW_VerNum_Byte_14 234;
BA_ "SigType" SG_ 2566838798 SupplrSW_VerNum_Byte_14 3;
BA_ "CI_FullName" SG_ 2566838798 WarnErrDbVer "Software Identification";
BA_ "CI_ParId" SG_ 2566838798 WarnErrDbVer "ESMD_03139";
BA_ "CI_SLOT_Name" SG_ 2566838798 WarnErrDbVer "SAEatad0200";
BA_ "SPN" SG_ 2566838798 WarnErrDbVer 234;
BA_ "SigType" SG_ 2566838798 WarnErrDbVer 8;
BA_ "CI_FullName" SG_ 2566838798 ApplSW_PN "Software Identification";
BA_ "CI_ParId" SG_ 2566838798 ApplSW_PN "ESMD_03139";
BA_ "CI_SLOT_Name" SG_ 2566838798 ApplSW_PN "SAEatad0200";
BA_ "SPN" SG_ 2566838798 ApplSW_PN 234;
BA_ "SigType" SG_ 2566838798 ApplSW_PN 8;
BA_ "CI_FullName" SG_ 2566838798 ApplSW_PN_Byte_01 "Software Identification";
BA_ "CI_ParId" SG_ 2566838798 ApplSW_PN_Byte_01 "ESMD_03139";
BA_ "CI_SLOT_Name" SG_ 2566838798 ApplSW_PN_Byte_01 "SAEatad0200";
BA_ "SPN" SG_ 2566838798 ApplSW_PN_Byte_01 234;
BA_ "SigType" SG_ 2566838798 ApplSW_PN_Byte_01 3;
BA_ "CI_FullName" SG_ 2566838798 ApplSW_PN_Byte_02 "Software Identification";
BA_ "CI_ParId" SG_ 2566838798 ApplSW_PN_Byte_02 "ESMD_03139";
BA_ "CI_SLOT_Name" SG_ 2566838798 ApplSW_PN_Byte_02 "SAEatad0200";
BA_ "SPN" SG_ 2566838798 ApplSW_PN_Byte_02 234;
BA_ "SigType" SG_ 2566838798 ApplSW_PN_Byte_02 3;
BA_ "CI_FullName" SG_ 2566838798 ApplSW_PN_Byte_03 "Software Identification";
BA_ "CI_ParId" SG_ 2566838798 ApplSW_PN_Byte_03 "ESMD_03139";
BA_ "CI_SLOT_Name" SG_ 2566838798 ApplSW_PN_Byte_03 "SAEatad0200";
BA_ "SPN" SG_ 2566838798 ApplSW_PN_Byte_03 234;
BA_ "SigType" SG_ 2566838798 ApplSW_PN_Byte_03 3;
BA_ "CI_FullName" SG_ 2566838798 ApplSW_PN_Byte_04 "Software Identification";
BA_ "CI_ParId" SG_ 2566838798 ApplSW_PN_Byte_04 "ESMD_03139";
BA_ "CI_SLOT_Name" SG_ 2566838798 ApplSW_PN_Byte_04 "SAEatad0200";
BA_ "SPN" SG_ 2566838798 ApplSW_PN_Byte_04 234;
BA_ "SigType" SG_ 2566838798 ApplSW_PN_Byte_04 3;
BA_ "CI_FullName" SG_ 2566838798 ApplSW_PN_Byte_05 "Software Identification";
BA_ "CI_ParId" SG_ 2566838798 ApplSW_PN_Byte_05 "ESMD_03139";
BA_ "CI_SLOT_Name" SG_ 2566838798 ApplSW_PN_Byte_05 "SAEatad0200";
BA_ "SPN" SG_ 2566838798 ApplSW_PN_Byte_05 234;
BA_ "SigType" SG_ 2566838798 ApplSW_PN_Byte_05 3;
BA_ "CI_FullName" SG_ 2566838798 ApplSW_PN_Byte_06 "Software Identification";
BA_ "CI_ParId" SG_ 2566838798 ApplSW_PN_Byte_06 "ESMD_03139";
BA_ "CI_SLOT_Name" SG_ 2566838798 ApplSW_PN_Byte_06 "SAEatad0200";
BA_ "SPN" SG_ 2566838798 ApplSW_PN_Byte_06 234;
BA_ "SigType" SG_ 2566838798 ApplSW_PN_Byte_06 3;
BA_ "CI_FullName" SG_ 2566838798 ApplSW_PN_Byte_07 "Software Identification";
BA_ "CI_ParId" SG_ 2566838798 ApplSW_PN_Byte_07 "ESMD_03139";
BA_ "CI_SLOT_Name" SG_ 2566838798 ApplSW_PN_Byte_07 "SAEatad0200";
BA_ "SPN" SG_ 2566838798 ApplSW_PN_Byte_07 234;
BA_ "SigType" SG_ 2566838798 ApplSW_PN_Byte_07 3;
BA_ "CI_FullName" SG_ 2566838798 ApplSW_PN_Byte_08 "Software Identification";
BA_ "CI_ParId" SG_ 2566838798 ApplSW_PN_Byte_08 "ESMD_03139";
BA_ "CI_SLOT_Name" SG_ 2566838798 ApplSW_PN_Byte_08 "SAEatad0200";
BA_ "SPN" SG_ 2566838798 ApplSW_PN_Byte_08 234;
BA_ "SigType" SG_ 2566838798 ApplSW_PN_Byte_08 3;
BA_ "CI_FullName" SG_ 2566838798 ApplSW_PN_Byte_09 "Software Identification";
BA_ "CI_ParId" SG_ 2566838798 ApplSW_PN_Byte_09 "ESMD_03139";
BA_ "CI_SLOT_Name" SG_ 2566838798 ApplSW_PN_Byte_09 "SAEatad0200";
BA_ "SPN" SG_ 2566838798 ApplSW_PN_Byte_09 234;
BA_ "SigType" SG_ 2566838798 ApplSW_PN_Byte_09 3;
BA_ "CI_FullName" SG_ 2566838798 ApplSW_PN_Byte_10 "Software Identification";
BA_ "CI_ParId" SG_ 2566838798 ApplSW_PN_Byte_10 "ESMD_03139";
BA_ "CI_SLOT_Name" SG_ 2566838798 ApplSW_PN_Byte_10 "SAEatad0200";
BA_ "SPN" SG_ 2566838798 ApplSW_PN_Byte_10 234;
BA_ "SigType" SG_ 2566838798 ApplSW_PN_Byte_10 3;
BA_ "CI_FullName" SG_ 2566838798 ApplSW_PN_Byte_11 "Software Identification";
BA_ "CI_ParId" SG_ 2566838798 ApplSW_PN_Byte_11 "ESMD_03139";
BA_ "CI_SLOT_Name" SG_ 2566838798 ApplSW_PN_Byte_11 "SAEatad0200";
BA_ "SPN" SG_ 2566838798 ApplSW_PN_Byte_11 234;
BA_ "SigType" SG_ 2566838798 ApplSW_PN_Byte_11 3;
BA_ "CI_FullName" SG_ 2566838798 ApplSW_PN_Byte_12 "Software Identification";
BA_ "CI_ParId" SG_ 2566838798 ApplSW_PN_Byte_12 "ESMD_03139";
BA_ "CI_SLOT_Name" SG_ 2566838798 ApplSW_PN_Byte_12 "SAEatad0200";
BA_ "SPN" SG_ 2566838798 ApplSW_PN_Byte_12 234;
BA_ "SigType" SG_ 2566838798 ApplSW_PN_Byte_12 3;
BA_ "CI_FullName" SG_ 2566838798 ApplSW_PN_Byte_13 "Software Identification";
BA_ "CI_ParId" SG_ 2566838798 ApplSW_PN_Byte_13 "ESMD_03139";
BA_ "CI_SLOT_Name" SG_ 2566838798 ApplSW_PN_Byte_13 "SAEatad0200";
BA_ "SPN" SG_ 2566838798 ApplSW_PN_Byte_13 234;
BA_ "SigType" SG_ 2566838798 ApplSW_PN_Byte_13 3;
BA_ "CI_FullName" SG_ 2566838798 ApplSW_PN_Byte_14 "Software Identification";
BA_ "CI_ParId" SG_ 2566838798 ApplSW_PN_Byte_14 "ESMD_03139";
BA_ "CI_SLOT_Name" SG_ 2566838798 ApplSW_PN_Byte_14 "SAEatad0200";
BA_ "SPN" SG_ 2566838798 ApplSW_PN_Byte_14 234;
BA_ "SigType" SG_ 2566838798 ApplSW_PN_Byte_14 3;
BA_ "SPN_Definition" SG_ 2566838798 CalibrId "N/A";
BA_ "CI_FullName" SG_ 2566838798 CalibrId "Calibration Identification";
BA_ "CI_ParId" SG_ 2566838798 CalibrId "ESMD_00885";
BA_ "CI_SLOT_Name" SG_ 2566838798 CalibrId "SAEatf0016";
BA_ "SPN" SG_ 2566838798 CalibrId 1635;
BA_ "SigType" SG_ 2566838798 CalibrId 8;
BA_ "SPN_Definition" SG_ 2566838798 CalibrId_Byte_01 "N/A";
BA_ "CI_FullName" SG_ 2566838798 CalibrId_Byte_01 "Calibration Identification";
BA_ "CI_ParId" SG_ 2566838798 CalibrId_Byte_01 "ESMD_00885";
BA_ "CI_SLOT_Name" SG_ 2566838798 CalibrId_Byte_01 "SAEatf0016";
BA_ "SPN" SG_ 2566838798 CalibrId_Byte_01 1635;
BA_ "SPN_Definition" SG_ 2566838798 CalibrId_Byte_02 "N/A";
BA_ "CI_FullName" SG_ 2566838798 CalibrId_Byte_02 "Calibration Identification";
BA_ "CI_ParId" SG_ 2566838798 CalibrId_Byte_02 "ESMD_00885";
BA_ "CI_SLOT_Name" SG_ 2566838798 CalibrId_Byte_02 "SAEatf0016";
BA_ "SPN" SG_ 2566838798 CalibrId_Byte_02 1635;
BA_ "SPN_Definition" SG_ 2566838798 CalibrId_Byte_03 "N/A";
BA_ "CI_FullName" SG_ 2566838798 CalibrId_Byte_03 "Calibration Identification";
BA_ "CI_ParId" SG_ 2566838798 CalibrId_Byte_03 "ESMD_00885";
BA_ "CI_SLOT_Name" SG_ 2566838798 CalibrId_Byte_03 "SAEatf0016";
BA_ "SPN" SG_ 2566838798 CalibrId_Byte_03 1635;
BA_ "SPN_Definition" SG_ 2566838798 CalibrId_Byte_04 "N/A";
BA_ "CI_FullName" SG_ 2566838798 CalibrId_Byte_04 "Calibration Identification";
BA_ "CI_ParId" SG_ 2566838798 CalibrId_Byte_04 "ESMD_00885";
BA_ "CI_SLOT_Name" SG_ 2566838798 CalibrId_Byte_04 "SAEatf0016";
BA_ "SPN" SG_ 2566838798 CalibrId_Byte_04 1635;
BA_ "SPN_Definition" SG_ 2566838798 CalibrId_Byte_05 "N/A";
BA_ "CI_FullName" SG_ 2566838798 CalibrId_Byte_05 "Calibration Identification";
BA_ "CI_ParId" SG_ 2566838798 CalibrId_Byte_05 "ESMD_00885";
BA_ "CI_SLOT_Name" SG_ 2566838798 CalibrId_Byte_05 "SAEatf0016";
BA_ "SPN" SG_ 2566838798 CalibrId_Byte_05 1635;
BA_ "SPN_Definition" SG_ 2566838798 CalibrId_Byte_06 "N/A";
BA_ "CI_FullName" SG_ 2566838798 CalibrId_Byte_06 "Calibration Identification";
BA_ "CI_ParId" SG_ 2566838798 CalibrId_Byte_06 "ESMD_00885";
BA_ "CI_SLOT_Name" SG_ 2566838798 CalibrId_Byte_06 "SAEatf0016";
BA_ "SPN" SG_ 2566838798 CalibrId_Byte_06 1635;
BA_ "SPN_Definition" SG_ 2566838798 CalibrId_Byte_07 "N/A";
BA_ "CI_FullName" SG_ 2566838798 CalibrId_Byte_07 "Calibration Identification";
BA_ "CI_ParId" SG_ 2566838798 CalibrId_Byte_07 "ESMD_00885";
BA_ "CI_SLOT_Name" SG_ 2566838798 CalibrId_Byte_07 "SAEatf0016";
BA_ "SPN" SG_ 2566838798 CalibrId_Byte_07 1635;
BA_ "SPN_Definition" SG_ 2566838798 CalibrId_Byte_08 "N/A";
BA_ "CI_FullName" SG_ 2566838798 CalibrId_Byte_08 "Calibration Identification";
BA_ "CI_ParId" SG_ 2566838798 CalibrId_Byte_08 "ESMD_00885";
BA_ "CI_SLOT_Name" SG_ 2566838798 CalibrId_Byte_08 "SAEatf0016";
BA_ "SPN" SG_ 2566838798 CalibrId_Byte_08 1635;
BA_ "SPN_Definition" SG_ 2566838798 CalibrId_Byte_09 "N/A";
BA_ "CI_FullName" SG_ 2566838798 CalibrId_Byte_09 "Calibration Identification";
BA_ "CI_ParId" SG_ 2566838798 CalibrId_Byte_09 "ESMD_00885";
BA_ "CI_SLOT_Name" SG_ 2566838798 CalibrId_Byte_09 "SAEatf0016";
BA_ "SPN" SG_ 2566838798 CalibrId_Byte_09 1635;
BA_ "SPN_Definition" SG_ 2566838798 CalibrId_Byte_10 "N/A";
BA_ "CI_FullName" SG_ 2566838798 CalibrId_Byte_10 "Calibration Identification";
BA_ "CI_ParId" SG_ 2566838798 CalibrId_Byte_10 "ESMD_00885";
BA_ "CI_SLOT_Name" SG_ 2566838798 CalibrId_Byte_10 "SAEatf0016";
BA_ "SPN" SG_ 2566838798 CalibrId_Byte_10 1635;
BA_ "SPN_Definition" SG_ 2566838798 CalibrId_Byte_11 "N/A";
BA_ "CI_FullName" SG_ 2566838798 CalibrId_Byte_11 "Calibration Identification";
BA_ "CI_ParId" SG_ 2566838798 CalibrId_Byte_11 "ESMD_00885";
BA_ "CI_SLOT_Name" SG_ 2566838798 CalibrId_Byte_11 "SAEatf0016";
BA_ "SPN" SG_ 2566838798 CalibrId_Byte_11 1635;
BA_ "SPN_Definition" SG_ 2566838798 CalibrId_Byte_12 "N/A";
BA_ "CI_FullName" SG_ 2566838798 CalibrId_Byte_12 "Calibration Identification";
BA_ "CI_ParId" SG_ 2566838798 CalibrId_Byte_12 "ESMD_00885";
BA_ "CI_SLOT_Name" SG_ 2566838798 CalibrId_Byte_12 "SAEatf0016";
BA_ "SPN" SG_ 2566838798 CalibrId_Byte_12 1635;
BA_ "SPN_Definition" SG_ 2566838798 CalibrId_Byte_13 "N/A";
BA_ "CI_FullName" SG_ 2566838798 CalibrId_Byte_13 "Calibration Identification";
BA_ "CI_ParId" SG_ 2566838798 CalibrId_Byte_13 "ESMD_00885";
BA_ "CI_SLOT_Name" SG_ 2566838798 CalibrId_Byte_13 "SAEatf0016";
BA_ "SPN" SG_ 2566838798 CalibrId_Byte_13 1635;
BA_ "SPN_Definition" SG_ 2566838798 CalibrId_Byte_14 "N/A";
BA_ "CI_FullName" SG_ 2566838798 CalibrId_Byte_14 "Calibration Identification";
BA_ "CI_ParId" SG_ 2566838798 CalibrId_Byte_14 "ESMD_00885";
BA_ "CI_SLOT_Name" SG_ 2566838798 CalibrId_Byte_14 "SAEatf0016";
BA_ "SPN" SG_ 2566838798 CalibrId_Byte_14 1635;
BA_ "SPN_Definition" SG_ 2566838798 CalibrId_Byte_15 "N/A";
BA_ "CI_FullName" SG_ 2566838798 CalibrId_Byte_15 "Calibration Identification";
BA_ "CI_ParId" SG_ 2566838798 CalibrId_Byte_15 "ESMD_00885";
BA_ "CI_SLOT_Name" SG_ 2566838798 CalibrId_Byte_15 "SAEatf0016";
BA_ "SPN" SG_ 2566838798 CalibrId_Byte_15 1635;
BA_ "CI_FullName" SG_ 2566838798 EndStrng_00 "Software Identification";
BA_ "CI_ParId" SG_ 2566838798 EndStrng_00 "ESMD_21930";
BA_ "CI_SLOT_Name" SG_ 2566838798 EndStrng_00 "SAEatad0200";
BA_ "GenSigStartValue" SG_ 2566838798 EndStrng_00 42;
BA_ "SigType" SG_ 2566838798 EndStrng_00 8;
BA_ "CI_FullName" SG_ 2566838798 EndStrng_01 "Software Identification";
BA_ "CI_ParId" SG_ 2566838798 EndStrng_01 "ESMD_21931";
BA_ "CI_SLOT_Name" SG_ 2566838798 EndStrng_01 "SAEatad0200";
BA_ "GenSigStartValue" SG_ 2566838798 EndStrng_01 42;
BA_ "SigType" SG_ 2566838798 EndStrng_01 8;
BA_ "CI_FullName" SG_ 2566838798 EndStrng_02 "Software Identification";
BA_ "CI_ParId" SG_ 2566838798 EndStrng_02 "ESMD_21932";
BA_ "CI_SLOT_Name" SG_ 2566838798 EndStrng_02 "SAEatad0200";
BA_ "GenSigStartValue" SG_ 2566838798 EndStrng_02 42;
BA_ "CI_FullName" SG_ 2566838798 EndStrng_03 "Software Identification";
BA_ "CI_ParId" SG_ 2566838798 EndStrng_03 "ESMD_21933";
BA_ "CI_SLOT_Name" SG_ 2566838798 EndStrng_03 "SAEatad0200";
BA_ "GenSigStartValue" SG_ 2566838798 EndStrng_03 42;
BA_ "GenSigAutoGenSnd" SG_ 2566838798 NumSW_IdField 0;
BA_ "GenSigAutoGenDsp" SG_ 2566838798 NumSW_IdField 0;
BA_ "CI_RepetitionComplemented" SG_ 2566838798 NumSW_IdField 2;
BA_ "CI_FullName" SG_ 2566838798 NumSW_IdField "Number of Software Identification Fields";
BA_ "CI_ParId" SG_ 2566838798 NumSW_IdField "ESMD_02746";
BA_ "CI_SLOT_Name" SG_ 2566838798 NumSW_IdField "SAEst01";
BA_ "SPN" SG_ 2566838798 NumSW_IdField 965;
BA_ "SigType" SG_ 2566838798 NumSW_IdField 1;
BA_ "CI_FullName" SG_ 2566838798 ProgDate "Software Identification";
BA_ "CI_ParId" SG_ 2566838798 ProgDate "ESMD_03139";
BA_ "CI_SLOT_Name" SG_ 2566838798 ProgDate "SAEatad0200";
BA_ "SPN" SG_ 2566838798 ProgDate 234;
BA_ "SigType" SG_ 2566838798 ProgDate 8;
BA_ "CI_FullName" SG_ 2566838798 ProgDate_Byte_01 "Software Identification";
BA_ "CI_ParId" SG_ 2566838798 ProgDate_Byte_01 "ESMD_03139";
BA_ "CI_SLOT_Name" SG_ 2566838798 ProgDate_Byte_01 "SAEatad0200";
BA_ "SPN" SG_ 2566838798 ProgDate_Byte_01 234;
BA_ "CI_FullName" SG_ 2566838798 ProgDate_Byte_02 "Software Identification";
BA_ "CI_ParId" SG_ 2566838798 ProgDate_Byte_02 "ESMD_03139";
BA_ "CI_SLOT_Name" SG_ 2566838798 ProgDate_Byte_02 "SAEatad0200";
BA_ "SPN" SG_ 2566838798 ProgDate_Byte_02 234;
BA_ "CI_FullName" SG_ 2566838798 ProgDate_Byte_03 "Software Identification";
BA_ "CI_ParId" SG_ 2566838798 ProgDate_Byte_03 "ESMD_03139";
BA_ "CI_SLOT_Name" SG_ 2566838798 ProgDate_Byte_03 "SAEatad0200";
BA_ "SPN" SG_ 2566838798 ProgDate_Byte_03 234;
BA_ "CI_FullName" SG_ 2566838798 ProgDate_Byte_04 "Software Identification";
BA_ "CI_ParId" SG_ 2566838798 ProgDate_Byte_04 "ESMD_03139";
BA_ "CI_SLOT_Name" SG_ 2566838798 ProgDate_Byte_04 "SAEatad0200";
BA_ "SPN" SG_ 2566838798 ProgDate_Byte_04 234;
BA_ "CI_FullName" SG_ 2566838798 ProgDate_Byte_05 "Software Identification";
BA_ "CI_ParId" SG_ 2566838798 ProgDate_Byte_05 "ESMD_03139";
BA_ "CI_SLOT_Name" SG_ 2566838798 ProgDate_Byte_05 "SAEatad0200";
BA_ "SPN" SG_ 2566838798 ProgDate_Byte_05 234;
BA_ "CI_FullName" SG_ 2566838798 ProgDate_Byte_06 "Software Identification";
BA_ "CI_ParId" SG_ 2566838798 ProgDate_Byte_06 "ESMD_03139";
BA_ "CI_SLOT_Name" SG_ 2566838798 ProgDate_Byte_06 "SAEatad0200";
BA_ "SPN" SG_ 2566838798 ProgDate_Byte_06 234;
BA_ "CI_FullName" SG_ 2566838798 ProgDate_Byte_07 "Software Identification";
BA_ "CI_ParId" SG_ 2566838798 ProgDate_Byte_07 "ESMD_03139";
BA_ "CI_SLOT_Name" SG_ 2566838798 ProgDate_Byte_07 "SAEatad0200";
BA_ "SPN" SG_ 2566838798 ProgDate_Byte_07 234;
BA_ "CI_FullName" SG_ 2566838798 SupplrSW_VerNum "Software Identification";
BA_ "CI_ParId" SG_ 2566838798 SupplrSW_VerNum "ESMD_03139";
BA_ "CI_SLOT_Name" SG_ 2566838798 SupplrSW_VerNum "SAEatad0200";
BA_ "SPN" SG_ 2566838798 SupplrSW_VerNum 234;
BA_ "SigType" SG_ 2566838798 SupplrSW_VerNum 3;
BA_ "CI_FullName" SG_ 2566838798 SupplrSW_VerNum_Byte_01 "Software Identification";
BA_ "CI_ParId" SG_ 2566838798 SupplrSW_VerNum_Byte_01 "ESMD_03139";
BA_ "CI_SLOT_Name" SG_ 2566838798 SupplrSW_VerNum_Byte_01 "SAEatad0200";
BA_ "SPN" SG_ 2566838798 SupplrSW_VerNum_Byte_01 234;
BA_ "SigType" SG_ 2566838798 SupplrSW_VerNum_Byte_01 3;
BA_ "CI_FullName" SG_ 2566838798 SupplrSW_VerNum_Byte_02 "Software Identification";
BA_ "CI_ParId" SG_ 2566838798 SupplrSW_VerNum_Byte_02 "ESMD_03139";
BA_ "CI_SLOT_Name" SG_ 2566838798 SupplrSW_VerNum_Byte_02 "SAEatad0200";
BA_ "SPN" SG_ 2566838798 SupplrSW_VerNum_Byte_02 234;
BA_ "SigType" SG_ 2566838798 SupplrSW_VerNum_Byte_02 3;
BA_ "CI_FullName" SG_ 2566838798 SupplrSW_VerNum_Byte_03 "Software Identification";
BA_ "CI_ParId" SG_ 2566838798 SupplrSW_VerNum_Byte_03 "ESMD_03139";
BA_ "CI_SLOT_Name" SG_ 2566838798 SupplrSW_VerNum_Byte_03 "SAEatad0200";
BA_ "SPN" SG_ 2566838798 SupplrSW_VerNum_Byte_03 234;
BA_ "SigType" SG_ 2566838798 SupplrSW_VerNum_Byte_03 3;
BA_ "CI_FullName" SG_ 2566838798 SupplrSW_VerNum_Byte_04 "Software Identification";
BA_ "CI_ParId" SG_ 2566838798 SupplrSW_VerNum_Byte_04 "ESMD_03139";
BA_ "CI_SLOT_Name" SG_ 2566838798 SupplrSW_VerNum_Byte_04 "SAEatad0200";
BA_ "SPN" SG_ 2566838798 SupplrSW_VerNum_Byte_04 234;
BA_ "SigType" SG_ 2566838798 SupplrSW_VerNum_Byte_04 3;
BA_ "CI_FullName" SG_ 2566838798 SupplrSW_VerNum_Byte_05 "Software Identification";
BA_ "CI_ParId" SG_ 2566838798 SupplrSW_VerNum_Byte_05 "ESMD_03139";
BA_ "CI_SLOT_Name" SG_ 2566838798 SupplrSW_VerNum_Byte_05 "SAEatad0200";
BA_ "SPN" SG_ 2566838798 SupplrSW_VerNum_Byte_05 234;
BA_ "SigType" SG_ 2566838798 SupplrSW_VerNum_Byte_05 3;
BA_ "CI_FullName" SG_ 2566838798 SupplrSW_VerNum_Byte_06 "Software Identification";
BA_ "CI_ParId" SG_ 2566838798 SupplrSW_VerNum_Byte_06 "ESMD_03139";
BA_ "CI_SLOT_Name" SG_ 2566838798 SupplrSW_VerNum_Byte_06 "SAEatad0200";
BA_ "SPN" SG_ 2566838798 SupplrSW_VerNum_Byte_06 234;
BA_ "SigType" SG_ 2566838798 SupplrSW_VerNum_Byte_06 3;
BA_ "CI_FullName" SG_ 2566838798 SupplrSW_VerNum_Byte_07 "Software Identification";
BA_ "CI_ParId" SG_ 2566838798 SupplrSW_VerNum_Byte_07 "ESMD_03139";
BA_ "CI_SLOT_Name" SG_ 2566838798 SupplrSW_VerNum_Byte_07 "SAEatad0200";
BA_ "SPN" SG_ 2566838798 SupplrSW_VerNum_Byte_07 234;
BA_ "SigType" SG_ 2566838798 SupplrSW_VerNum_Byte_07 3;
BA_ "CI_FullName" SG_ 2566838798 SupplrSW_VerNum_Byte_08 "Software Identification";
BA_ "CI_ParId" SG_ 2566838798 SupplrSW_VerNum_Byte_08 "ESMD_03139";
BA_ "CI_SLOT_Name" SG_ 2566838798 SupplrSW_VerNum_Byte_08 "SAEatad0200";
BA_ "SPN" SG_ 2566838798 SupplrSW_VerNum_Byte_08 234;
BA_ "SigType" SG_ 2566838798 SupplrSW_VerNum_Byte_08 3;
BA_ "CI_FullName" SG_ 2566838798 SupplrSW_VerNum_Byte_09 "Software Identification";
BA_ "CI_ParId" SG_ 2566838798 SupplrSW_VerNum_Byte_09 "ESMD_03139";
BA_ "CI_SLOT_Name" SG_ 2566838798 SupplrSW_VerNum_Byte_09 "SAEatad0200";
BA_ "SPN" SG_ 2566838798 SupplrSW_VerNum_Byte_09 234;
BA_ "SigType" SG_ 2566838798 SupplrSW_VerNum_Byte_09 3;
BA_ "CI_FullName" SG_ 2566838798 SupplrSW_VerNum_Byte_10 "Software Identification";
BA_ "CI_ParId" SG_ 2566838798 SupplrSW_VerNum_Byte_10 "ESMD_03139";
BA_ "CI_SLOT_Name" SG_ 2566838798 SupplrSW_VerNum_Byte_10 "SAEatad0200";
BA_ "SPN" SG_ 2566838798 SupplrSW_VerNum_Byte_10 234;
BA_ "SigType" SG_ 2566838798 SupplrSW_VerNum_Byte_10 3;
BA_ "CI_FullName" SG_ 2566838798 SupplrSW_VerNum_Byte_11 "Software Identification";
BA_ "CI_ParId" SG_ 2566838798 SupplrSW_VerNum_Byte_11 "ESMD_03139";
BA_ "CI_SLOT_Name" SG_ 2566838798 SupplrSW_VerNum_Byte_11 "SAEatad0200";
BA_ "SPN" SG_ 2566838798 SupplrSW_VerNum_Byte_11 234;
BA_ "SigType" SG_ 2566838798 SupplrSW_VerNum_Byte_11 3;
BA_ "CI_FullName" SG_ 2566838798 SupplrSW_VerNum_Byte_12 "Software Identification";
BA_ "CI_ParId" SG_ 2566838798 SupplrSW_VerNum_Byte_12 "ESMD_03139";
BA_ "CI_SLOT_Name" SG_ 2566838798 SupplrSW_VerNum_Byte_12 "SAEatad0200";
BA_ "SPN" SG_ 2566838798 SupplrSW_VerNum_Byte_12 234;
BA_ "SigType" SG_ 2566838798 SupplrSW_VerNum_Byte_12 3;
BA_ "CI_FullName" SG_ 2566835470 EngIntakManifld_1Prs "Engine Intake Manifold #1 Pressure";
BA_ "CI_ParId" SG_ 2566835470 EngIntakManifld_1Prs "ESMD_01641";
BA_ "CI_SLOT_Name" SG_ 2566835470 EngIntakManifld_1Prs "SAEpr07";
BA_ "SPN" SG_ 2566835470 EngIntakManifld_1Prs 102;
BA_ "SigType" SG_ 2566835470 EngIntakManifld_1Prs 1;
BA_ "GenSigAutoGenSnd" SG_ 2566835470 EngSpd 0;
BA_ "GenSigAutoGenDsp" SG_ 2566835470 EngSpd 0;
BA_ "CI_RepetitionComplemented" SG_ 2566835470 EngSpd 2;
BA_ "CI_FullName" SG_ 2566835470 EngSpd "Engine Speed";
BA_ "CI_ParId" SG_ 2566835470 EngSpd "ESMD_01792";
BA_ "CI_SLOT_Name" SG_ 2566835470 EngSpd "SAEvr01";
BA_ "SPN" SG_ 2566835470 EngSpd 190;
BA_ "GenSigAutoGenSnd" SG_ 2566835470 EngTorqMode 0;
BA_ "GenSigAutoGenDsp" SG_ 2566835470 EngTorqMode 0;
BA_ "CI_RepetitionComplemented" SG_ 2566835470 EngTorqMode 2;
BA_ "CI_FullName" SG_ 2566835470 EngTorqMode "Engine Torque Mode";
BA_ "CI_ParId" SG_ 2566835470 EngTorqMode "ESMD_01836";
BA_ "CI_SLOT_Name" SG_ 2566835470 EngTorqMode "SAEbs04";
BA_ "SPN" SG_ 2566835470 EngTorqMode 899;
BA_ "GenSigAutoGenSnd" SG_ 2566835470 EngTotHourOp 0;
BA_ "GenSigAutoGenDsp" SG_ 2566835470 EngTotHourOp 0;
BA_ "CI_RepetitionComplemented" SG_ 2566835470 EngTotHourOp 2;
BA_ "CI_FullName" SG_ 2566835470 EngTotHourOp "Engine Total Hours of Operation";
BA_ "CI_ParId" SG_ 2566835470 EngTotHourOp "ESMD_01840";
BA_ "CI_SLOT_Name" SG_ 2566835470 EngTotHourOp "SAEtm09";
BA_ "SPN" SG_ 2566835470 EngTotHourOp 247;
BA_ "CI_FullName" SG_ 2566835470 FailModeId "Failure Mode Identifier";
BA_ "CI_ParId" SG_ 2566835470 FailModeId "ESMD_01931";
BA_ "CI_SLOT_Name" SG_ 2566835470 FailModeId "SAEfm00";
BA_ "SPN" SG_ 2566835470 FailModeId 1215;
BA_ "CI_FullName" SG_ 2566835470 FreezeFrameLen "Freeze Frame Length";
BA_ "CI_ParId" SG_ 2566835470 FreezeFrameLen "ESMD_01974";
BA_ "CI_SLOT_Name" SG_ 2566835470 FreezeFrameLen "SAEct03";
BA_ "SPN" SG_ 2566835470 FreezeFrameLen 1217;
BA_ "CI_FullName" SG_ 2566835470 HiResolTotVehDist "High Resolution Total Vehicle Distance";
BA_ "CI_ParId" SG_ 2566835470 HiResolTotVehDist "ESMD_02076";
BA_ "CI_SLOT_Name" SG_ 2566835470 HiResolTotVehDist "SAEds09";
BA_ "SPN" SG_ 2566835470 HiResolTotVehDist 917;
BA_ "GenSigAutoGenSnd" SG_ 2566835470 Hour 0;
BA_ "GenSigAutoGenDsp" SG_ 2566835470 Hour 0;
BA_ "CI_RepetitionComplemented" SG_ 2566835470 Hour 2;
BA_ "CI_FullName" SG_ 2566835470 Hour "Hours";
BA_ "CI_ParId" SG_ 2566835470 Hour "ESMD_02087";
BA_ "CI_SLOT_Name" SG_ 2566835470 Hour "SAEtm11";
BA_ "SPN" SG_ 2566835470 Hour 961;
BA_ "GenSigAutoGenSnd" SG_ 2566835470 Minut 0;
BA_ "GenSigAutoGenDsp" SG_ 2566835470 Minut 0;
BA_ "CI_RepetitionComplemented" SG_ 2566835470 Minut 2;
BA_ "CI_FullName" SG_ 2566835470 Minut "Minutes";
BA_ "CI_ParId" SG_ 2566835470 Minut "ESMD_02704";
BA_ "CI_SLOT_Name" SG_ 2566835470 Minut "SAEtm08";
BA_ "SPN" SG_ 2566835470 Minut 960;
BA_ "GenSigAutoGenSnd" SG_ 2566835470 Month 0;
BA_ "GenSigAutoGenDsp" SG_ 2566835470 Month 0;
BA_ "CI_RepetitionComplemented" SG_ 2566835470 Month 2;
BA_ "CI_FullName" SG_ 2566835470 Month "Month";
BA_ "CI_ParId" SG_ 2566835470 Month "ESMD_02719";
BA_ "CI_SLOT_Name" SG_ 2566835470 Month "SAEcm01";
BA_ "SPN" SG_ 2566835470 Month 963;
BA_ "CI_FullName" SG_ 2566835470 OC "Occurrence Count";
BA_ "CI_ParId" SG_ 2566835470 OC "ESMD_15183";
BA_ "CI_SLOT_Name" SG_ 2566835470 OC "SAEOC00";
BA_ "SPN" SG_ 2566835470 OC 1216;
BA_ "GenSigAutoGenSnd" SG_ 2566835470 Sec 0;
BA_ "GenSigAutoGenDsp" SG_ 2566835470 Sec 0;
BA_ "CI_RepetitionComplemented" SG_ 2566835470 Sec 2;
BA_ "CI_FullName" SG_ 2566835470 Sec "Seconds";
BA_ "CI_ParId" SG_ 2566835470 Sec "ESMD_03098";
BA_ "CI_SLOT_Name" SG_ 2566835470 Sec "SAEtm04";
BA_ "SPN" SG_ 2566835470 Sec 959;
BA_ "CI_FullName" SG_ 2566835470 SPN "Suspect Parameter Number";
BA_ "CI_ParId" SG_ 2566835470 SPN "ESMD_03237";
BA_ "CI_SLOT_Name" SG_ 2566835470 SPN "SAESP00";
BA_ "SPN" SG_ 2566835470 SPN 1214;
BA_ "CI_FullName" SG_ 2566835470 SPN1High "_";
BA_ "CI_ParId" SG_ 2566835470 SPN1High "ESMD_03238";
BA_ "CI_FullName" SG_ 2566835470 SPN_CM "SPN Conversion Method";
BA_ "CI_ParId" SG_ 2566835470 SPN_CM "ESMD_15184";
BA_ "CI_SLOT_Name" SG_ 2566835470 SPN_CM "SAEbs01";
BA_ "SPN" SG_ 2566835470 SPN_CM 1706;
BA_ "GenSigAutoGenSnd" SG_ 2566835470 WhBsdVehSpd 0;
BA_ "GenSigAutoGenDsp" SG_ 2566835470 WhBsdVehSpd 0;
BA_ "CI_RepetitionNum" SG_ 2566835470 WhBsdVehSpd 1;
BA_ "CI_RepetitionType" SG_ 2566835470 WhBsdVehSpd 3;
BA_ "CI_RepetitionComplemented" SG_ 2566835470 WhBsdVehSpd 2;
BA_ "CI_FullName" SG_ 2566835470 WhBsdVehSpd "Wheel-Based Vehicle Speed";
BA_ "CI_ParId" SG_ 2566835470 WhBsdVehSpd "ESMD_03807";
BA_ "CI_SLOT_Name" SG_ 2566835470 WhBsdVehSpd "SAEvl02";
BA_ "SPN" SG_ 2566835470 WhBsdVehSpd 84;
BA_ "GenSigAutoGenSnd" SG_ 2566835470 Year 0;
BA_ "GenSigAutoGenDsp" SG_ 2566835470 Year 0;
BA_ "CI_RepetitionComplemented" SG_ 2566835470 Year 2;
BA_ "CI_FullName" SG_ 2566835470 Year "Year";
BA_ "CI_ParId" SG_ 2566835470 Year "ESMD_03830";
BA_ "CI_SLOT_Name" SG_ 2566835470 Year "SAEcy01";
BA_ "SPN" SG_ 2566835470 Year 964;
BA_ "CI_FullName" SG_ 2566835470 AmbrLmpDefSts "Amber Lamp Definition Status";
BA_ "CI_ParId" SG_ 2566835470 AmbrLmpDefSts "ESMD_21636";
BA_ "CI_SLOT_Name" SG_ 2566835470 AmbrLmpDefSts "SAEbs02";
BA_ "SPN" SG_ 2566835470 AmbrLmpDefSts 519814;
BA_ "CI_FullName" SG_ 2566835470 EngCoolntTemp "Engine Coolant Temperature";
BA_ "CI_ParId" SG_ 2566835470 EngCoolntTemp "ESMD_01292";
BA_ "CI_SLOT_Name" SG_ 2566835470 EngCoolntTemp "SAEtp01";
BA_ "SPN" SG_ 2566835470 EngCoolntTemp 110;
BA_ "CI_FullName" SG_ 2566835470 RedLmpDefSts "Red Lamp Definition Status";
BA_ "CI_ParId" SG_ 2566835470 RedLmpDefSts "ESMD_26983";
BA_ "CI_SLOT_Name" SG_ 2566835470 RedLmpDefSts "SAEbs02";
BA_ "SPN" SG_ 2566835470 RedLmpDefSts 519815;
BA_ "CI_FullName" SG_ 2566835470 AddrAssignNewSA "Address Assignment (new source address)";
BA_ "CI_ParId" SG_ 2566835470 AddrAssignNewSA "ESMD_00042";
BA_ "SPN" SG_ 2566835470 AddrAssignNewSA 2847;
BA_ "CI_FullName" SG_ 2566835470 BattPotentPwrInput_1 "Battery Potential / Power Input 1";
BA_ "CI_ParId" SG_ 2566835470 BattPotentPwrInput_1 "ESMD_00778";
BA_ "CI_SLOT_Name" SG_ 2566835470 BattPotentPwrInput_1 "SAEev01";
BA_ "GenSigStartValue" SG_ 2566835470 BattPotentPwrInput_1 65535;
BA_ "SPN" SG_ 2566835470 BattPotentPwrInput_1 168;
BA_ "SigType" SG_ 2566835470 BattPotentPwrInput_1 1;
BA_ "GenSigAutoGenSnd" SG_ 2566835470 Day 0;
BA_ "GenSigAutoGenDsp" SG_ 2566835470 Day 0;
BA_ "CI_RepetitionComplemented" SG_ 2566835470 Day 2;
BA_ "CI_FullName" SG_ 2566835470 Day "Day";
BA_ "CI_ParId" SG_ 2566835470 Day "ESMD_01022";
BA_ "CI_SLOT_Name" SG_ 2566835470 Day "SAEcd01";
BA_ "SPN" SG_ 2566835470 Day 962;
BA_ "CI_FullName" SG_ 2566835470 Eng_pcLoadCurrSpd "Engine Percent Load At Current Speed";
BA_ "CI_ParId" SG_ 2566835470 Eng_pcLoadCurrSpd "ESMD_01725";
BA_ "CI_SLOT_Name" SG_ 2566835470 Eng_pcLoadCurrSpd "SAEpc06";
BA_ "SPN" SG_ 2566835470 Eng_pcLoadCurrSpd 92;
BA_ "SigType" SG_ 2566835470 Eng_pcLoadCurrSpd 1;
BA_ "CI_FullName" SG_ 2566843150 Make "Make";
BA_ "CI_ParId" SG_ 2566843150 Make "ESMD_02671";
BA_ "CI_SLOT_Name" SG_ 2566843150 Make "SAEatad0005";
BA_ "SPN" SG_ 2566843150 Make 586;
BA_ "CI_FullName" SG_ 2566843150 Mdl "Model";
BA_ "CI_ParId" SG_ 2566843150 Mdl "ESMD_02715";
BA_ "CI_SLOT_Name" SG_ 2566843150 Mdl "SAEatad0200";
BA_ "SPN" SG_ 2566843150 Mdl 587;
BA_ "CI_FullName" SG_ 2566843150 SN_2 "Serial Number 2";
BA_ "CI_ParId" SG_ 2566843150 SN_2 "ESMD_03115";
BA_ "CI_SLOT_Name" SG_ 2566843150 SN_2 "SAEatad0200";
BA_ "SPN" SG_ 2566843150 SN_2 588;
BA_ "CI_FullName" SG_ 2566843150 UnitNumPwrUnit "Unit Number (Power Unit)";
BA_ "CI_ParId" SG_ 2566843150 UnitNumPwrUnit "ESMD_03702";
BA_ "CI_SLOT_Name" SG_ 2566843150 UnitNumPwrUnit "SAEatad0200";
BA_ "SPN" SG_ 2566843150 UnitNumPwrUnit 233;
BA_ "CI_FullName" SG_ 2566767886 EndStrng_04 "Software Identification";
BA_ "CI_ParId" SG_ 2566767886 EndStrng_04 "ESMD_21933";
BA_ "CI_SLOT_Name" SG_ 2566767886 EndStrng_04 "SAEatad0200";
BA_ "GenSigStartValue" SG_ 2566767886 EndStrng_04 42;
BA_ "CI_FullName" SG_ 2566767886 EndStrng_03 "Software Identification";
BA_ "CI_ParId" SG_ 2566767886 EndStrng_03 "ESMD_21933";
BA_ "CI_SLOT_Name" SG_ 2566767886 EndStrng_03 "SAEatad0200";
BA_ "GenSigStartValue" SG_ 2566767886 EndStrng_03 42;
BA_ "CI_FullName" SG_ 2566767886 EndStrng_02 "Software Identification";
BA_ "CI_ParId" SG_ 2566767886 EndStrng_02 "ESMD_21932";
BA_ "CI_SLOT_Name" SG_ 2566767886 EndStrng_02 "SAEatad0200";
BA_ "GenSigStartValue" SG_ 2566767886 EndStrng_02 42;
BA_ "CI_FullName" SG_ 2566767886 EndStrng_01 "Software Identification";
BA_ "CI_ParId" SG_ 2566767886 EndStrng_01 "ESMD_21931";
BA_ "CI_SLOT_Name" SG_ 2566767886 EndStrng_01 "SAEatad0200";
BA_ "GenSigStartValue" SG_ 2566767886 EndStrng_01 42;
BA_ "SigType" SG_ 2566767886 EndStrng_01 8;
BA_ "CI_FullName" SG_ 2566767886 EndStrng_00 "Software Identification";
BA_ "CI_ParId" SG_ 2566767886 EndStrng_00 "ESMD_21930";
BA_ "CI_SLOT_Name" SG_ 2566767886 EndStrng_00 "SAEatad0200";
BA_ "GenSigStartValue" SG_ 2566767886 EndStrng_00 42;
BA_ "SigType" SG_ 2566767886 EndStrng_00 8;
BA_ "CI_FullName" SG_ 2566767886 ECU_SN_Byte_09 "ECU Serial Number";
BA_ "CI_ParId" SG_ 2566767886 ECU_SN_Byte_09 "ESMD_01167";
BA_ "CI_SLOT_Name" SG_ 2566767886 ECU_SN_Byte_09 "SAEatad0200";
BA_ "SPN" SG_ 2566767886 ECU_SN_Byte_09 2902;
BA_ "CI_FullName" SG_ 2566767886 ECU_SN_Byte_08 "ECU Serial Number";
BA_ "CI_ParId" SG_ 2566767886 ECU_SN_Byte_08 "ESMD_01167";
BA_ "CI_SLOT_Name" SG_ 2566767886 ECU_SN_Byte_08 "SAEatad0200";
BA_ "SPN" SG_ 2566767886 ECU_SN_Byte_08 2902;
BA_ "CI_FullName" SG_ 2566767886 ECU_SN_Byte_07 "ECU Serial Number";
BA_ "CI_ParId" SG_ 2566767886 ECU_SN_Byte_07 "ESMD_01167";
BA_ "CI_SLOT_Name" SG_ 2566767886 ECU_SN_Byte_07 "SAEatad0200";
BA_ "SPN" SG_ 2566767886 ECU_SN_Byte_07 2902;
BA_ "CI_FullName" SG_ 2566767886 ECU_SN_Byte_06 "ECU Serial Number";
BA_ "CI_ParId" SG_ 2566767886 ECU_SN_Byte_06 "ESMD_01167";
BA_ "CI_SLOT_Name" SG_ 2566767886 ECU_SN_Byte_06 "SAEatad0200";
BA_ "SPN" SG_ 2566767886 ECU_SN_Byte_06 2902;
BA_ "CI_FullName" SG_ 2566767886 ECU_SN_Byte_05 "ECU Serial Number";
BA_ "CI_ParId" SG_ 2566767886 ECU_SN_Byte_05 "ESMD_01167";
BA_ "CI_SLOT_Name" SG_ 2566767886 ECU_SN_Byte_05 "SAEatad0200";
BA_ "SPN" SG_ 2566767886 ECU_SN_Byte_05 2902;
BA_ "CI_FullName" SG_ 2566767886 ECU_SN_Byte_04 "ECU Serial Number";
BA_ "CI_ParId" SG_ 2566767886 ECU_SN_Byte_04 "ESMD_01167";
BA_ "CI_SLOT_Name" SG_ 2566767886 ECU_SN_Byte_04 "SAEatad0200";
BA_ "SPN" SG_ 2566767886 ECU_SN_Byte_04 2902;
BA_ "CI_FullName" SG_ 2566767886 ECU_SN_Byte_03 "ECU Serial Number";
BA_ "CI_ParId" SG_ 2566767886 ECU_SN_Byte_03 "ESMD_01167";
BA_ "CI_SLOT_Name" SG_ 2566767886 ECU_SN_Byte_03 "SAEatad0200";
BA_ "SPN" SG_ 2566767886 ECU_SN_Byte_03 2902;
BA_ "CI_FullName" SG_ 2566767886 ECU_SN_Byte_02 "ECU Serial Number";
BA_ "CI_ParId" SG_ 2566767886 ECU_SN_Byte_02 "ESMD_01167";
BA_ "CI_SLOT_Name" SG_ 2566767886 ECU_SN_Byte_02 "SAEatad0200";
BA_ "SPN" SG_ 2566767886 ECU_SN_Byte_02 2902;
BA_ "CI_FullName" SG_ 2566767886 ECU_SN_Byte_01 "ECU Serial Number";
BA_ "CI_ParId" SG_ 2566767886 ECU_SN_Byte_01 "ESMD_01167";
BA_ "CI_SLOT_Name" SG_ 2566767886 ECU_SN_Byte_01 "SAEatad0200";
BA_ "SPN" SG_ 2566767886 ECU_SN_Byte_01 2902;
BA_ "CI_FullName" SG_ 2566767886 ECU_PN_Byte_14 "ECU Part Number";
BA_ "CI_ParId" SG_ 2566767886 ECU_PN_Byte_14 "ESMD_01163";
BA_ "CI_SLOT_Name" SG_ 2566767886 ECU_PN_Byte_14 "SAEatad0200";
BA_ "SPN" SG_ 2566767886 ECU_PN_Byte_14 2901;
BA_ "CI_FullName" SG_ 2566767886 ECU_PN_Byte_13 "ECU Part Number";
BA_ "CI_ParId" SG_ 2566767886 ECU_PN_Byte_13 "ESMD_01163";
BA_ "CI_SLOT_Name" SG_ 2566767886 ECU_PN_Byte_13 "SAEatad0200";
BA_ "SPN" SG_ 2566767886 ECU_PN_Byte_13 2901;
BA_ "CI_FullName" SG_ 2566767886 ECU_PN_Byte_12 "ECU Part Number";
BA_ "CI_ParId" SG_ 2566767886 ECU_PN_Byte_12 "ESMD_01163";
BA_ "CI_SLOT_Name" SG_ 2566767886 ECU_PN_Byte_12 "SAEatad0200";
BA_ "SPN" SG_ 2566767886 ECU_PN_Byte_12 2901;
BA_ "CI_FullName" SG_ 2566767886 ECU_PN_Byte_11 "ECU Part Number";
BA_ "CI_ParId" SG_ 2566767886 ECU_PN_Byte_11 "ESMD_01163";
BA_ "CI_SLOT_Name" SG_ 2566767886 ECU_PN_Byte_11 "SAEatad0200";
BA_ "SPN" SG_ 2566767886 ECU_PN_Byte_11 2901;
BA_ "CI_FullName" SG_ 2566767886 ECU_PN_Byte_10 "ECU Part Number";
BA_ "CI_ParId" SG_ 2566767886 ECU_PN_Byte_10 "ESMD_01163";
BA_ "CI_SLOT_Name" SG_ 2566767886 ECU_PN_Byte_10 "SAEatad0200";
BA_ "SPN" SG_ 2566767886 ECU_PN_Byte_10 2901;
BA_ "CI_FullName" SG_ 2566767886 ECU_PN_Byte_09 "ECU Part Number";
BA_ "CI_ParId" SG_ 2566767886 ECU_PN_Byte_09 "ESMD_01163";
BA_ "CI_SLOT_Name" SG_ 2566767886 ECU_PN_Byte_09 "SAEatad0200";
BA_ "SPN" SG_ 2566767886 ECU_PN_Byte_09 2901;
BA_ "CI_FullName" SG_ 2566767886 ECU_PN_Byte_08 "ECU Part Number";
BA_ "CI_ParId" SG_ 2566767886 ECU_PN_Byte_08 "ESMD_01163";
BA_ "CI_SLOT_Name" SG_ 2566767886 ECU_PN_Byte_08 "SAEatad0200";
BA_ "SPN" SG_ 2566767886 ECU_PN_Byte_08 2901;
BA_ "CI_FullName" SG_ 2566767886 ECU_PN_Byte_07 "ECU Part Number";
BA_ "CI_ParId" SG_ 2566767886 ECU_PN_Byte_07 "ESMD_01163";
BA_ "CI_SLOT_Name" SG_ 2566767886 ECU_PN_Byte_07 "SAEatad0200";
BA_ "SPN" SG_ 2566767886 ECU_PN_Byte_07 2901;
BA_ "CI_FullName" SG_ 2566767886 ECU_PN_Byte_06 "ECU Part Number";
BA_ "CI_ParId" SG_ 2566767886 ECU_PN_Byte_06 "ESMD_01163";
BA_ "CI_SLOT_Name" SG_ 2566767886 ECU_PN_Byte_06 "SAEatad0200";
BA_ "SPN" SG_ 2566767886 ECU_PN_Byte_06 2901;
BA_ "CI_FullName" SG_ 2566767886 ECU_PN_Byte_05 "ECU Part Number";
BA_ "CI_ParId" SG_ 2566767886 ECU_PN_Byte_05 "ESMD_01163";
BA_ "CI_SLOT_Name" SG_ 2566767886 ECU_PN_Byte_05 "SAEatad0200";
BA_ "SPN" SG_ 2566767886 ECU_PN_Byte_05 2901;
BA_ "CI_FullName" SG_ 2566767886 ECU_PN_Byte_04 "ECU Part Number";
BA_ "CI_ParId" SG_ 2566767886 ECU_PN_Byte_04 "ESMD_01163";
BA_ "CI_SLOT_Name" SG_ 2566767886 ECU_PN_Byte_04 "SAEatad0200";
BA_ "SPN" SG_ 2566767886 ECU_PN_Byte_04 2901;
BA_ "CI_FullName" SG_ 2566767886 ECU_PN_Byte_03 "ECU Part Number";
BA_ "CI_ParId" SG_ 2566767886 ECU_PN_Byte_03 "ESMD_01163";
BA_ "CI_SLOT_Name" SG_ 2566767886 ECU_PN_Byte_03 "SAEatad0200";
BA_ "SPN" SG_ 2566767886 ECU_PN_Byte_03 2901;
BA_ "CI_FullName" SG_ 2566767886 ECU_PN_Byte_02 "ECU Part Number";
BA_ "CI_ParId" SG_ 2566767886 ECU_PN_Byte_02 "ESMD_01163";
BA_ "CI_SLOT_Name" SG_ 2566767886 ECU_PN_Byte_02 "SAEatad0200";
BA_ "SPN" SG_ 2566767886 ECU_PN_Byte_02 2901;
BA_ "CI_FullName" SG_ 2566767886 ECU_PN_Byte_01 "ECU Part Number";
BA_ "CI_ParId" SG_ 2566767886 ECU_PN_Byte_01 "ESMD_01163";
BA_ "CI_SLOT_Name" SG_ 2566767886 ECU_PN_Byte_01 "SAEatad0200";
BA_ "SPN" SG_ 2566767886 ECU_PN_Byte_01 2901;
BA_ "CI_FullName" SG_ 2566767886 ECU_ManufctName_Byte_14 "ECU Manufacturer Name";
BA_ "CI_ParId" SG_ 2566767886 ECU_ManufctName_Byte_14 "ESMD_08390";
BA_ "CI_SLOT_Name" SG_ 2566767886 ECU_ManufctName_Byte_14 "SAEatad0200";
BA_ "SPN" SG_ 2566767886 ECU_ManufctName_Byte_14 4304;
BA_ "CI_FullName" SG_ 2566767886 ECU_ManufctName_Byte_13 "ECU Manufacturer Name";
BA_ "CI_ParId" SG_ 2566767886 ECU_ManufctName_Byte_13 "ESMD_08390";
BA_ "CI_SLOT_Name" SG_ 2566767886 ECU_ManufctName_Byte_13 "SAEatad0200";
BA_ "SPN" SG_ 2566767886 ECU_ManufctName_Byte_13 4304;
BA_ "CI_FullName" SG_ 2566767886 ECU_ManufctName_Byte_12 "ECU Manufacturer Name";
BA_ "CI_ParId" SG_ 2566767886 ECU_ManufctName_Byte_12 "ESMD_08390";
BA_ "CI_SLOT_Name" SG_ 2566767886 ECU_ManufctName_Byte_12 "SAEatad0200";
BA_ "SPN" SG_ 2566767886 ECU_ManufctName_Byte_12 4304;
BA_ "CI_FullName" SG_ 2566767886 ECU_ManufctName_Byte_11 "ECU Manufacturer Name";
BA_ "CI_ParId" SG_ 2566767886 ECU_ManufctName_Byte_11 "ESMD_08390";
BA_ "CI_SLOT_Name" SG_ 2566767886 ECU_ManufctName_Byte_11 "SAEatad0200";
BA_ "SPN" SG_ 2566767886 ECU_ManufctName_Byte_11 4304;
BA_ "CI_FullName" SG_ 2566767886 ECU_ManufctName_Byte_10 "ECU Manufacturer Name";
BA_ "CI_ParId" SG_ 2566767886 ECU_ManufctName_Byte_10 "ESMD_08390";
BA_ "CI_SLOT_Name" SG_ 2566767886 ECU_ManufctName_Byte_10 "SAEatad0200";
BA_ "SPN" SG_ 2566767886 ECU_ManufctName_Byte_10 4304;
BA_ "CI_FullName" SG_ 2566767886 ECU_ManufctName_Byte_09 "ECU Manufacturer Name";
BA_ "CI_ParId" SG_ 2566767886 ECU_ManufctName_Byte_09 "ESMD_08390";
BA_ "CI_SLOT_Name" SG_ 2566767886 ECU_ManufctName_Byte_09 "SAEatad0200";
BA_ "SPN" SG_ 2566767886 ECU_ManufctName_Byte_09 4304;
BA_ "CI_FullName" SG_ 2566767886 ECU_ManufctName_Byte_08 "ECU Manufacturer Name";
BA_ "CI_ParId" SG_ 2566767886 ECU_ManufctName_Byte_08 "ESMD_08390";
BA_ "CI_SLOT_Name" SG_ 2566767886 ECU_ManufctName_Byte_08 "SAEatad0200";
BA_ "SPN" SG_ 2566767886 ECU_ManufctName_Byte_08 4304;
BA_ "CI_FullName" SG_ 2566767886 ECU_ManufctName_Byte_07 "ECU Manufacturer Name";
BA_ "CI_ParId" SG_ 2566767886 ECU_ManufctName_Byte_07 "ESMD_08390";
BA_ "CI_SLOT_Name" SG_ 2566767886 ECU_ManufctName_Byte_07 "SAEatad0200";
BA_ "SPN" SG_ 2566767886 ECU_ManufctName_Byte_07 4304;
BA_ "CI_FullName" SG_ 2566767886 ECU_ManufctName_Byte_06 "ECU Manufacturer Name";
BA_ "CI_ParId" SG_ 2566767886 ECU_ManufctName_Byte_06 "ESMD_08390";
BA_ "CI_SLOT_Name" SG_ 2566767886 ECU_ManufctName_Byte_06 "SAEatad0200";
BA_ "SPN" SG_ 2566767886 ECU_ManufctName_Byte_06 4304;
BA_ "CI_FullName" SG_ 2566767886 ECU_ManufctName_Byte_05 "ECU Manufacturer Name";
BA_ "CI_ParId" SG_ 2566767886 ECU_ManufctName_Byte_05 "ESMD_08390";
BA_ "CI_SLOT_Name" SG_ 2566767886 ECU_ManufctName_Byte_05 "SAEatad0200";
BA_ "SPN" SG_ 2566767886 ECU_ManufctName_Byte_05 4304;
BA_ "CI_FullName" SG_ 2566767886 ECU_ManufctName_Byte_04 "ECU Manufacturer Name";
BA_ "CI_ParId" SG_ 2566767886 ECU_ManufctName_Byte_04 "ESMD_08390";
BA_ "CI_SLOT_Name" SG_ 2566767886 ECU_ManufctName_Byte_04 "SAEatad0200";
BA_ "SPN" SG_ 2566767886 ECU_ManufctName_Byte_04 4304;
BA_ "CI_FullName" SG_ 2566767886 ECU_ManufctName_Byte_03 "ECU Manufacturer Name";
BA_ "CI_ParId" SG_ 2566767886 ECU_ManufctName_Byte_03 "ESMD_08390";
BA_ "CI_SLOT_Name" SG_ 2566767886 ECU_ManufctName_Byte_03 "SAEatad0200";
BA_ "SPN" SG_ 2566767886 ECU_ManufctName_Byte_03 4304;
BA_ "CI_FullName" SG_ 2566767886 ECU_ManufctName_Byte_02 "ECU Manufacturer Name";
BA_ "CI_ParId" SG_ 2566767886 ECU_ManufctName_Byte_02 "ESMD_08390";
BA_ "CI_SLOT_Name" SG_ 2566767886 ECU_ManufctName_Byte_02 "SAEatad0200";
BA_ "SPN" SG_ 2566767886 ECU_ManufctName_Byte_02 4304;
BA_ "CI_FullName" SG_ 2566767886 ECU_ManufctName_Byte_01 "ECU Manufacturer Name";
BA_ "CI_ParId" SG_ 2566767886 ECU_ManufctName_Byte_01 "ESMD_08390";
BA_ "CI_SLOT_Name" SG_ 2566767886 ECU_ManufctName_Byte_01 "SAEatad0200";
BA_ "SPN" SG_ 2566767886 ECU_ManufctName_Byte_01 4304;
BA_ "CI_FullName" SG_ 2566767886 ECU_Locat_Byte_09 "ECU Location";
BA_ "CI_ParId" SG_ 2566767886 ECU_Locat_Byte_09 "ESMD_01162";
BA_ "CI_SLOT_Name" SG_ 2566767886 ECU_Locat_Byte_09 "SAEatad0200";
BA_ "SPN" SG_ 2566767886 ECU_Locat_Byte_09 2903;
BA_ "CI_FullName" SG_ 2566767886 ECU_Locat_Byte_08 "ECU Location";
BA_ "CI_ParId" SG_ 2566767886 ECU_Locat_Byte_08 "ESMD_01162";
BA_ "CI_SLOT_Name" SG_ 2566767886 ECU_Locat_Byte_08 "SAEatad0200";
BA_ "SPN" SG_ 2566767886 ECU_Locat_Byte_08 2903;
BA_ "CI_FullName" SG_ 2566767886 ECU_Locat_Byte_07 "ECU Location";
BA_ "CI_ParId" SG_ 2566767886 ECU_Locat_Byte_07 "ESMD_01162";
BA_ "CI_SLOT_Name" SG_ 2566767886 ECU_Locat_Byte_07 "SAEatad0200";
BA_ "SPN" SG_ 2566767886 ECU_Locat_Byte_07 2903;
BA_ "CI_FullName" SG_ 2566767886 ECU_Locat_Byte_06 "ECU Location";
BA_ "CI_ParId" SG_ 2566767886 ECU_Locat_Byte_06 "ESMD_01162";
BA_ "CI_SLOT_Name" SG_ 2566767886 ECU_Locat_Byte_06 "SAEatad0200";
BA_ "SPN" SG_ 2566767886 ECU_Locat_Byte_06 2903;
BA_ "CI_FullName" SG_ 2566767886 ECU_Locat_Byte_05 "ECU Location";
BA_ "CI_ParId" SG_ 2566767886 ECU_Locat_Byte_05 "ESMD_01162";
BA_ "CI_SLOT_Name" SG_ 2566767886 ECU_Locat_Byte_05 "SAEatad0200";
BA_ "SPN" SG_ 2566767886 ECU_Locat_Byte_05 2903;
BA_ "CI_FullName" SG_ 2566767886 ECU_Locat_Byte_04 "ECU Location";
BA_ "CI_ParId" SG_ 2566767886 ECU_Locat_Byte_04 "ESMD_01162";
BA_ "CI_SLOT_Name" SG_ 2566767886 ECU_Locat_Byte_04 "SAEatad0200";
BA_ "SPN" SG_ 2566767886 ECU_Locat_Byte_04 2903;
BA_ "CI_FullName" SG_ 2566767886 ECU_Locat_Byte_03 "ECU Location";
BA_ "CI_ParId" SG_ 2566767886 ECU_Locat_Byte_03 "ESMD_01162";
BA_ "CI_SLOT_Name" SG_ 2566767886 ECU_Locat_Byte_03 "SAEatad0200";
BA_ "SPN" SG_ 2566767886 ECU_Locat_Byte_03 2903;
BA_ "CI_FullName" SG_ 2566767886 ECU_Locat_Byte_02 "ECU Location";
BA_ "CI_ParId" SG_ 2566767886 ECU_Locat_Byte_02 "ESMD_01162";
BA_ "CI_SLOT_Name" SG_ 2566767886 ECU_Locat_Byte_02 "SAEatad0200";
BA_ "SPN" SG_ 2566767886 ECU_Locat_Byte_02 2903;
BA_ "CI_FullName" SG_ 2566767886 ECU_Locat_Byte_01 "ECU Location";
BA_ "CI_ParId" SG_ 2566767886 ECU_Locat_Byte_01 "ESMD_01162";
BA_ "CI_SLOT_Name" SG_ 2566767886 ECU_Locat_Byte_01 "SAEatad0200";
BA_ "SPN" SG_ 2566767886 ECU_Locat_Byte_01 2903;
BA_ "CI_FullName" SG_ 2566767886 ECU_HW_Id_Byte_14 "_";
BA_ "CI_ParId" SG_ 2566767886 ECU_HW_Id_Byte_14 "ESMD_08386";
BA_ "SPN" SG_ 2566767886 ECU_HW_Id_Byte_14 6714;
BA_ "CI_FullName" SG_ 2566767886 ECU_HW_Id_Byte_13 "_";
BA_ "CI_ParId" SG_ 2566767886 ECU_HW_Id_Byte_13 "ESMD_08386";
BA_ "SPN" SG_ 2566767886 ECU_HW_Id_Byte_13 6714;
BA_ "CI_FullName" SG_ 2566767886 ECU_HW_Id_Byte_12 "_";
BA_ "CI_ParId" SG_ 2566767886 ECU_HW_Id_Byte_12 "ESMD_08386";
BA_ "SPN" SG_ 2566767886 ECU_HW_Id_Byte_12 6714;
BA_ "CI_FullName" SG_ 2566767886 ECU_HW_Id_Byte_11 "_";
BA_ "CI_ParId" SG_ 2566767886 ECU_HW_Id_Byte_11 "ESMD_08386";
BA_ "SPN" SG_ 2566767886 ECU_HW_Id_Byte_11 6714;
BA_ "CI_FullName" SG_ 2566767886 ECU_HW_Id_Byte_10 "_";
BA_ "CI_ParId" SG_ 2566767886 ECU_HW_Id_Byte_10 "ESMD_08386";
BA_ "SPN" SG_ 2566767886 ECU_HW_Id_Byte_10 6714;
BA_ "CI_FullName" SG_ 2566767886 ECU_HW_Id_Byte_09 "_";
BA_ "CI_ParId" SG_ 2566767886 ECU_HW_Id_Byte_09 "ESMD_08386";
BA_ "SPN" SG_ 2566767886 ECU_HW_Id_Byte_09 6714;
BA_ "CI_FullName" SG_ 2566767886 ECU_HW_Id_Byte_08 "_";
BA_ "CI_ParId" SG_ 2566767886 ECU_HW_Id_Byte_08 "ESMD_08386";
BA_ "SPN" SG_ 2566767886 ECU_HW_Id_Byte_08 6714;
BA_ "CI_FullName" SG_ 2566767886 ECU_HW_Id_Byte_07 "_";
BA_ "CI_ParId" SG_ 2566767886 ECU_HW_Id_Byte_07 "ESMD_08386";
BA_ "SPN" SG_ 2566767886 ECU_HW_Id_Byte_07 6714;
BA_ "CI_FullName" SG_ 2566767886 ECU_HW_Id_Byte_06 "_";
BA_ "CI_ParId" SG_ 2566767886 ECU_HW_Id_Byte_06 "ESMD_08386";
BA_ "SPN" SG_ 2566767886 ECU_HW_Id_Byte_06 6714;
BA_ "CI_FullName" SG_ 2566767886 ECU_HW_Id_Byte_05 "_";
BA_ "CI_ParId" SG_ 2566767886 ECU_HW_Id_Byte_05 "ESMD_08386";
BA_ "SPN" SG_ 2566767886 ECU_HW_Id_Byte_05 6714;
BA_ "CI_FullName" SG_ 2566767886 ECU_HW_Id_Byte_04 "_";
BA_ "CI_ParId" SG_ 2566767886 ECU_HW_Id_Byte_04 "ESMD_08386";
BA_ "SPN" SG_ 2566767886 ECU_HW_Id_Byte_04 6714;
BA_ "CI_FullName" SG_ 2566767886 ECU_HW_Id_Byte_03 "_";
BA_ "CI_ParId" SG_ 2566767886 ECU_HW_Id_Byte_03 "ESMD_08386";
BA_ "SPN" SG_ 2566767886 ECU_HW_Id_Byte_03 6714;
BA_ "CI_FullName" SG_ 2566767886 ECU_HW_Id_Byte_02 "_";
BA_ "CI_ParId" SG_ 2566767886 ECU_HW_Id_Byte_02 "ESMD_08386";
BA_ "SPN" SG_ 2566767886 ECU_HW_Id_Byte_02 6714;
BA_ "CI_FullName" SG_ 2566767886 ECU_HW_Id_Byte_01 "_";
BA_ "CI_ParId" SG_ 2566767886 ECU_HW_Id_Byte_01 "ESMD_08386";
BA_ "SPN" SG_ 2566767886 ECU_HW_Id_Byte_01 6714;
BA_ "CI_FullName" SG_ 2566767886 ECU_Locat "ECU Location";
BA_ "CI_ParId" SG_ 2566767886 ECU_Locat "ESMD_01162";
BA_ "CI_SLOT_Name" SG_ 2566767886 ECU_Locat "SAEatad0200";
BA_ "SPN" SG_ 2566767886 ECU_Locat 2903;
BA_ "CI_FullName" SG_ 2566767886 ECU_ManufctName "ECU Manufacturer Name";
BA_ "CI_ParId" SG_ 2566767886 ECU_ManufctName "ESMD_08390";
BA_ "CI_SLOT_Name" SG_ 2566767886 ECU_ManufctName "SAEatad0200";
BA_ "SPN" SG_ 2566767886 ECU_ManufctName 4304;
BA_ "CI_FullName" SG_ 2566767886 ECU_PN "ECU Part Number";
BA_ "CI_ParId" SG_ 2566767886 ECU_PN "ESMD_01163";
BA_ "CI_SLOT_Name" SG_ 2566767886 ECU_PN "SAEatad0200";
BA_ "SPN" SG_ 2566767886 ECU_PN 2901;
BA_ "CI_FullName" SG_ 2566767886 ECU_SN "ECU Serial Number";
BA_ "CI_ParId" SG_ 2566767886 ECU_SN "ESMD_01167";
BA_ "CI_SLOT_Name" SG_ 2566767886 ECU_SN "SAEatad0200";
BA_ "SPN" SG_ 2566767886 ECU_SN 2902;
BA_ "CI_FullName" SG_ 2566767886 ECU_Typ "ECU Type";
BA_ "CI_ParId" SG_ 2566767886 ECU_Typ "ESMD_01168";
BA_ "CI_SLOT_Name" SG_ 2566767886 ECU_Typ "SAEatad0200";
BA_ "SPN" SG_ 2566767886 ECU_Typ 2904;
BA_ "CI_FullName" SG_ 2566767886 ECUHardwareVersionIdentification "_";
BA_ "CI_ParId" SG_ 2566767886 ECUHardwareVersionIdentification "ESMD_08386";
BA_ "SPN" SG_ 2566767886 ECUHardwareVersionIdentification 6714;
BA_ "CI_FullName" SG_ 2566834702 AmbrWarnLmp "Amber Warning Lamp";
BA_ "CI_ParId" SG_ 2566834702 AmbrWarnLmp "ESMD_00554";
BA_ "CI_SLOT_Name" SG_ 2566834702 AmbrWarnLmp "SAEbs02";
BA_ "SPN" SG_ 2566834702 AmbrWarnLmp 624;
BA_ "CI_FullName" SG_ 2566834702 DTC_01 "Diagnostic Trouble Code 01";
BA_ "CI_ParId" SG_ 2566834702 DTC_01 "ESMD_01142";
BA_ "CI_FullName" SG_ 2566834702 DTC_02 "Diagnostic Trouble Code 02";
BA_ "CI_ParId" SG_ 2566834702 DTC_02 "ESMD_01143";
BA_ "CI_FullName" SG_ 2566834702 DTC_03 "Diagnostic Trouble Code 03";
BA_ "CI_ParId" SG_ 2566834702 DTC_03 "ESMD_01144";
BA_ "CI_FullName" SG_ 2566834702 DTC_04 "Diagnostic Trouble Code 04";
BA_ "CI_ParId" SG_ 2566834702 DTC_04 "ESMD_01145";
BA_ "CI_FullName" SG_ 2566834702 DTC_05 "Diagnostic Trouble Code 05";
BA_ "CI_ParId" SG_ 2566834702 DTC_05 "ESMD_01146";
BA_ "CI_FullName" SG_ 2566834702 DTC_06 "Diagnostic Trouble Code 06";
BA_ "CI_ParId" SG_ 2566834702 DTC_06 "ESMD_03832";
BA_ "CI_FullName" SG_ 2566834702 DTC_07 "Diagnostic Trouble Code 07";
BA_ "CI_ParId" SG_ 2566834702 DTC_07 "ESMD_03833";
BA_ "CI_FullName" SG_ 2566834702 DTC_08 "Diagnostic Trouble Code 08";
BA_ "CI_ParId" SG_ 2566834702 DTC_08 "ESMD_03834";
BA_ "CI_FullName" SG_ 2566834702 DTC_09 "Diagnostic Trouble Code 09";
BA_ "CI_ParId" SG_ 2566834702 DTC_09 "ESMD_03835";
BA_ "CI_FullName" SG_ 2566834702 DTC_10 "Diagnostic Trouble Code 10";
BA_ "CI_ParId" SG_ 2566834702 DTC_10 "ESMD_03836";
BA_ "CI_FullName" SG_ 2566834702 DTC_11 "Diagnostic Trouble Code 11";
BA_ "CI_ParId" SG_ 2566834702 DTC_11 "ESMD_03837";
BA_ "CI_FullName" SG_ 2566834702 DTC_12 "Diagnostic Trouble Code 12";
BA_ "CI_ParId" SG_ 2566834702 DTC_12 "ESMD_03838";
BA_ "CI_FullName" SG_ 2566834702 DTC_13 "Diagnostic Trouble Code 13";
BA_ "CI_ParId" SG_ 2566834702 DTC_13 "ESMD_03839";
BA_ "CI_FullName" SG_ 2566834702 DTC_14 "Diagnostic Trouble Code 14";
BA_ "CI_ParId" SG_ 2566834702 DTC_14 "ESMD_03840";
BA_ "CI_FullName" SG_ 2566834702 DTC_15 "Diagnostic Trouble Code 15";
BA_ "CI_ParId" SG_ 2566834702 DTC_15 "ESMD_03841";
BA_ "CI_FullName" SG_ 2566834702 DTC_16 "Diagnostic Trouble Code 16";
BA_ "CI_ParId" SG_ 2566834702 DTC_16 "ESMD_03842";
BA_ "CI_FullName" SG_ 2566834702 DTC_17 "Diagnostic Trouble Code 17";
BA_ "CI_ParId" SG_ 2566834702 DTC_17 "ESMD_03843";
BA_ "CI_FullName" SG_ 2566834702 DTC_18 "Diagnostic Trouble Code 18";
BA_ "CI_ParId" SG_ 2566834702 DTC_18 "ESMD_03844";
BA_ "CI_FullName" SG_ 2566834702 DTC_19 "Diagnostic Trouble Code 19";
BA_ "CI_ParId" SG_ 2566834702 DTC_19 "ESMD_03845";
BA_ "CI_FullName" SG_ 2566834702 DTC_20 "Diagnostic Trouble Code 20";
BA_ "CI_ParId" SG_ 2566834702 DTC_20 "ESMD_03846";
BA_ "CI_FullName" SG_ 2566834702 FlashAmbrWarnLmpAWL "Flash Amber Warning Lamp (AWL)";
BA_ "CI_ParId" SG_ 2566834702 FlashAmbrWarnLmpAWL "ESMD_01963";
BA_ "CI_SLOT_Name" SG_ 2566834702 FlashAmbrWarnLmpAWL "SAEbs02";
BA_ "SPN" SG_ 2566834702 FlashAmbrWarnLmpAWL 3040;
BA_ "CI_FullName" SG_ 2566834702 FlashMIL "Flash Malfunction Indicator Lamp";
BA_ "CI_ParId" SG_ 2566834702 FlashMIL "ESMD_01964";
BA_ "CI_SLOT_Name" SG_ 2566834702 FlashMIL "SAEbs02";
BA_ "SPN" SG_ 2566834702 FlashMIL 3038;
BA_ "CI_FullName" SG_ 2566834702 FlashProtLmp "Flash Protect Lamp";
BA_ "CI_ParId" SG_ 2566834702 FlashProtLmp "ESMD_01965";
BA_ "CI_SLOT_Name" SG_ 2566834702 FlashProtLmp "SAEbs02";
BA_ "SPN" SG_ 2566834702 FlashProtLmp 3041;
BA_ "CI_FullName" SG_ 2566834702 FlashRedStopLmpRSL "Flash Red Stop Lamp (RSL)";
BA_ "CI_ParId" SG_ 2566834702 FlashRedStopLmpRSL "ESMD_01966";
BA_ "CI_SLOT_Name" SG_ 2566834702 FlashRedStopLmpRSL "SAEbs02";
BA_ "SPN" SG_ 2566834702 FlashRedStopLmpRSL 3039;
BA_ "CI_FullName" SG_ 2566834702 MIL "Malfunction Indicator Lamp";
BA_ "CI_ParId" SG_ 2566834702 MIL "ESMD_02672";
BA_ "CI_SLOT_Name" SG_ 2566834702 MIL "SAEbs02";
BA_ "SPN" SG_ 2566834702 MIL 1213;
BA_ "CI_FullName" SG_ 2566834702 ProtLmp "Protect Lamp";
BA_ "CI_ParId" SG_ 2566834702 ProtLmp "ESMD_02904";
BA_ "CI_SLOT_Name" SG_ 2566834702 ProtLmp "SAEbs02";
BA_ "SPN" SG_ 2566834702 ProtLmp 987;
BA_ "CI_FullName" SG_ 2566834702 RedStopLmp "Red Stop Lamp";
BA_ "CI_ParId" SG_ 2566834702 RedStopLmp "ESMD_02945";
BA_ "CI_SLOT_Name" SG_ 2566834702 RedStopLmp "SAEbs02";
BA_ "SPN" SG_ 2566834702 RedStopLmp 623;
BA_ "CI_FullName" SG_ 2566834958 AmbrWarnLmp "Amber Warning Lamp";
BA_ "CI_ParId" SG_ 2566834958 AmbrWarnLmp "ESMD_00554";
BA_ "CI_SLOT_Name" SG_ 2566834958 AmbrWarnLmp "SAEbs02";
BA_ "SPN" SG_ 2566834958 AmbrWarnLmp 624;
BA_ "CI_FullName" SG_ 2566834958 DTC_01 "Diagnostic Trouble Code 01";
BA_ "CI_ParId" SG_ 2566834958 DTC_01 "ESMD_01142";
BA_ "CI_FullName" SG_ 2566834958 DTC_02 "Diagnostic Trouble Code 02";
BA_ "CI_ParId" SG_ 2566834958 DTC_02 "ESMD_01143";
BA_ "CI_FullName" SG_ 2566834958 DTC_03 "Diagnostic Trouble Code 03";
BA_ "CI_ParId" SG_ 2566834958 DTC_03 "ESMD_01144";
BA_ "CI_FullName" SG_ 2566834958 DTC_04 "Diagnostic Trouble Code 04";
BA_ "CI_ParId" SG_ 2566834958 DTC_04 "ESMD_01145";
BA_ "CI_FullName" SG_ 2566834958 DTC_05 "Diagnostic Trouble Code 05";
BA_ "CI_ParId" SG_ 2566834958 DTC_05 "ESMD_01146";
BA_ "CI_FullName" SG_ 2566834958 DTC_06 "Diagnostic Trouble Code 06";
BA_ "CI_ParId" SG_ 2566834958 DTC_06 "ESMD_03832";
BA_ "CI_FullName" SG_ 2566834958 DTC_07 "Diagnostic Trouble Code 07";
BA_ "CI_ParId" SG_ 2566834958 DTC_07 "ESMD_03833";
BA_ "CI_FullName" SG_ 2566834958 DTC_08 "Diagnostic Trouble Code 08";
BA_ "CI_ParId" SG_ 2566834958 DTC_08 "ESMD_03834";
BA_ "CI_FullName" SG_ 2566834958 DTC_09 "Diagnostic Trouble Code 09";
BA_ "CI_ParId" SG_ 2566834958 DTC_09 "ESMD_03835";
BA_ "CI_FullName" SG_ 2566834958 DTC_10 "Diagnostic Trouble Code 10";
BA_ "CI_ParId" SG_ 2566834958 DTC_10 "ESMD_03836";
BA_ "CI_FullName" SG_ 2566834958 DTC_11 "Diagnostic Trouble Code 11";
BA_ "CI_ParId" SG_ 2566834958 DTC_11 "ESMD_03837";
BA_ "CI_FullName" SG_ 2566834958 DTC_12 "Diagnostic Trouble Code 12";
BA_ "CI_ParId" SG_ 2566834958 DTC_12 "ESMD_03838";
BA_ "CI_FullName" SG_ 2566834958 DTC_13 "Diagnostic Trouble Code 13";
BA_ "CI_ParId" SG_ 2566834958 DTC_13 "ESMD_03839";
BA_ "CI_FullName" SG_ 2566834958 DTC_14 "Diagnostic Trouble Code 14";
BA_ "CI_ParId" SG_ 2566834958 DTC_14 "ESMD_03840";
BA_ "CI_FullName" SG_ 2566834958 DTC_15 "Diagnostic Trouble Code 15";
BA_ "CI_ParId" SG_ 2566834958 DTC_15 "ESMD_03841";
BA_ "CI_FullName" SG_ 2566834958 DTC_16 "Diagnostic Trouble Code 16";
BA_ "CI_ParId" SG_ 2566834958 DTC_16 "ESMD_03842";
BA_ "CI_FullName" SG_ 2566834958 DTC_17 "Diagnostic Trouble Code 17";
BA_ "CI_ParId" SG_ 2566834958 DTC_17 "ESMD_03843";
BA_ "CI_FullName" SG_ 2566834958 DTC_18 "Diagnostic Trouble Code 18";
BA_ "CI_ParId" SG_ 2566834958 DTC_18 "ESMD_03844";
BA_ "CI_FullName" SG_ 2566834958 DTC_19 "Diagnostic Trouble Code 19";
BA_ "CI_ParId" SG_ 2566834958 DTC_19 "ESMD_03845";
BA_ "CI_FullName" SG_ 2566834958 DTC_20 "Diagnostic Trouble Code 20";
BA_ "CI_ParId" SG_ 2566834958 DTC_20 "ESMD_03846";
BA_ "CI_FullName" SG_ 2566834958 FlashAmbrWarnLmpAWL "Flash Amber Warning Lamp (AWL)";
BA_ "CI_ParId" SG_ 2566834958 FlashAmbrWarnLmpAWL "ESMD_01963";
BA_ "CI_SLOT_Name" SG_ 2566834958 FlashAmbrWarnLmpAWL "SAEbs02";
BA_ "SPN" SG_ 2566834958 FlashAmbrWarnLmpAWL 3040;
BA_ "CI_FullName" SG_ 2566834958 FlashMIL "Flash Malfunction Indicator Lamp";
BA_ "CI_ParId" SG_ 2566834958 FlashMIL "ESMD_01964";
BA_ "CI_SLOT_Name" SG_ 2566834958 FlashMIL "SAEbs02";
BA_ "SPN" SG_ 2566834958 FlashMIL 3038;
BA_ "CI_FullName" SG_ 2566834958 FlashProtLmp "Flash Protect Lamp";
BA_ "CI_ParId" SG_ 2566834958 FlashProtLmp "ESMD_01965";
BA_ "CI_SLOT_Name" SG_ 2566834958 FlashProtLmp "SAEbs02";
BA_ "SPN" SG_ 2566834958 FlashProtLmp 3041;
BA_ "CI_FullName" SG_ 2566834958 FlashRedStopLmpRSL "Flash Red Stop Lamp (RSL)";
BA_ "CI_ParId" SG_ 2566834958 FlashRedStopLmpRSL "ESMD_01966";
BA_ "CI_SLOT_Name" SG_ 2566834958 FlashRedStopLmpRSL "SAEbs02";
BA_ "SPN" SG_ 2566834958 FlashRedStopLmpRSL 3039;
BA_ "CI_FullName" SG_ 2566834958 MIL "Malfunction Indicator Lamp";
BA_ "CI_ParId" SG_ 2566834958 MIL "ESMD_02672";
BA_ "CI_SLOT_Name" SG_ 2566834958 MIL "SAEbs02";
BA_ "SPN" SG_ 2566834958 MIL 1213;
BA_ "CI_FullName" SG_ 2566834958 ProtLmp "Protect Lamp";
BA_ "CI_ParId" SG_ 2566834958 ProtLmp "ESMD_02904";
BA_ "CI_SLOT_Name" SG_ 2566834958 ProtLmp "SAEbs02";
BA_ "SPN" SG_ 2566834958 ProtLmp 987;
BA_ "CI_FullName" SG_ 2566834958 RedStopLmp "Red Stop Lamp";
BA_ "CI_ParId" SG_ 2566834958 RedStopLmp "ESMD_02945";
BA_ "CI_SLOT_Name" SG_ 2566834958 RedStopLmp "SAEbs02";
BA_ "SPN" SG_ 2566834958 RedStopLmp 623;
BA_ "CI_FullName" SG_ 2565799694 Rsrvd_1Bit "Reserved 1 Bit";
BA_ "CI_ParId" SG_ 2565799694 Rsrvd_1Bit "ESMD_23062";
BA_ "GenSigAutoGenSnd" SG_ 2565799694 ArbAddrCap 0;
BA_ "GenSigAutoGenDsp" SG_ 2565799694 ArbAddrCap 0;
BA_ "CI_RepetitionComplemented" SG_ 2565799694 ArbAddrCap 2;
BA_ "CI_FullName" SG_ 2565799694 ArbAddrCap "Arbitrary Address Capable";
BA_ "CI_ParId" SG_ 2565799694 ArbAddrCap "ESMD_08115";
BA_ "SPN" SG_ 2565799694 ArbAddrCap 2844;
BA_ "GenSigAutoGenSnd" SG_ 2565799694 ECU_Inst 0;
BA_ "GenSigAutoGenDsp" SG_ 2565799694 ECU_Inst 0;
BA_ "CI_RepetitionComplemented" SG_ 2565799694 ECU_Inst 2;
BA_ "CI_FullName" SG_ 2565799694 ECU_Inst "ECU Instance";
BA_ "CI_ParId" SG_ 2565799694 ECU_Inst "ESMD_08387";
BA_ "SPN" SG_ 2565799694 ECU_Inst 2840;
BA_ "GenSigAutoGenSnd" SG_ 2565799694 Funct 0;
BA_ "GenSigAutoGenDsp" SG_ 2565799694 Funct 0;
BA_ "CI_RepetitionComplemented" SG_ 2565799694 Funct 2;
BA_ "CI_FullName" SG_ 2565799694 Funct "Function";
BA_ "CI_ParId" SG_ 2565799694 Funct "ESMD_08663";
BA_ "SPN" SG_ 2565799694 Funct 2841;
BA_ "GenSigAutoGenSnd" SG_ 2565799694 FunctInst 0;
BA_ "GenSigAutoGenDsp" SG_ 2565799694 FunctInst 0;
BA_ "CI_RepetitionComplemented" SG_ 2565799694 FunctInst 2;
BA_ "CI_FullName" SG_ 2565799694 FunctInst "Function Instance";
BA_ "CI_ParId" SG_ 2565799694 FunctInst "ESMD_08670";
BA_ "SPN" SG_ 2565799694 FunctInst 2839;
BA_ "GenSigAutoGenSnd" SG_ 2565799694 IdNum 0;
BA_ "GenSigAutoGenDsp" SG_ 2565799694 IdNum 0;
BA_ "CI_RepetitionComplemented" SG_ 2565799694 IdNum 2;
BA_ "CI_FullName" SG_ 2565799694 IdNum "Identity Number";
BA_ "CI_ParId" SG_ 2565799694 IdNum "ESMD_08726";
BA_ "SPN" SG_ 2565799694 IdNum 2837;
BA_ "GenSigAutoGenSnd" SG_ 2565799694 IndstryGrp 0;
BA_ "GenSigAutoGenDsp" SG_ 2565799694 IndstryGrp 0;
BA_ "CI_RepetitionComplemented" SG_ 2565799694 IndstryGrp 2;
BA_ "CI_FullName" SG_ 2565799694 IndstryGrp "Industry Group";
BA_ "CI_ParId" SG_ 2565799694 IndstryGrp "ESMD_02136";
BA_ "SPN" SG_ 2565799694 IndstryGrp 2846;
BA_ "GenSigAutoGenSnd" SG_ 2565799694 ManufctCod 0;
BA_ "GenSigAutoGenDsp" SG_ 2565799694 ManufctCod 0;
BA_ "CI_RepetitionComplemented" SG_ 2565799694 ManufctCod 2;
BA_ "CI_FullName" SG_ 2565799694 ManufctCod "Manufacturer Code";
BA_ "CI_ParId" SG_ 2565799694 ManufctCod "ESMD_08852";
BA_ "SPN" SG_ 2565799694 ManufctCod 2838;
BA_ "SigType" SG_ 2565799694 ManufctCod 1;
BA_ "GenSigAutoGenSnd" SG_ 2565799694 VehSys 0;
BA_ "GenSigAutoGenDsp" SG_ 2565799694 VehSys 0;
BA_ "CI_RepetitionComplemented" SG_ 2565799694 VehSys 2;
BA_ "CI_FullName" SG_ 2565799694 VehSys "Vehicle system";
BA_ "CI_ParId" SG_ 2565799694 VehSys "ESMD_16375";
BA_ "SPN" SG_ 2565799694 VehSys 2842;
BA_ "GenSigAutoGenSnd" SG_ 2565799694 VehSysInst 0;
BA_ "GenSigAutoGenDsp" SG_ 2565799694 VehSysInst 0;
BA_ "CI_RepetitionComplemented" SG_ 2565799694 VehSysInst 2;
BA_ "CI_FullName" SG_ 2565799694 VehSysInst "Vehicle System Instance";
BA_ "CI_ParId" SG_ 2565799694 VehSysInst "ESMD_09571";
BA_ "SPN" SG_ 2565799694 VehSysInst 2843;
BA_ "GenSigAutoGenSnd" SG_ 2632777486 TotNumPktEoMA 0;
BA_ "GenSigAutoGenDsp" SG_ 2632777486 TotNumPktEoMA 0;
BA_ "CI_RepetitionComplemented" SG_ 2632777486 TotNumPktEoMA 2;
BA_ "CI_FullName" SG_ 2632777486 TotNumPktEoMA "_";
BA_ "CI_ParId" SG_ 2632777486 TotNumPktEoMA "ESMD_03436";
BA_ "SPN" SG_ 2632777486 TotNumPktEoMA 2565;
BA_ "GenSigAutoGenSnd" SG_ 2632777486 CByteTPCM 0;
BA_ "GenSigAutoGenDsp" SG_ 2632777486 CByteTPCM 0;
BA_ "CI_RepetitionComplemented" SG_ 2632777486 CByteTPCM 2;
BA_ "CI_FullName" SG_ 2632777486 CByteTPCM "Control Byte (TP.CM)";
BA_ "CI_ParId" SG_ 2632777486 CByteTPCM "ESMD_00941";
BA_ "SPN" SG_ 2632777486 CByteTPCM 2556;
BA_ "GenSigAutoGenSnd" SG_ 2632777486 ConnAbrtReason 0;
BA_ "GenSigAutoGenDsp" SG_ 2632777486 ConnAbrtReason 0;
BA_ "CI_RepetitionComplemented" SG_ 2632777486 ConnAbrtReason 2;
BA_ "CI_FullName" SG_ 2632777486 ConnAbrtReason "Connection Abort Reason";
BA_ "CI_ParId" SG_ 2632777486 ConnAbrtReason "ESMD_00939";
BA_ "SPN" SG_ 2632777486 ConnAbrtReason 2570;
BA_ "GenSigAutoGenSnd" SG_ 2632777486 MaxNumPktTPCM_RTS 0;
BA_ "GenSigAutoGenDsp" SG_ 2632777486 MaxNumPktTPCM_RTS 0;
BA_ "CI_RepetitionComplemented" SG_ 2632777486 MaxNumPktTPCM_RTS 2;
BA_ "CI_FullName" SG_ 2632777486 MaxNumPktTPCM_RTS "Maximum Number of Packets (TP.CM_RTS)";
BA_ "CI_ParId" SG_ 2632777486 MaxNumPktTPCM_RTS "ESMD_02684";
BA_ "SPN" SG_ 2632777486 MaxNumPktTPCM_RTS 2559;
BA_ "GenSigAutoGenSnd" SG_ 2632777486 NumPktSentTPCM_CTS 0;
BA_ "GenSigAutoGenDsp" SG_ 2632777486 NumPktSentTPCM_CTS 0;
BA_ "CI_RepetitionComplemented" SG_ 2632777486 NumPktSentTPCM_CTS 2;
BA_ "CI_FullName" SG_ 2632777486 NumPktSentTPCM_CTS "Number of Packets that can be sent (TP.CM_CTS)";
BA_ "CI_ParId" SG_ 2632777486 NumPktSentTPCM_CTS "ESMD_02790";
BA_ "SPN" SG_ 2632777486 NumPktSentTPCM_CTS 2561;
BA_ "GenSigAutoGenSnd" SG_ 2632777486 NxtPktNumSentTPCM_CTS 0;
BA_ "GenSigAutoGenDsp" SG_ 2632777486 NxtPktNumSentTPCM_CTS 0;
BA_ "CI_RepetitionComplemented" SG_ 2632777486 NxtPktNumSentTPCM_CTS 2;
BA_ "CI_FullName" SG_ 2632777486 NxtPktNumSentTPCM_CTS "Next Packet Number to be sent (TP.CM_CTS)";
BA_ "CI_ParId" SG_ 2632777486 NxtPktNumSentTPCM_CTS "ESMD_02740";
BA_ "SPN" SG_ 2632777486 NxtPktNumSentTPCM_CTS 2562;
BA_ "GenSigAutoGenSnd" SG_ 2632777486 PGN_PktMsgTPCM_BAM 0;
BA_ "GenSigAutoGenDsp" SG_ 2632777486 PGN_PktMsgTPCM_BAM 0;
BA_ "CI_RepetitionComplemented" SG_ 2632777486 PGN_PktMsgTPCM_BAM 2;
BA_ "CI_FullName" SG_ 2632777486 PGN_PktMsgTPCM_BAM "Parameter Group Number of the packeted message (TP.CM_BAM)";
BA_ "CI_ParId" SG_ 2632777486 PGN_PktMsgTPCM_BAM "ESMD_03861";
BA_ "SPN" SG_ 2632777486 PGN_PktMsgTPCM_BAM 2569;
BA_ "GenSigAutoGenSnd" SG_ 2632777486 PGN_PktMsgTPCM_ConnAbort 0;
BA_ "GenSigAutoGenDsp" SG_ 2632777486 PGN_PktMsgTPCM_ConnAbort 0;
BA_ "CI_RepetitionComplemented" SG_ 2632777486 PGN_PktMsgTPCM_ConnAbort 2;
BA_ "CI_FullName" SG_ 2632777486 PGN_PktMsgTPCM_ConnAbort "Parameter Group Number of the packeted message (TP.CM_Conn_Abort)";
BA_ "CI_ParId" SG_ 2632777486 PGN_PktMsgTPCM_ConnAbort "ESMD_03862";
BA_ "SPN" SG_ 2632777486 PGN_PktMsgTPCM_ConnAbort 2571;
BA_ "GenSigAutoGenSnd" SG_ 2632777486 PGN_PktMsgTPCM_CTS 0;
BA_ "GenSigAutoGenDsp" SG_ 2632777486 PGN_PktMsgTPCM_CTS 0;
BA_ "CI_RepetitionComplemented" SG_ 2632777486 PGN_PktMsgTPCM_CTS 2;
BA_ "CI_FullName" SG_ 2632777486 PGN_PktMsgTPCM_CTS "Parameter Group Number of the packeted message (TP.CM_CTS)";
BA_ "CI_ParId" SG_ 2632777486 PGN_PktMsgTPCM_CTS "ESMD_03859";
BA_ "SPN" SG_ 2632777486 PGN_PktMsgTPCM_CTS 2563;
BA_ "GenSigAutoGenSnd" SG_ 2632777486 PGN_PktMsgTPCM_RTS 0;
BA_ "GenSigAutoGenDsp" SG_ 2632777486 PGN_PktMsgTPCM_RTS 0;
BA_ "CI_RepetitionComplemented" SG_ 2632777486 PGN_PktMsgTPCM_RTS 2;
BA_ "CI_FullName" SG_ 2632777486 PGN_PktMsgTPCM_RTS "Parameter Group Number of the packeted message (TP.CM_RTS)";
BA_ "CI_ParId" SG_ 2632777486 PGN_PktMsgTPCM_RTS "ESMD_02869";
BA_ "SPN" SG_ 2632777486 PGN_PktMsgTPCM_RTS 2560;
BA_ "CI_FullName" SG_ 2632777486 PGN_PktMsgTPCM_RTS2 "Parameter Group Number of the packeted message (TP.CM_RTS) 2";
BA_ "CI_ParId" SG_ 2632777486 PGN_PktMsgTPCM_RTS2 "ESMD_03860";
BA_ "SPN" SG_ 2632777486 PGN_PktMsgTPCM_RTS2 2566;
BA_ "GenSigAutoGenSnd" SG_ 2632777486 TotMsgSizeBAM 0;
BA_ "GenSigAutoGenDsp" SG_ 2632777486 TotMsgSizeBAM 0;
BA_ "CI_RepetitionComplemented" SG_ 2632777486 TotMsgSizeBAM 2;
BA_ "CI_FullName" SG_ 2632777486 TotMsgSizeBAM "_";
BA_ "CI_ParId" SG_ 2632777486 TotMsgSizeBAM "ESMD_03432";
BA_ "SPN" SG_ 2632777486 TotMsgSizeBAM 2567;
BA_ "GenSigAutoGenSnd" SG_ 2632777486 TotMsgSizeEoMA 0;
BA_ "GenSigAutoGenDsp" SG_ 2632777486 TotMsgSizeEoMA 0;
BA_ "CI_RepetitionComplemented" SG_ 2632777486 TotMsgSizeEoMA 2;
BA_ "CI_FullName" SG_ 2632777486 TotMsgSizeEoMA "_";
BA_ "CI_ParId" SG_ 2632777486 TotMsgSizeEoMA "ESMD_03433";
BA_ "SPN" SG_ 2632777486 TotMsgSizeEoMA 2564;
BA_ "GenSigAutoGenSnd" SG_ 2632777486 TotMsgSizeTPCM_RTS 0;
BA_ "GenSigAutoGenDsp" SG_ 2632777486 TotMsgSizeTPCM_RTS 0;
BA_ "CI_RepetitionComplemented" SG_ 2632777486 TotMsgSizeTPCM_RTS 2;
BA_ "CI_FullName" SG_ 2632777486 TotMsgSizeTPCM_RTS "Total Message Size (TP.CM_RTS)";
BA_ "CI_ParId" SG_ 2632777486 TotMsgSizeTPCM_RTS "ESMD_03431";
BA_ "SPN" SG_ 2632777486 TotMsgSizeTPCM_RTS 2557;
BA_ "GenSigAutoGenSnd" SG_ 2632777486 TotNumPktBAM 0;
BA_ "GenSigAutoGenDsp" SG_ 2632777486 TotNumPktBAM 0;
BA_ "CI_RepetitionComplemented" SG_ 2632777486 TotNumPktBAM 2;
BA_ "CI_FullName" SG_ 2632777486 TotNumPktBAM "_";
BA_ "CI_ParId" SG_ 2632777486 TotNumPktBAM "ESMD_03435";
BA_ "SPN" SG_ 2632777486 TotNumPktBAM 2568;
BA_ "GenSigAutoGenSnd" SG_ 2632777486 TotNumPktTPCM_RTS 0;
BA_ "GenSigAutoGenDsp" SG_ 2632777486 TotNumPktTPCM_RTS 0;
BA_ "CI_RepetitionComplemented" SG_ 2632777486 TotNumPktTPCM_RTS 2;
BA_ "CI_FullName" SG_ 2632777486 TotNumPktTPCM_RTS "Total Number of Packets (TP.CM_RTS)";
BA_ "CI_ParId" SG_ 2632777486 TotNumPktTPCM_RTS "ESMD_03434";
BA_ "SPN" SG_ 2632777486 TotNumPktTPCM_RTS 2558;
BA_ "GenSigAutoGenSnd" SG_ 2565352206 AddrAccssDeny 0;
BA_ "GenSigAutoGenDsp" SG_ 2565352206 AddrAccssDeny 0;
BA_ "CI_FullName" SG_ 2565352206 AddrAccssDeny "Address Access Denied";
BA_ "CI_ParId" SG_ 2565352206 AddrAccssDeny "ESMD_00040";
BA_ "SPN" SG_ 2565352206 AddrAccssDeny 3292;
BA_ "GenSigAutoGenSnd" SG_ 2565352206 AddrAck 0;
BA_ "GenSigAutoGenDsp" SG_ 2565352206 AddrAck 0;
BA_ "CI_FullName" SG_ 2565352206 AddrAck "Address Acknowledged";
BA_ "CI_ParId" SG_ 2565352206 AddrAck "ESMD_00041";
BA_ "SPN" SG_ 2565352206 AddrAck 3290;
BA_ "GenSigAutoGenSnd" SG_ 2565352206 AddrBusy 0;
BA_ "GenSigAutoGenDsp" SG_ 2565352206 AddrBusy 0;
BA_ "CI_FullName" SG_ 2565352206 AddrBusy "Address Busy";
BA_ "CI_ParId" SG_ 2565352206 AddrBusy "ESMD_00043";
BA_ "SPN" SG_ 2565352206 AddrBusy 3293;
BA_ "GenSigAutoGenSnd" SG_ 2565352206 AddrNegAck 0;
BA_ "GenSigAutoGenDsp" SG_ 2565352206 AddrNegAck 0;
BA_ "CI_FullName" SG_ 2565352206 AddrNegAck "Address Negative Acknowledgement";
BA_ "CI_ParId" SG_ 2565352206 AddrNegAck "ESMD_00044";
BA_ "SPN" SG_ 2565352206 AddrNegAck 3291;
BA_ "GenSigAutoGenSnd" SG_ 2565352206 CByteAckm 0;
BA_ "GenSigAutoGenDsp" SG_ 2565352206 CByteAckm 0;
BA_ "CI_FullName" SG_ 2565352206 CByteAckm "Control Byte (ACKM)";
BA_ "CI_ParId" SG_ 2565352206 CByteAckm "ESMD_00942";
BA_ "SPN" SG_ 2565352206 CByteAckm 2541;
BA_ "SigType" SG_ 2565352206 CByteAckm 1;
BA_ "GenSigAutoGenSnd" SG_ 2565352206 GrpFunctValAck 0;
BA_ "GenSigAutoGenDsp" SG_ 2565352206 GrpFunctValAck 0;
BA_ "CI_RepetitionComplemented" SG_ 2565352206 GrpFunctValAck 2;
BA_ "CI_FullName" SG_ 2565352206 GrpFunctValAck "Group Function Value (ACK)";
BA_ "CI_ParId" SG_ 2565352206 GrpFunctValAck "ESMD_02063";
BA_ "SPN" SG_ 2565352206 GrpFunctValAck 2542;
BA_ "SigType" SG_ 2565352206 GrpFunctValAck 1;
BA_ "CI_FullName" SG_ 2565352206 PGN_RQST2_0E_28 "Parameter Group Number (RQST2)";
BA_ "CI_ParId" SG_ 2565352206 PGN_RQST2_0E_28 "ESMD_20981";
BA_ "SPN" SG_ 2565352206 PGN_RQST2_0E_28 2574;
BA_ "SigType" SG_ 2565352206 PGN_RQST2_0E_28 6;
BA_ "CI_FullName" SG_ 2560830222 DTC_01 "Diagnostic Trouble Code 01";
BA_ "CI_ParId" SG_ 2560830222 DTC_01 "ESMD_01142";
BA_ "CI_FullName" SG_ 2560830222 DTCxAmbrWarnLmpSupp_andSts "DTCx Amber Warning Lamp Support & Status";
BA_ "CI_ParId" SG_ 2560830222 DTCxAmbrWarnLmpSupp_andSts "ESMD_01157";
BA_ "SPN" SG_ 2560830222 DTCxAmbrWarnLmpSupp_andSts 4115;
BA_ "CI_FullName" SG_ 2560830222 DTCxFlashAmbrWarnLmpSupp_andSts "DTCx Flash Amber Warning Lamp Support & Status";
BA_ "CI_ParId" SG_ 2560830222 DTCxFlashAmbrWarnLmpSupp_andSts "ESMD_01156";
BA_ "SPN" SG_ 2560830222 DTCxFlashAmbrWarnLmpSupp_andSts 4119;
BA_ "CI_FullName" SG_ 2560830222 DTCxFlashMIL_Supp_andSts "DTCx Flash Malfunction Indicator Lamp Support & Status";
BA_ "CI_ParId" SG_ 2560830222 DTCxFlashMIL_Supp_andSts "ESMD_01147";
BA_ "SPN" SG_ 2560830222 DTCxFlashMIL_Supp_andSts 4117;
BA_ "CI_FullName" SG_ 2560830222 DTCxFlashProtLmpSupp_andSts "DTCx Flash Protect Lamp Support & Status";
BA_ "CI_ParId" SG_ 2560830222 DTCxFlashProtLmpSupp_andSts "ESMD_01149";
BA_ "SPN" SG_ 2560830222 DTCxFlashProtLmpSupp_andSts 4120;
BA_ "CI_FullName" SG_ 2560830222 DTCxFlashRedStopLmpSupp_andSts "DTCx Flash Red Stop Lamp Support & Status";
BA_ "CI_ParId" SG_ 2560830222 DTCxFlashRedStopLmpSupp_andSts "ESMD_01151";
BA_ "SPN" SG_ 2560830222 DTCxFlashRedStopLmpSupp_andSts 4118;
BA_ "CI_FullName" SG_ 2560830222 DTCxMIL_Supp_andSts "DTCx Malfunction Indicator Lamp Support & Status";
BA_ "CI_ParId" SG_ 2560830222 DTCxMIL_Supp_andSts "ESMD_01148";
BA_ "SPN" SG_ 2560830222 DTCxMIL_Supp_andSts 4113;
BA_ "CI_FullName" SG_ 2560830222 DTCxProtLmpSupp_andSts "DTCx Protect Lamp Support & Status";
BA_ "CI_ParId" SG_ 2560830222 DTCxProtLmpSupp_andSts "ESMD_01150";
BA_ "SPN" SG_ 2560830222 DTCxProtLmpSupp_andSts 4116;
BA_ "CI_FullName" SG_ 2560830222 DTCxRedStopLmpSupp_andSts "DTCx Red Stop Lamp Support & Status";
BA_ "CI_ParId" SG_ 2560830222 DTCxRedStopLmpSupp_andSts "ESMD_01152";
BA_ "SPN" SG_ 2560830222 DTCxRedStopLmpSupp_andSts 4114;
BA_ "CI_ParId" SG_ 2565537579 PGN_RQST_2B "ESMD_20296";
BA_ "SPN" SG_ 2565537579 PGN_RQST_2B 2540;
BA_ "SigType" SG_ 2565537579 PGN_RQST_2B 6;
BA_ "CI_FullName" SG_ 2565475883 PGN_RQST_2B_0E "Parameter Group Number (RQST)";
BA_ "CI_ParId" SG_ 2565475883 PGN_RQST_2B_0E "ESMD_27955";
BA_ "SPN" SG_ 2565475883 PGN_RQST_2B_0E 2540;
BA_ "GenSigAutoGenSnd" SG_ 2564487438 BlkSize 0;
BA_ "GenSigAutoGenDsp" SG_ 2564487438 BlkSize 0;
BA_ "CI_RepetitionComplemented" SG_ 2564487438 BlkSize 2;
BA_ "CI_FullName" SG_ 2564487438 BlkSize "Block Size";
BA_ "CI_ParId" SG_ 2564487438 BlkSize "ESMD_00809";
BA_ "GenSigAutoGenSnd" SG_ 2564487438 FlowSts 0;
BA_ "GenSigAutoGenDsp" SG_ 2564487438 FlowSts 0;
BA_ "CI_RepetitionComplemented" SG_ 2564487438 FlowSts 2;
BA_ "CI_FullName" SG_ 2564487438 FlowSts "Flow Status";
BA_ "CI_ParId" SG_ 2564487438 FlowSts "ESMD_01968";
BA_ "GenSigAutoGenSnd" SG_ 2564487438 N1FrameDataLen 0;
BA_ "GenSigAutoGenDsp" SG_ 2564487438 N1FrameDataLen 0;
BA_ "CI_RepetitionComplemented" SG_ 2564487438 N1FrameDataLen 2;
BA_ "CI_FullName" SG_ 2564487438 N1FrameDataLen "First Frame Data Length";
BA_ "CI_ParId" SG_ 2564487438 N1FrameDataLen "ESMD_01962";
BA_ "GenSigAutoGenSnd" SG_ 2564487438 ProtocCntrlInfo 0;
BA_ "GenSigAutoGenDsp" SG_ 2564487438 ProtocCntrlInfo 0;
BA_ "CI_RepetitionComplemented" SG_ 2564487438 ProtocCntrlInfo 2;
BA_ "CI_FullName" SG_ 2564487438 ProtocCntrlInfo "Protocol Control Information";
BA_ "CI_ParId" SG_ 2564487438 ProtocCntrlInfo "ESMD_02905";
BA_ "GenSigAutoGenSnd" SG_ 2564487438 SepTime 0;
BA_ "GenSigAutoGenDsp" SG_ 2564487438 SepTime 0;
BA_ "CI_RepetitionComplemented" SG_ 2564487438 SepTime 2;
BA_ "CI_FullName" SG_ 2564487438 SepTime "Separation Time";
BA_ "CI_ParId" SG_ 2564487438 SepTime "ESMD_03113";
BA_ "GenSigAutoGenSnd" SG_ 2564487438 SingFrameDataLen 0;
BA_ "GenSigAutoGenDsp" SG_ 2564487438 SingFrameDataLen 0;
BA_ "CI_RepetitionComplemented" SG_ 2564487438 SingFrameDataLen 2;
BA_ "CI_FullName" SG_ 2564487438 SingFrameDataLen "Single Frame Data Length";
BA_ "CI_ParId" SG_ 2564487438 SingFrameDataLen "ESMD_03135";
BA_ "GenSigAutoGenSnd" SG_ 2564487438 SN 0;
BA_ "GenSigAutoGenDsp" SG_ 2564487438 SN 0;
BA_ "CI_RepetitionComplemented" SG_ 2564487438 SN 2;
BA_ "CI_FullName" SG_ 2564487438 SN "Serial Number";
BA_ "CI_ParId" SG_ 2564487438 SN "ESMD_03138";
BA_ "GenSigAutoGenSnd" SG_ 2564427513 BlkSize 0;
BA_ "GenSigAutoGenDsp" SG_ 2564427513 BlkSize 0;
BA_ "CI_RepetitionComplemented" SG_ 2564427513 BlkSize 2;
BA_ "CI_FullName" SG_ 2564427513 BlkSize "Block Size";
BA_ "CI_ParId" SG_ 2564427513 BlkSize "ESMD_00809";
BA_ "GenSigAutoGenSnd" SG_ 2564427513 FlowSts 0;
BA_ "GenSigAutoGenDsp" SG_ 2564427513 FlowSts 0;
BA_ "CI_RepetitionComplemented" SG_ 2564427513 FlowSts 2;
BA_ "CI_FullName" SG_ 2564427513 FlowSts "Flow Status";
BA_ "CI_ParId" SG_ 2564427513 FlowSts "ESMD_01968";
BA_ "GenSigAutoGenSnd" SG_ 2564427513 N1FrameDataLen 0;
BA_ "GenSigAutoGenDsp" SG_ 2564427513 N1FrameDataLen 0;
BA_ "CI_RepetitionComplemented" SG_ 2564427513 N1FrameDataLen 2;
BA_ "CI_FullName" SG_ 2564427513 N1FrameDataLen "First Frame Data Length";
BA_ "CI_ParId" SG_ 2564427513 N1FrameDataLen "ESMD_01962";
BA_ "GenSigAutoGenSnd" SG_ 2564427513 ProtocCntrlInfo 0;
BA_ "GenSigAutoGenDsp" SG_ 2564427513 ProtocCntrlInfo 0;
BA_ "CI_RepetitionComplemented" SG_ 2564427513 ProtocCntrlInfo 2;
BA_ "CI_FullName" SG_ 2564427513 ProtocCntrlInfo "Protocol Control Information";
BA_ "CI_ParId" SG_ 2564427513 ProtocCntrlInfo "ESMD_02905";
BA_ "GenSigAutoGenSnd" SG_ 2564427513 SepTime 0;
BA_ "GenSigAutoGenDsp" SG_ 2564427513 SepTime 0;
BA_ "CI_RepetitionComplemented" SG_ 2564427513 SepTime 2;
BA_ "CI_FullName" SG_ 2564427513 SepTime "Separation Time";
BA_ "CI_ParId" SG_ 2564427513 SepTime "ESMD_03113";
BA_ "GenSigAutoGenSnd" SG_ 2564427513 SingFrameDataLen 0;
BA_ "GenSigAutoGenDsp" SG_ 2564427513 SingFrameDataLen 0;
BA_ "CI_RepetitionComplemented" SG_ 2564427513 SingFrameDataLen 2;
BA_ "CI_FullName" SG_ 2564427513 SingFrameDataLen "Single Frame Data Length";
BA_ "CI_ParId" SG_ 2564427513 SingFrameDataLen "ESMD_03135";
BA_ "GenSigAutoGenSnd" SG_ 2564427513 SN 0;
BA_ "GenSigAutoGenDsp" SG_ 2564427513 SN 0;
BA_ "CI_RepetitionComplemented" SG_ 2564427513 SN 2;
BA_ "CI_FullName" SG_ 2564427513 SN "Serial Number";
BA_ "CI_ParId" SG_ 2564427513 SN "ESMD_03138";
BA_ "GenSigAutoGenSnd" SG_ 2565351438 AddrAccssDeny 0;
BA_ "GenSigAutoGenDsp" SG_ 2565351438 AddrAccssDeny 0;
BA_ "CI_FullName" SG_ 2565351438 AddrAccssDeny "Address Access Denied";
BA_ "CI_ParId" SG_ 2565351438 AddrAccssDeny "ESMD_00040";
BA_ "SPN" SG_ 2565351438 AddrAccssDeny 3292;
BA_ "GenSigAutoGenSnd" SG_ 2565351438 AddrAck 0;
BA_ "GenSigAutoGenDsp" SG_ 2565351438 AddrAck 0;
BA_ "CI_FullName" SG_ 2565351438 AddrAck "Address Acknowledged";
BA_ "CI_ParId" SG_ 2565351438 AddrAck "ESMD_00041";
BA_ "SPN" SG_ 2565351438 AddrAck 3290;
BA_ "GenSigAutoGenSnd" SG_ 2565351438 AddrBusy 0;
BA_ "GenSigAutoGenDsp" SG_ 2565351438 AddrBusy 0;
BA_ "CI_FullName" SG_ 2565351438 AddrBusy "Address Busy";
BA_ "CI_ParId" SG_ 2565351438 AddrBusy "ESMD_00043";
BA_ "SPN" SG_ 2565351438 AddrBusy 3293;
BA_ "GenSigAutoGenSnd" SG_ 2565351438 AddrNegAck 0;
BA_ "GenSigAutoGenDsp" SG_ 2565351438 AddrNegAck 0;
BA_ "CI_FullName" SG_ 2565351438 AddrNegAck "Address Negative Acknowledgement";
BA_ "CI_ParId" SG_ 2565351438 AddrNegAck "ESMD_00044";
BA_ "SPN" SG_ 2565351438 AddrNegAck 3291;
BA_ "GenSigAutoGenSnd" SG_ 2565351438 CByteAckm 0;
BA_ "GenSigAutoGenDsp" SG_ 2565351438 CByteAckm 0;
BA_ "CI_FullName" SG_ 2565351438 CByteAckm "Control Byte (ACKM)";
BA_ "CI_ParId" SG_ 2565351438 CByteAckm "ESMD_00942";
BA_ "SPN" SG_ 2565351438 CByteAckm 2541;
BA_ "SigType" SG_ 2565351438 CByteAckm 1;
BA_ "GenSigAutoGenSnd" SG_ 2565351438 GrpFunctValAck 0;
BA_ "GenSigAutoGenDsp" SG_ 2565351438 GrpFunctValAck 0;
BA_ "CI_RepetitionComplemented" SG_ 2565351438 GrpFunctValAck 2;
BA_ "CI_FullName" SG_ 2565351438 GrpFunctValAck "Group Function Value (ACK)";
BA_ "CI_ParId" SG_ 2565351438 GrpFunctValAck "ESMD_02063";
BA_ "SPN" SG_ 2565351438 GrpFunctValAck 2542;
BA_ "SigType" SG_ 2565351438 GrpFunctValAck 1;
BA_ "CI_FullName" SG_ 2565351438 PGN_RQST2_0E_28 "Parameter Group Number (RQST2)";
BA_ "CI_ParId" SG_ 2565351438 PGN_RQST2_0E_28 "ESMD_20981";
BA_ "SPN" SG_ 2565351438 PGN_RQST2_0E_28 2574;
BA_ "SigType" SG_ 2565351438 PGN_RQST2_0E_28 6;
BA_ "CI_FullName" SG_ 2560829454 DTC_01 "Diagnostic Trouble Code 01";
BA_ "CI_ParId" SG_ 2560829454 DTC_01 "ESMD_01142";
BA_ "CI_FullName" SG_ 2560829454 DTCxAmbrWarnLmpSupp_andSts "DTCx Amber Warning Lamp Support & Status";
BA_ "CI_ParId" SG_ 2560829454 DTCxAmbrWarnLmpSupp_andSts "ESMD_01157";
BA_ "SPN" SG_ 2560829454 DTCxAmbrWarnLmpSupp_andSts 4115;
BA_ "CI_FullName" SG_ 2560829454 DTCxFlashAmbrWarnLmpSupp_andSts "DTCx Flash Amber Warning Lamp Support & Status";
BA_ "CI_ParId" SG_ 2560829454 DTCxFlashAmbrWarnLmpSupp_andSts "ESMD_01156";
BA_ "SPN" SG_ 2560829454 DTCxFlashAmbrWarnLmpSupp_andSts 4119;
BA_ "CI_FullName" SG_ 2560829454 DTCxFlashMIL_Supp_andSts "DTCx Flash Malfunction Indicator Lamp Support & Status";
BA_ "CI_ParId" SG_ 2560829454 DTCxFlashMIL_Supp_andSts "ESMD_01147";
BA_ "SPN" SG_ 2560829454 DTCxFlashMIL_Supp_andSts 4117;
BA_ "CI_FullName" SG_ 2560829454 DTCxFlashProtLmpSupp_andSts "DTCx Flash Protect Lamp Support & Status";
BA_ "CI_ParId" SG_ 2560829454 DTCxFlashProtLmpSupp_andSts "ESMD_01149";
BA_ "SPN" SG_ 2560829454 DTCxFlashProtLmpSupp_andSts 4120;
BA_ "CI_FullName" SG_ 2560829454 DTCxFlashRedStopLmpSupp_andSts "DTCx Flash Red Stop Lamp Support & Status";
BA_ "CI_ParId" SG_ 2560829454 DTCxFlashRedStopLmpSupp_andSts "ESMD_01151";
BA_ "SPN" SG_ 2560829454 DTCxFlashRedStopLmpSupp_andSts 4118;
BA_ "CI_FullName" SG_ 2560829454 DTCxMIL_Supp_andSts "DTCx Malfunction Indicator Lamp Support & Status";
BA_ "CI_ParId" SG_ 2560829454 DTCxMIL_Supp_andSts "ESMD_01148";
BA_ "SPN" SG_ 2560829454 DTCxMIL_Supp_andSts 4113;
BA_ "CI_FullName" SG_ 2560829454 DTCxProtLmpSupp_andSts "DTCx Protect Lamp Support & Status";
BA_ "CI_ParId" SG_ 2560829454 DTCxProtLmpSupp_andSts "ESMD_01150";
BA_ "SPN" SG_ 2560829454 DTCxProtLmpSupp_andSts 4116;
BA_ "CI_FullName" SG_ 2560829454 DTCxRedStopLmpSupp_andSts "DTCx Red Stop Lamp Support & Status";
BA_ "CI_ParId" SG_ 2560829454 DTCxRedStopLmpSupp_andSts "ESMD_01152";
BA_ "SPN" SG_ 2560829454 DTCxRedStopLmpSupp_andSts 4114;
BA_ "CI_ParId" SG_ 2565537576 PGN_RQST_28 "ESMD_20258";
BA_ "SPN" SG_ 2565537576 PGN_RQST_28 2540;
BA_ "SigType" SG_ 2565537576 PGN_RQST_28 6;
BA_ "CI_FullName" SG_ 2565475880 PGN_RQST_28_0E "Parameter Group Number (RQST)";
BA_ "CI_ParId" SG_ 2565475880 PGN_RQST_28_0E "ESMD_20285";
BA_ "SPN" SG_ 2565475880 PGN_RQST_28_0E 2540;
BA_ "GenSigAutoGenSnd" SG_ 2564489209 BlkSize 0;
BA_ "GenSigAutoGenDsp" SG_ 2564489209 BlkSize 0;
BA_ "CI_RepetitionComplemented" SG_ 2564489209 BlkSize 2;
BA_ "CI_FullName" SG_ 2564489209 BlkSize "Block Size";
BA_ "CI_ParId" SG_ 2564489209 BlkSize "ESMD_00809";
BA_ "GenSigAutoGenSnd" SG_ 2564489209 FlowSts 0;
BA_ "GenSigAutoGenDsp" SG_ 2564489209 FlowSts 0;
BA_ "CI_RepetitionComplemented" SG_ 2564489209 FlowSts 2;
BA_ "CI_FullName" SG_ 2564489209 FlowSts "Flow Status";
BA_ "CI_ParId" SG_ 2564489209 FlowSts "ESMD_01968";
BA_ "GenSigAutoGenSnd" SG_ 2564489209 N1FrameDataLen 0;
BA_ "GenSigAutoGenDsp" SG_ 2564489209 N1FrameDataLen 0;
BA_ "CI_RepetitionComplemented" SG_ 2564489209 N1FrameDataLen 2;
BA_ "CI_FullName" SG_ 2564489209 N1FrameDataLen "First Frame Data Length";
BA_ "CI_ParId" SG_ 2564489209 N1FrameDataLen "ESMD_01962";
BA_ "GenSigAutoGenSnd" SG_ 2564489209 ProtocCntrlInfo 0;
BA_ "GenSigAutoGenDsp" SG_ 2564489209 ProtocCntrlInfo 0;
BA_ "CI_RepetitionComplemented" SG_ 2564489209 ProtocCntrlInfo 2;
BA_ "CI_FullName" SG_ 2564489209 ProtocCntrlInfo "Protocol Control Information";
BA_ "CI_ParId" SG_ 2564489209 ProtocCntrlInfo "ESMD_02905";
BA_ "GenSigAutoGenSnd" SG_ 2564489209 SepTime 0;
BA_ "GenSigAutoGenDsp" SG_ 2564489209 SepTime 0;
BA_ "CI_RepetitionComplemented" SG_ 2564489209 SepTime 2;
BA_ "CI_FullName" SG_ 2564489209 SepTime "Separation Time";
BA_ "CI_ParId" SG_ 2564489209 SepTime "ESMD_03113";
BA_ "GenSigAutoGenSnd" SG_ 2564489209 SingFrameDataLen 0;
BA_ "GenSigAutoGenDsp" SG_ 2564489209 SingFrameDataLen 0;
BA_ "CI_RepetitionComplemented" SG_ 2564489209 SingFrameDataLen 2;
BA_ "CI_FullName" SG_ 2564489209 SingFrameDataLen "Single Frame Data Length";
BA_ "CI_ParId" SG_ 2564489209 SingFrameDataLen "ESMD_03135";
BA_ "GenSigAutoGenSnd" SG_ 2564489209 SN 0;
BA_ "GenSigAutoGenDsp" SG_ 2564489209 SN 0;
BA_ "CI_RepetitionComplemented" SG_ 2564489209 SN 2;
BA_ "CI_FullName" SG_ 2564489209 SN "Serial Number";
BA_ "CI_ParId" SG_ 2564489209 SN "ESMD_03138";
BA_ "CI_FullName" SG_ 2566848701 PTO_SpdSelInputSts_3 "PTO Speed Selector Input Status 3";
BA_ "CI_FullName" SG_ 2566848701 PTO_SpdSelInputSts_2 "PTO Speed Selector Input Status 2";
BA_ "CI_FullName" SG_ 2566848701 PTO_SpdSelInputSts_1 "PTO Speed Selector Input Status 1";
BA_ "CI_FullName" SG_ 2566848701 PTO_SpdSelStsFlag_5 "PTO Speed Selector Status Flag 5";
BA_ "CI_ParId" SG_ 2566848701 PTO_SpdSelStsFlag_5 "NWD-1824";
BA_ "CI_SLOT_Name" SG_ 2566848701 PTO_SpdSelStsFlag_5 "SAEbs01";
BA_ "SPN" SG_ 2566848701 PTO_SpdSelStsFlag_5 522439;
BA_ "CI_FullName" SG_ 2566848701 PTO_SpdSelStsFlag_4 "PTO Speed Selector Status Flag 4";
BA_ "CI_ParId" SG_ 2566848701 PTO_SpdSelStsFlag_4 "NWD-1823";
BA_ "CI_SLOT_Name" SG_ 2566848701 PTO_SpdSelStsFlag_4 "SAEbs01";
BA_ "SPN" SG_ 2566848701 PTO_SpdSelStsFlag_4 522438;
BA_ "CI_FullName" SG_ 2566848701 PTO_SpdSelStsFlag_3 "PTO Speed Selector Status Flag 3";
BA_ "CI_ParId" SG_ 2566848701 PTO_SpdSelStsFlag_3 "NWD-1822";
BA_ "CI_SLOT_Name" SG_ 2566848701 PTO_SpdSelStsFlag_3 "SAEbs01";
BA_ "SPN" SG_ 2566848701 PTO_SpdSelStsFlag_3 522437;
BA_ "CI_FullName" SG_ 2566848701 PTO_SpdSelStsFlag_2 "PTO Speed Selector Status Flag 2";
BA_ "CI_ParId" SG_ 2566848701 PTO_SpdSelStsFlag_2 "NWD-1821";
BA_ "CI_SLOT_Name" SG_ 2566848701 PTO_SpdSelStsFlag_2 "SAEbs01";
BA_ "SPN" SG_ 2566848701 PTO_SpdSelStsFlag_2 522436;
BA_ "CI_FullName" SG_ 2566848701 PTO_SpdSelStsFlag_1 "PTO Speed Selector Status Flag 1";
BA_ "CI_ParId" SG_ 2566848701 PTO_SpdSelStsFlag_1 "NWD-1820";
BA_ "CI_SLOT_Name" SG_ 2566848701 PTO_SpdSelStsFlag_1 "SAEbs01";
BA_ "SPN" SG_ 2566848701 PTO_SpdSelStsFlag_1 522435;
BA_ "CI_FullName" SG_ 2566848701 PTO_SpdSelErrCod "PTO Speed Selector Error Code";
BA_ "CI_ParId" SG_ 2566848701 PTO_SpdSelErrCod "NWD-1819";
BA_ "CI_SLOT_Name" SG_ 2566848701 PTO_SpdSelErrCod "SAEbs08";
BA_ "SPN" SG_ 2566848701 PTO_SpdSelErrCod 522434;
BA_ "CI_FullName" SG_ 2566848701 PTO_ActSpdFdbk "PTO Actuator Speed Feedback";
BA_ "CI_ParId" SG_ 2566848701 PTO_ActSpdFdbk "NWD-1818";
BA_ "CI_SLOT_Name" SG_ 2566848701 PTO_ActSpdFdbk "CNHvl05";
BA_ "SPN" SG_ 2566848701 PTO_ActSpdFdbk 522433;
BA_ "CI_FullName" SG_ 2566848701 PTO_MeasMotorCurr "PTO Measured Motor Current";
BA_ "CI_ParId" SG_ 2566848701 PTO_MeasMotorCurr "NWD-1817";
BA_ "CI_SLOT_Name" SG_ 2566848701 PTO_MeasMotorCurr "SAEec09";
BA_ "SPN" SG_ 2566848701 PTO_MeasMotorCurr 522432;
BA_ "CI_FullName" SG_ 2566848701 PTO_ActPositnFdbk "PTO Actuator Position Feedback";
BA_ "CI_ParId" SG_ 2566848701 PTO_ActPositnFdbk "NWD-1816";
BA_ "CI_SLOT_Name" SG_ 2566848701 PTO_ActPositnFdbk "SAEds04";
BA_ "SPN" SG_ 2566848701 PTO_ActPositnFdbk 522431;
BA_ "CI_FullName" SG_ 2365475111 GndBsdDirect "Ground Based Direction";
BA_ "CI_ParId" SG_ 2365475111 GndBsdDirect "ESMD_08699";
BA_ "SPN" SG_ 2365475111 GndBsdDirect 1861;
BA_ "CI_FullName" SG_ 2365475111 GndBsdImplDist "Ground Based Implement Distance";
BA_ "CI_ParId" SG_ 2365475111 GndBsdImplDist "ESMD_08700";
BA_ "CI_SLOT_Name" SG_ 2365475111 GndBsdImplDist "SAEds05";
BA_ "SPN" SG_ 2365475111 GndBsdImplDist 1860;
BA_ "CI_RepetitionNum" SG_ 2365475111 GndBsdImplSpd 1;
BA_ "CI_RepetitionType" SG_ 2365475111 GndBsdImplSpd 3;
BA_ "CI_FullName" SG_ 2365475111 GndBsdImplSpd "Ground Based Implement Speed";
BA_ "CI_ParId" SG_ 2365475111 GndBsdImplSpd "ESMD_08701";
BA_ "CI_SLOT_Name" SG_ 2365475111 GndBsdImplSpd "SAEvl01";
BA_ "SPN" SG_ 2365475111 GndBsdImplSpd 516;
BA_ "GenSigAutoGenSnd" SG_ 2499803662 MsgCnt 0;
BA_ "GenSigAutoGenDsp" SG_ 2499803662 MsgCnt 0;
BA_ "CI_FullName" SG_ 2499803662 MsgCnt "Message Counter";
BA_ "CI_ParId" SG_ 2499803662 MsgCnt "ESMD_02699";
BA_ "CI_SLOT_Name" SG_ 2499803662 MsgCnt "SAEct08";
BA_ "SPN" SG_ 2499803662 MsgCnt 3689;
BA_ "CI_FullName" SG_ 2499803662 MsgChksum_3 "Message Checksum 3";
BA_ "CI_ParId" SG_ 2499803662 MsgChksum_3 "ESMD_16006";
BA_ "CI_SLOT_Name" SG_ 2499803662 MsgChksum_3 "SAEct03";
BA_ "SPN" SG_ 2499803662 MsgChksum_3 7042;
BA_ "CI_FullName" SG_ 2499803662 LimpHomeReq "Limp Home Request";
BA_ "CI_ParId" SG_ 2499803662 LimpHomeReq "NWD-1909";
BA_ "CI_SLOT_Name" SG_ 2499803662 LimpHomeReq "SAEbs02";
BA_ "SPN" SG_ 2499803662 LimpHomeReq 522496;
BA_ "CI_FullName" SG_ 2499803662 AmbrWarnLmp "Amber Warning Lamp";
BA_ "CI_ParId" SG_ 2499803662 AmbrWarnLmp "ESMD_00554";
BA_ "CI_SLOT_Name" SG_ 2499803662 AmbrWarnLmp "SAEbs02";
BA_ "SPN" SG_ 2499803662 AmbrWarnLmp 624;
BA_ "CI_FullName" SG_ 2499803662 BrakePedPrsRqst "Brake Pedal Pressure Demand";
BA_ "CI_ParId" SG_ 2499803662 BrakePedPrsRqst "NWD-1911";
BA_ "CI_SLOT_Name" SG_ 2499803662 BrakePedPrsRqst "CNHpr07";
BA_ "SPN" SG_ 2499803662 BrakePedPrsRqst 519813;
BA_ "CI_RepetitionNum" SG_ 2499803662 PBrakeMode 1;
BA_ "CI_RepetitionType" SG_ 2499803662 PBrakeMode 3;
BA_ "CI_FullName" SG_ 2499803662 PBrakeMode "Park Brake Mode";
BA_ "CI_ParId" SG_ 2499803662 PBrakeMode "ESMD_24443";
BA_ "CI_SLOT_Name" SG_ 2499803662 PBrakeMode "SAEbs03";
BA_ "CI_RepetitionNum" SG_ 2499803662 TrailBrakeAppliedPrs 1;
BA_ "CI_RepetitionType" SG_ 2499803662 TrailBrakeAppliedPrs 3;
BA_ "CI_FullName" SG_ 2499803662 TrailBrakeAppliedPrs "Output Pressure";
BA_ "CI_ParId" SG_ 2499803662 TrailBrakeAppliedPrs "ESMD_24440";
BA_ "CI_SLOT_Name" SG_ 2499803662 TrailBrakeAppliedPrs "SAEpr11";
BA_ "SPN" SG_ 2499803662 TrailBrakeAppliedPrs 518902;
BA_ "CI_RepetitionNum" SG_ 2499803662 SecBrakeMode 1;
BA_ "CI_RepetitionType" SG_ 2499803662 SecBrakeMode 3;
BA_ "CI_FullName" SG_ 2499803662 SecBrakeMode "Secondary brake mode";
BA_ "CI_ParId" SG_ 2499803662 SecBrakeMode "ESMD_24413";
BA_ "CI_SLOT_Name" SG_ 2499803662 SecBrakeMode "SAEbs03";
BA_ "SPN" SG_ 2499803662 SecBrakeMode 518890;
BA_ "CI_RepetitionNum" SG_ 2499803662 ServBrakeMode 1;
BA_ "CI_RepetitionType" SG_ 2499803662 ServBrakeMode 3;
BA_ "CI_FullName" SG_ 2499803662 ServBrakeMode "Service brake mode";
BA_ "CI_ParId" SG_ 2499803662 ServBrakeMode "ESMD_24414";
BA_ "CI_SLOT_Name" SG_ 2499803662 ServBrakeMode "SAEbs03";
BA_ "SPN" SG_ 2499803662 ServBrakeMode 518891;
BA_ "CI_RepetitionNum" SG_ 2499803662 TrailBrakeCntrlMode 1;
BA_ "CI_RepetitionType" SG_ 2499803662 TrailBrakeCntrlMode 3;
BA_ "CI_FullName" SG_ 2499803662 TrailBrakeCntrlMode "Trailer Brake Control Mode";
BA_ "CI_ParId" SG_ 2499803662 TrailBrakeCntrlMode "ESMD_24442";
BA_ "CI_SLOT_Name" SG_ 2499803662 TrailBrakeCntrlMode "SAEbs04";
BA_ "SPN" SG_ 2499803662 TrailBrakeCntrlMode 518903;
BA_ "CI_RepetitionNum" SG_ 2499803662 XPD_ActvCntrlMode 1;
BA_ "CI_RepetitionType" SG_ 2499803662 XPD_ActvCntrlMode 3;
BA_ "CI_FullName" SG_ 2499803662 XPD_ActvCntrlMode "XPD Active Control Mode";
BA_ "CI_ParId" SG_ 2499803662 XPD_ActvCntrlMode "ESMD_24415";
BA_ "CI_SLOT_Name" SG_ 2499803662 XPD_ActvCntrlMode "SAEbs04";
BA_ "SPN" SG_ 2499803662 XPD_ActvCntrlMode 518892;
BA_ "CI_RepetitionNum" SG_ 2499803662 XPD_PrsLim 1;
BA_ "CI_RepetitionType" SG_ 2499803662 XPD_PrsLim 3;
BA_ "CI_FullName" SG_ 2499803662 XPD_PrsLim "XPD Pressure Limit";
BA_ "CI_ParId" SG_ 2499803662 XPD_PrsLim "ESMD_24416";
BA_ "CI_SLOT_Name" SG_ 2499803662 XPD_PrsLim "SAEpr11";
BA_ "SPN" SG_ 2499803662 XPD_PrsLim 518893;
BA_ "CI_RepetitionNum" SG_ 2499803662 XPD_SysSts 1;
BA_ "CI_RepetitionType" SG_ 2499803662 XPD_SysSts 3;
BA_ "CI_FullName" SG_ 2499803662 XPD_SysSts "XPD System State";
BA_ "CI_ParId" SG_ 2499803662 XPD_SysSts "ESMD_24417";
BA_ "CI_SLOT_Name" SG_ 2499803662 XPD_SysSts "SAEbs02";
BA_ "SPN" SG_ 2499803662 XPD_SysSts 518894;
BA_ "GenSigAutoGenSnd" SG_ 2564459257 SingFrameDataLen 0;
BA_ "GenSigAutoGenDsp" SG_ 2564459257 SingFrameDataLen 0;
BA_ "CI_RepetitionComplemented" SG_ 2564459257 SingFrameDataLen 2;
BA_ "CI_FullName" SG_ 2564459257 SingFrameDataLen "Single Frame Data Length";
BA_ "CI_ParId" SG_ 2564459257 SingFrameDataLen "ESMD_03135";
BA_ "GenSigAutoGenSnd" SG_ 2564459257 SN 0;
BA_ "GenSigAutoGenDsp" SG_ 2564459257 SN 0;
BA_ "CI_RepetitionComplemented" SG_ 2564459257 SN 2;
BA_ "CI_FullName" SG_ 2564459257 SN "Serial Number";
BA_ "CI_ParId" SG_ 2564459257 SN "ESMD_03138";
BA_ "GenSigAutoGenSnd" SG_ 2564459257 ProtocCntrlInfo 0;
BA_ "GenSigAutoGenDsp" SG_ 2564459257 ProtocCntrlInfo 0;
BA_ "CI_RepetitionComplemented" SG_ 2564459257 ProtocCntrlInfo 2;
BA_ "CI_FullName" SG_ 2564459257 ProtocCntrlInfo "Protocol Control Information";
BA_ "CI_ParId" SG_ 2564459257 ProtocCntrlInfo "ESMD_02905";
BA_ "GenSigAutoGenSnd" SG_ 2564459257 N1FrameDataLen 0;
BA_ "GenSigAutoGenDsp" SG_ 2564459257 N1FrameDataLen 0;
BA_ "CI_RepetitionComplemented" SG_ 2564459257 N1FrameDataLen 2;
BA_ "CI_FullName" SG_ 2564459257 N1FrameDataLen "First Frame Data Length";
BA_ "CI_ParId" SG_ 2564459257 N1FrameDataLen "ESMD_01962";
BA_ "GenSigAutoGenSnd" SG_ 2564459257 BlkSize 0;
BA_ "GenSigAutoGenDsp" SG_ 2564459257 BlkSize 0;
BA_ "CI_RepetitionComplemented" SG_ 2564459257 BlkSize 2;
BA_ "CI_FullName" SG_ 2564459257 BlkSize "Block Size";
BA_ "CI_ParId" SG_ 2564459257 BlkSize "ESMD_00809";
BA_ "GenSigAutoGenSnd" SG_ 2564459257 FlowSts 0;
BA_ "GenSigAutoGenDsp" SG_ 2564459257 FlowSts 0;
BA_ "CI_RepetitionComplemented" SG_ 2564459257 FlowSts 2;
BA_ "CI_FullName" SG_ 2564459257 FlowSts "Flow Status";
BA_ "CI_ParId" SG_ 2564459257 FlowSts "ESMD_01968";
BA_ "GenSigAutoGenSnd" SG_ 2564459257 SepTime 0;
BA_ "GenSigAutoGenDsp" SG_ 2564459257 SepTime 0;
BA_ "CI_RepetitionComplemented" SG_ 2564459257 SepTime 2;
BA_ "CI_FullName" SG_ 2564459257 SepTime "Separation Time";
BA_ "CI_ParId" SG_ 2564459257 SepTime "ESMD_03113";
VAL_ 2565799719 ArbAddrCap 0 "No" 1 "Yes" ;
VAL_ 2565799719 Funct 57 "Steering Column Unit" 58 "Fan Drive Control" 59 "Starter" 60 "Cab Display" 61 "File Server/Printer" 62 "On-Board Diagnostic Unit" 63 "Engine Valve Controller" 64 "Endurance Braking" 65 "Gas Flow Measurement" 66 "I/O Controller" 67 "Electrical System Controller" 68 "Aftertreatment system gas measurement" 69 "Engine Emission Aftertreatement System" 30 "Management Computer" 31 "Propulsion Battery Charger" 104 "Reserved" 105 "Reserved" 106 "Reserved" 70 "Auxiliary Regeneration Device" 71 "Transfer Case Control" 72 "Coolant Valve Controller" 73 "Rollover Detection Control" 74 "Lubrication System" 75 "Supplemental Fan" 76 "Temperature Sensor" 77 "Fuel Properties Sensor" 78 "Fire Suppression System" 79 "Reserved" 80 "Reserved" 81 "Reserved" 82 "Reserved" 83 "Reserved" 84 "Reserved" 85 "Reserved" 86 "Reserved" 87 "Reserved" 88 "Reserved" 89 "Reserved" 90 "Reserved" 91 "Reserved" 92 "Reserved" 93 "Reserved" 94 "Reserved" 95 "Reserved" 96 "Reserved" 97 "Reserved" 98 "Reserved" 99 "Reserved" 100 "Reserved" 0 "Engine" 1 "Auxiliary Power Unit (APU)" 2 "Electric Propulsion Control" 3 "Transmission" 4 "Battery Pack Monitor" 5 "Shift Control/Console" 6 "Power TakeOff - (Main or Rear)" 7 "Axle - Steering" 8 "Axle - Drive" 9 "Brakes - System Controller" 10 "Brakes - Steer Axle" 11 "Brakes - Drive Axle" 12 "Retarder - Engine" 13 "Retarder - Driveline" 14 "Cruise Control" 15 "Fuel System" 16 "Steering Controller" 17 "Suspension - Steer Axle" 18 "Suspension - Drive Axle" 19 "Instrument Cluster" 20 "Trip Recorder" 21 "Cab Climate Control" 22 "Aerodynamic Control" 23 "Vehicle Navigation" 24 "Vehicle Security" 107 "Reserved" 108 "Reserved" 109 "Reserved" 110 "Reserved" 111 "Reserved" 112 "Reserved" 113 "Reserved" 114 "Reserved" 115 "Reserved" 116 "Reserved" 117 "Reserved" 118 "Reserved" 119 "Reserved" 120 "Reserved" 121 "Reserved" 122 "Reserved" 123 "Reserved" 124 "Reserved" 125 "Reserved" 126 "Reserved" 127 "Reserved" 25 "Network Interconnect ECU" 26 "Body Controller" 27 "Power TakeOff (Secondary or Front)" 28 "Off Vehicle Gateway" 29 "Virtual Terminal (in cab)" 43 "Transmission Display" 44 "Exhaust Emission Control" 45 "Vehicle Dynamic Stability Control" 46 "Oil Sensor Unit" 47 "Information System Controller" 48 "Ramp Control" 49 "Clutch/Converter Control" 50 "Auxiliary Heater" 51 "Forward-Looking Collision Warning System" 52 "Chassis Controller" 53 "Alternator/Charging System" 54 "Communications Unit, Cellular" 55 "Communications Unit, Satellite" 56 "Communications Unit, Radio" 32 "Headway Controller" 33 "System Monitor" 34 "Hydraulic Pump Controller" 35 "Suspension - System Controller" 36 "Pneumatic - System Controller" 37 "Cab Controller" 38 "Tire Pressure Control" 39 "Ignition Control Module" 40 "Seat Control" 41 "Lighting - Operator Controls" 42 "Water Pump Control" 101 "Reserved" 102 "Reserved" 103 "Reserved" ;
VAL_ 2565799719 IndstryGrp 7 "NotAvailable" 5 "Reserved" 4 "Marine" 3 "Construction" 2 "AgriculturalAndForestry" 1 "OnHighway" 0 "Global" ;
VAL_ 2565799719 ManufctCod 195 "General Engine Products" 196 "LEMKEN GmbH & Co. KG" 197 "Mechron Power Systems" 198 "Mystic Valley Communications" 199 "Actia Corp." 200 "MGM Brakes" 201 "Disenos y Tecnologia S.A." 202 "Curtis Instruments, Inc." 203 "MILtronik GmbH" 204 "The Morey Corporation" 205 "SmarTire Systems Inc" 206 "port GmbH" 207 "Otto Engineering" 208 "Drew Technologies, Inc." 209 "Bell Equip. Co. SA (PTY) LTD" 210 "Iteris, Inc." 211 "DNA Group" 212 "Sure Power Industries, Inc." 213 "CNH Belgium N.V." 214 "MC elettronica Srl" 215 "Aetna Engineering/Fireboy-Xintex" 216 "Paneltronics Inc." 217 "RM Michaelides Software & Elektronik GmbH" 218 "Gits Manufacturing Company" 219 "Cat OEM Solutions" 220 "Beede Electrical Instrument Company, Inc." 221 "SiE" 222 "Generac Power Systems, Inc." 1850 "Teleflex" 1851 "Raymarine" 1852 "Navionics" 1853 "Japan Radio Co." 1854 "Northstar Technologies" 1855 "Furuno USA" 1856 "Trimble" 1857 "Simrad" 1858 "Litton" 1859 "Kvasar AB" 1860 "MMP" 1861 "Vector CANtech" 1862 "Sanshin" 1863 "Thomas G. Faria Co." 232 "TSD Integrated Controls" 234 "Mondial electronic GmbH" 235 "SailorMade Marine Telemetry - Tetra Technology Ltd." 236 "Norac Systems International Inc" 237 "Agtron Enterprises Inc" 238 "ZF Friedrichshafen AG" 239 "May & Scofield Ltd" 240 "Vanair Mfg" 241 "Schneider Automation SAS " 242 "Kokusandenki Co. Ltd" 243 "eRide, Inc." 244 "Techno-Matic" 245 "Capstan Ag Systems, Inc." 246 "Class 1, Inc" 247 "ePULSE" 248 "Cooper Standard Automotive Active Systems Group" 264 "Autolync" 265 "MTS Sensor Technologie GmbH" 266 "International Thermal Research Ltd" 114 "EControls, Inc." 115 "NACCO Materials Handling Group, Inc." 116 "BEELINE Technologies" 117 "HUSCO International" 118 "Intron GmbH" 119 "IntegriNautics" 120 "RDS Technology Ltd." 121 "HED (Hydro Electronic Devices, Inc.)" 122 "FG Wilson (Engineering) Limited" 123 "Basler Electric" 124 "Hydac Electronic" 125 "Nevada Automotive Test Center" 126 "Driver Tech" 127 "Holland USA" 128 "Gerhard Duecker GmbH & Co. KG" 129 "OMNEX Control Systems, Inc." 130 "Nido - Universal Machines B.V." 131 "ITT Industries" 132 "Mulag-Fahrzeugwerk" 133 "Bucher Schoerling GmbH" 134 "Iris Technology Ltd." 135 "Airmar Technology Corporation" 136 "Komatsu Ltd." 137 "Maretron" 138 "Georg Fritzmeier GmbH & Co. KG" 139 "Caterpillar Trimble Control Technologies (CTCT), LLC" 140 "Lowrance Electronics, Inc." 141 "Thales Navigation Ltd." 142 "TRW Automotive (Commercial Steering Systems)" 143 "W. Gmeiner GmbH & Co." 144 "Mercury Marine" 145 "MurCal Controls" 146 "Maxima Technologies" 147 "Nautibus Electronic GmbH" 148 "Blue Water Data, Inc." 149 "Holset" 150 "Fleetguard" 151 "Raven Industries Inc. - Flow Controls Division" 152 "elobau GmbH & Co. KG" 153 "Woodward, Industrial Controls Division" 154 "Westerbeke Corporation" 155 "Vetronix Corporation" 156 "ITT Industries - Cannon" 157 "ISSPRO Inc." 158 "Firestone Industrial Products Company" 159 "NTech Industries Inc." 160 "Nido" 161 "Offshore Systems (UK) Limited" 162 "Axiomatic Technologies" 163 "BRP Inc." 164 "DaimlerChrysler Off-Highway" 165 "CPAC Systems AB" 166 "Phoenix International" 167 "JLG Industries Inc." 168 "Xantrex" 169 "Marlin Technologies Inc." 170 "Computronics Corporation Ltd." 171 "Wachendorff Elektronik GmbH & Co. KG" 172 "Yanmar Marine USA" 173 "Ryeso, Inc." 174 "AB Volvo Penta" 175 "Veris Technologies, Inc." 176 "Moritz Aerospace" 177 "Diagnostic System Associates" 178 "Siemens VDO Automotive AG" 179 "TeeJet Technologies Denmark" 180 "Smart Power Systems" 181 "Coretronics, Inc." 182 "Vehicle Systems Engineering B.V." 183 "KDS Controls, Inc." 184 "EIA Electronics" 185 "Beede Electrical Instrument Company" 186 "Altronic, Inc." 187 "Air-Weigh" 188 "EMP Corp." 189 "QUALCOMM" 190 "Hella KGaA Hueck & Co." 191 "XRS Corporation" 192 "Floscan" 193 "Nobletec" 194 "TriMark Corporation" 378 "Glendinning Marine Products" 379 "Yamabiko Corporation" 380 "Suntech International Ltd." 382 "National Agricultural and Food Research Organization" 383 "MCL Industries" 384 "Camano Light" 385 "Johnson Outdoor Marine Electronics" 386 "JLG Automation BVBA" 387 "Orscheln Products, LLC" 388 "Innomatix, LLC" 389 "Benchmark Electronics, Minnesota Division" 390 "Partech Inc." 391 "Electronic Design for Industry, Inc" 392 "Tianyuan Technology Co Ltd." 393 "Harvest Tec, Inc" 394 "Capi 2 Nederland BV" 395 "GENTEC S.R.L." 396 "Beyond Measure" 397 "Sanyo-kiki Co Ltd." 398 "Hilite International" 399 "ISEKI & Co., Ltd." 400 "Livorsi Marine" 401 "Torqeedo GmbH" 402 "Simma Software, Inc." 403 "Trackwell ADS, Inc." 404 "Com Nav Marine Ltd" 405 "Wema System AS" 406 "Vecima Networks Inc." 407 "Comtech Mobile Datacom" 408 "Corvus Energy Ltd." 409 "Transfluid S.r.L." 410 "COBO S.p.A. Divisione 3B6" 411 "Hy-Drive Technologies Ltd." 412 "WebTech Wireless Inc." 413 "Datapross Nijbroek bv" 414 "Cattron Group International" 415 "Valid Manufacturing Ltd." 416 "Kubota Corporation" 417 "KZValve" 418 "Intellistick Inc" 419 "Fusion Electronics Ltd" 420 "Vermeer Corporation, ACS Group" 421 "Vertex Standard Co., Ltd" 422 "True Heading AB" 423 "BSM Wireless, Inc." 424 "Odyne LLC" 425 "Methode Electronics Inc, MDI" 426 "Egersund Marine Electronics AS" 427 "em-trak Marine Electronics Ltd" 428 "Mfg_428" 429 "Rota Engineering Ltd." 455 "ADZ NAGANO GmbH" 456 "General Kinetics" 457 "RUSELPROM-ElectricDrive Ltd" 458 "Control Solutions, Inc." 459 "Alltek Marine Electronics Corp" 1098 "Preh GmbH" 593 "Sensata Technologies" 460 "San Giorgio S.E.I.N." 267 "Red Lion Controls, Inc" 268 "Accurate Technologies" 269 "Saft America Inc.,  Space & Defense Division" 270 "Tennant" 271 "Cole Hersee" 312 "Lectronix, Inc." 313 "Ilmor Engineering, Inc" 314 "CSM GmbH" 315 "Icom Incorporated" 316 "ITT Flow Control" 317 "Navtronics Bvba" 318 "SAT Plan" 319 "Cadec Global" 320 "Miedema Landbouwwerktuigenfabriek B.V." 321 "Ultra Electronics, Electrics" 322 "MICHENKA s.r.o." 323 "Mobileye Vision Technologies Ltd." 324 "Snap-on Diagnostics" 325 "ASM Automation Sensorik Messtechnik GmbH" 326 "Akron Brass Company" 327 "Sonceboz SA" 272 "Gross Mechanical Laboratories, Inc" 273 "Active Research Limited" 274 "LTW Technology Co., LTD" 275 "Navico Egersund AS" 276 "Aqua-Hot Heating Systems" 277 "LHP Telematics" 278 "Takata Electronics" 279 "Geometris LP" 280 "Leica Geosystems Pty Ltd" 299 "Rauch Landmaschinen GmbH" 300 "Systron Donner Automotive" 301 "Parker Hannifin (UK) Ltd FDE group" 302 "Nissin Kogyo Co., LTD" 303 "CTS Corporation" 304 "EmpirBus AB" 305 "NovAtel Inc" 306 "Sleipner Motor AB" 307 "MBW Technologies" 308 "Cyntrx" 309 "Krauss-Maffei Wegmann GmbH & Co. KG" 310 "TECNORD srl" 311 "Patrick Power Products" 281 "Precision Governors LLC" 282 "Medallion Instrumentation Systems" 283 "CWF Hamilton & Co Ltd" 284 "Mobile Tech Chile" 285 "Sea Recovery Corp" 286 "Coelmo srl" 287 "NTech Industries, Inc" 288 "Mitsubishi FUSO Truck & Bus Corp." 289 "Watlow" 290 "Kuebler GmbH" 291 "Groeneveld Transport Efficiency BV" 292 "IKUSI - Angel Iglesias S.A." 293 "Spyder Controls Corp." 294 "Grayhill Inc." 295 "BEP Marine" 296 "micro dynamics GmbH" 297 "Zonar Systems Inc" 298 "Holley Performance" 253 "Mobile Control Systems" 254 "GE Sensing" 255 "MEAS France" 256 "Tyco Electronics AMP" 257 "Honda Motor Co., Ltd" 258 "ARAG" 259 "Jetter AG" 260 "Reichhardt GmbH" 261 "Red Dot Corporation" 262 "HydraForce, Inc" 263 "IMMI" 223 "Vaueo Retarder Co., Ltd." 224 "EMMI Network, S.L." 225 "SKF" 226 "Monaco Coach Corporation" 227 "Lykketronic A/S" 228 "ZF Marine Electronics" 229 "Garmin International Inc." 230 "Saucon Technologies" 231 "Topcon Positioning Systems, Inc." 0 "Reserved" 1 "Allied Signal Inc." 2 "Allison Transmission, GMC" 3 "Ametek, US Gauge Division" 4 "Ametek-Dixson" 5 "AMP Inc." 6 "Berifors Electronics AB" 7 "Case Corp." 8 "Caterpillar Inc." 9 "Chrysler Corp." 10 "Cummins Engine Co." 11 "Dearborn Group Inc." 12 "Deere & Company, Precision Farming" 13 "Delco Electronics" 14 "Detroit Diesel Corporation" 15 "Dickey-John Corp." 16 "Eaton Corp." 17 "Eaton Corp. Res & Dev" 18 "Eaton Corp, Transmission Division" 19 "Eaton Corp. Trucking Info Services" 20 "Eaton Ltd" 21 "Echilin Inc., Midland Brake Inc." 22 "Ford Motor Co., Electronic Concepts $ Systems" 23 "Ford Motor Co., Heavy Truck" 24 "Ford Motor Co., Vehicle Controls" 25 "Daimler Trucks North America LLC" 26 "General Motors Corp., Service Technology Group" 27 "GMC" 28 "Grote Ind. Inc." 29 "Hino Motors Ltd." 30 "Isuzu Motors Ltd." 31 "J Pollak Corp." 32 "Jacobs Vehicle Systems" 33 "John Deere" 34 "Kelsey Hayes Co." 35 "Kenworth Truck Co." 36 "Lucas Ltd." 37 "Mack Trucks Inc." 38 "Micro Processor Systems Inc." 39 "Microfirm Inc." 40 "Motorola AIEG Inc." 41 "Motorola Inc." 42 "International Truck and Engine Corp. Engine Electronics" 43 "International Truck and Engine Corp. Vehicle Electronics" 233 "Yacht Monitoring Solutions Inc." 249 "Schaltbau GmbH" 250 "Kuhn Group" 251 "German Agricultural Society" 252 "Sensor-Technik Wiedemann GmbH" 328 "Qwerty Electronik AB" 329 "Deif A/S" 330 "Kidde Aerospace and Defense" 331 "Horton, Inc." 332 "HWH Corporation" 333 "Hadley Products Corporation" 334 "Takata-Petri AG" 335 "Evo Electric Ltd" 336 "APE s.r.o." 337 "Carraro S.p.A." 338 "GRAF-SYTECO" 339 "Competence Center ISOBUS e.V." 340 "Continental AG" 341 "Boning GmbH & Co" 342 "THOMAS MAGNETE GmbH" 343 "Baumer Group" 344 "Parvus Corporation" 345 "Korean Maritime University" 346 "Control Solutions" 347 "Honeywell" 348 "Amazonen Werke H. Dreyer" 349 "Suonentiet" 350 "Noris Marine Systems GmbH & Co KG" 351 "Thrane & Thrane" 352 "SAME DEUTZ-FAHR" 353 "Hegemon Electronics, Inc." 354 "Junkkari OY" 355 "Mastervolt International B.V." 356 "Fischer Panda Generators, Inc" 357 "Hardi International A/S" 358 "Victron Energy BV" 359 "Ludwig Bergmann GmbH" 360 "HJS Emission Technology GmbH & Co KG" 361 "InMach" 362 "Alois Poettinger Maschinenfabrik GmbH" 363 "BEI Duncan" 364 "OEM Controls Inc." 365 "Digi-Star, LLC" 366 "Viewnyx Corp." 367 "Fliegl Agrartechnik" 368 "HANSENHOF_electronic" 369 "Power Torque Engineering Ltd" 370 "Rolls-Royce Marine AS" 371 "Heinzmann GmbH & Co. KG" 373 "Electronic Design Inc." 374 "Northern Lights, Inc." 381 "B&G" 372 "Delphi" 375 "Williams Controls Inc." 376 "Quake Global" 454 "NGK Spark Plug Co. Ltd" 480 "EnerDel, Inc." 481 "Chetco Digital Instruments" 482 "Tricon Electronics" 483 "Valeo" 484 "Headsight Inc." 485 "MATT automotive" 377 "ifm electronic gmbh" 44 "Nippondenso Co. Ltd." 45 "PACCAR" 46 "Noregon Systems, Inc" 47 "Phillips Semiconductor" 48 "Pollak Alphabet" 49 "RE America Inc." 50 "Robert Bosch Corp" 51 "Robert Bosch GmbH" 52 "Meritor Automotive, Inc." 53 "Continental Automotive Systems US, Inc." 54 "Meritor Wabco" 55 "Ryder System Inc." 56 "SAIC" 57 "Sauer-Danfoss Co." 58 "SPX Corporation, OTC Division" 59 "VES Inc." 60 "Volvo Trucks North America Inc." 61 "Volvo Truck Corp." 62 "Wabco" 63 "ZF Industries Inc." 64 "unused" 65 "MAN Nutzfahrzeuge AG" 66 "John Deere Construction Equipment Division" 67 "Funk Manufacturing Company" 68 "Scania" 69 "Trimble Navigation" 70 "Flex-Coil Limited" 71 "Vansco Electronics Ltd." 72 "Sisu Corporation" 73 "LeTourneau, Inc." 74 "Eaton Axle-Brake Division" 75 "Deere & Co. Agricultural Division" 76 "unused" 77 "Deere Power Systems Group" 78 "Frank W. Murphy Manufacturing, Inc." 79 "Daimler Benz AG - Engine Division (PBM)" 80 "Twin Disc, Inc." 81 "Fire Research Corp" 82 "Bobcat/Ingersoll-Rand" 83 "Bendix VORAD Technologies" 84 "New Holland UK Limited" 85 "Kohler Co." 86 "C.E. Niehoff & Company" 87 "J.C. Bamford Excavators Ltd (JCB)" 88 "Satloc Precision GPS" 89 "Kverneland Group, Electronics Division" 90 "Knorr-Bremse SfN GmbH" 91 "BSG Bodensee Steuergeraete GmbH" 92 "Ag-Chem Equipment Co., Inc." 93 "Perkins Engines Company Ltd." 94 "CNH Global N.V." 95 "Pacific Insight Electronics Corp." 96 "Mech@tronic IT GmbH" 97 "Ag Leader Technology, Inc." 98 "Mueller-Elektronik GmbH & Co." 99 "International Transmissions Ltd (ITL)" 100 "VDO Technik AG" 101 "Sensoria" 102 "AGCO GmbH & Co." 103 "CLAAS Agrosystems GmbH & Co. KG" 104 "Claas Selbstfahrende Erntemaschinen GmbH" 105 "Kiepe Elektrik GmbH & Co. KG" 106 "BAE Systems Controls, Inc." 107 "Grimme Landmaschinen GmbH & Co. KG" 108 "WTK-Elecktronik GmbH" 109 "TeeJet Technologies Denmark" 110 "EPIQ Sensor-Nite" 111 "Maschinenfabrik Bernard Krone GmbH" 112 "MECALAC" 113 "Stress-Tek, Inc." 461 "HAWE Hydraulik SE" 462 "IHI Shibaura Machinery Corporation" 463 "PROBOTIQ" 464 "Leach International Corporation" 465 "Ashcroft Inc" 466 "Veethree Electronics and Marine LLC" 467 "Lely Industries N.V." 468 "Tyco Fire Protection Products" 469 "RA Consulting GmbH" 470 "SI-TEX Marine Electronics" 471 "Sea Cross Marine AB" 472 "Tenneco Inc." 473 "Boss Industries, Inc." 474 "Persen Technologies Inc." 475 "GME" 476 "Hummingbird Marine Electronics" 477 "OilQuick AB" 478 "OceanSat BV" 479 "Vapor Bus International" 430 "Auteq Telematica S.A." 431 "Tohatsu Corporation" 432 "S&A Systems, Inc." 433 "Rowe Electronics" 434 "Stored Energy Systems" 435 "Zunhammer GmbH" 436 "Kinze Manufacturing" 437 "Digital Yacht Limited" 438 "Comar Systems Ltd" 439 "Hyundai Heavy Industries" 440 "Cummins Power Generation" 441 "PTG Reifendruckregelsysteme GmbH" 442 "Horsch Maschinen GmbH" 443 "SignalQuest, Inc." 444 "ITT Power Solutions" 445 "KAT MECHATRONIC, Electronic Product Division" 446 "CertTech, L.L.C." 447 "Great Plains Mfg." 448 "Stanadyne Corporation, Electronics Systems" 449 "Polaris Industries Inc" 450 "Dycor Technologies Ltd." 451 "Parker Hannifin Corp" 452 "WIKA Alexander Wiegand SE & Co. KG" 453 "Cooper Bussmann" 486 "Westport Innovations Inc." 487 "DSE Test Solutions A/S" 488 "The Charles Machine Works, Inc." 489 "Appareo Systems" 490 "QuikQ" 491 "Penny and Giles Ltd" 492 "Inergy Automotive Systems" 493 "Watcheye" 494 "Synerject" 495 "HOLMER Maschinenbau GmbH" 496 "W. Gessmann GmbH" 497 "SENTRON Sistemas Embarcados" 498 "Innovative Design Solutions, Inc." 499 "LCJ Capteurs" 500 "Oxbo International Corporation" 501 "Agrotronix S.A." 502 "Attwood Corporation" 503 "Naviop S.R.L." 504 "Vesper Marine" 505 "Yetter Farm Equipment" 506 "IHI STAR Machinery Corporation" 507 "Test Center ISOBUS" 508 "Transtech Innovations" 509 "MOTORTECH GmbH" 510 "Marinesoft Co. Ltd" 511 "Sulky" 512 "Inpower LLC" 513 "FarmscanAg" 514 "DISTek Integration, Inc." 515 "GINAF Trucks Nederland B.V." 516 "AVAT Automation GmbH" 517 "Noland Engineering" 518 "Transas USA Inc." 519 "Peeters Landbouwmachines b.v." 520 "Trapeze" ;
VAL_ 2566835470 EngIntakManifld_1Prs 254 "Error" 255 "N/A" ;
VAL_ 2566835470 EngSpd 65024 "Error" 65535 "N/A" ;
VAL_ 2566835470 EngTorqMode 15 "Not available" 14 "VCM_speed_demand" 13 "VCM_torque_demand" 12 "Fuel_limiting" 11 "Not defined" 10 "Retarder_control (not used)" 7 "ABS_control (not used)" 0 "Idling (default)" 1 "Acc_Pedal_Gov(onlyOneBoxApplic)" 2 "Cruise_control (not used)" 3 "PTO_gov (not used)" 4 "Road_speed_limiter (not used)" 5 "ASR_control (not used)" 6 "Trans_control  (not used)" 8 "Torque_limiter" 9 "High_speed_gov" ;
VAL_ 2566835470 EngTotHourOp -2 "Error" -1 "N/A" ;
VAL_ 2566835470 FailModeId 0 "Above normal (most severe)" 1 "Below normal (most severe)" 2 "Data erratic" 3 "Voltage above normal" 4 "Voltage below normal" 5 "Current below normal" 6 "Current above normal" 7 "Mechanical system not responding" 8 "Abnormal frequency" 9 "Abnormal update rate" 10 "Abnormal rate of change" 11 "Root cause not known" 12 "Bad intelligent device" 13 "Out of calibration" 14 "Special intstructions" 15 "Above normal (least severe)" 16 "Above normal (moderately severe)" 17 "Below normal (least severe)" 18 "Below normal (moderately severe)" 19 "Received network data in error" 31 "Not available" ;
VAL_ 2566835470 Month 1 "January" 2 "February" 3 "March" 4 "April" 5 "May" 6 "June" 7 "July" 8 "August" 9 "September" 10 "October" 11 "November" 12 "December" 254 "Error" 255 "Not Available" ;
VAL_ 2566835470 WhBsdVehSpd 65024 "Error" 65535 "N/A" ;
VAL_ 2566835470 AmbrLmpDefSts 3 "Not used" 2 "Error" 1 "Fault is defined with Amber Lamp" 0 "Fault NOT defined w/ Amber Lamp" ;
VAL_ 2566835470 EngCoolntTemp 254 "Error" 255 "N/A" ;
VAL_ 2566835470 RedLmpDefSts 3 "Not used" 2 "Error" 1 "Fault is defined with Red Lamp" 0 "Fault NOT defined with Red Lamp" ;
VAL_ 2566835470 Eng_pcLoadCurrSpd 254 "Error" 255 "N/A" ;
VAL_ 2566834702 AmbrWarnLmp 2 "flashing" 0 "Lamp off" 1 "Lamp on" 3 "Not available" ;
VAL_ 2566834702 FlashAmbrWarnLmpAWL 0 "Slow Flash" 1 "Fast Flash" 2 "Reserved" 3 "Unavailable / Do Not Flash" ;
VAL_ 2566834702 FlashMIL 0 "Slow Flash" 1 "Fast Flash" 2 "Reserved" 3 "Unavailable / Do Not Flash" ;
VAL_ 2566834702 FlashProtLmp 0 "Slow Flash" 1 "Fast Flash" 2 "Reserved" 3 "Unavailable / Do Not Flash" ;
VAL_ 2566834702 FlashRedStopLmpRSL 0 "Slow Flash" 1 "Fast Flash" 2 "Reserved" 3 "Unavailable / Do Not Flash" ;
VAL_ 2566834702 MIL 0 "Lamp off" 1 "Lamp on" 2 "Reserved" 3 "Not available" ;
VAL_ 2566834702 ProtLmp 0 "Lamp off" 1 "Lamp on" 2 "Reserved" 3 "Not available" ;
VAL_ 2566834702 RedStopLmp 0 "Lamp off" 1 "Lamp on" 3 "Not available" ;
VAL_ 2566834958 AmbrWarnLmp 2 "flashing" 0 "Lamp off" 1 "Lamp on" 3 "Not available" ;
VAL_ 2566834958 FlashAmbrWarnLmpAWL 0 "Slow Flash" 1 "Fast Flash" 2 "Reserved" 3 "Unavailable / Do Not Flash" ;
VAL_ 2566834958 FlashMIL 0 "Slow Flash" 1 "Fast Flash" 2 "Reserved" 3 "Unavailable / Do Not Flash" ;
VAL_ 2566834958 FlashProtLmp 0 "Slow Flash" 1 "Fast Flash" 2 "Reserved" 3 "Unavailable / Do Not Flash" ;
VAL_ 2566834958 FlashRedStopLmpRSL 0 "Slow Flash" 1 "Fast Flash" 2 "Reserved" 3 "Unavailable / Do Not Flash" ;
VAL_ 2566834958 MIL 0 "Lamp off" 1 "Lamp on" 2 "Reserved" 3 "Not available" ;
VAL_ 2566834958 ProtLmp 0 "Lamp off" 1 "Lamp on" 2 "Reserved" 3 "Not available" ;
VAL_ 2566834958 RedStopLmp 0 "Lamp off" 1 "Lamp on" 3 "Not available" ;
VAL_ 2565799694 ArbAddrCap 0 "No" 1 "Yes" ;
VAL_ 2565799694 Funct 57 "Steering Column Unit" 58 "Fan Drive Control" 59 "Starter" 60 "Cab Display" 61 "File Server/Printer" 62 "On-Board Diagnostic Unit" 63 "Engine Valve Controller" 64 "Endurance Braking" 65 "Gas Flow Measurement" 66 "I/O Controller" 67 "Electrical System Controller" 68 "Aftertreatment system gas measurement" 69 "Engine Emission Aftertreatement System" 30 "Management Computer" 31 "Propulsion Battery Charger" 104 "Reserved" 105 "Reserved" 106 "Reserved" 70 "Auxiliary Regeneration Device" 71 "Transfer Case Control" 72 "Coolant Valve Controller" 73 "Rollover Detection Control" 74 "Lubrication System" 75 "Supplemental Fan" 76 "Temperature Sensor" 77 "Fuel Properties Sensor" 78 "Fire Suppression System" 79 "Reserved" 80 "Reserved" 81 "Reserved" 82 "Reserved" 83 "Reserved" 84 "Reserved" 85 "Reserved" 86 "Reserved" 87 "Reserved" 88 "Reserved" 89 "Reserved" 90 "Reserved" 91 "Reserved" 92 "Reserved" 93 "Reserved" 94 "Reserved" 95 "Reserved" 96 "Reserved" 97 "Reserved" 98 "Reserved" 99 "Reserved" 100 "Reserved" 0 "Engine" 1 "Auxiliary Power Unit (APU)" 2 "Electric Propulsion Control" 3 "Transmission" 4 "Battery Pack Monitor" 5 "Shift Control/Console" 6 "Power TakeOff - (Main or Rear)" 7 "Axle - Steering" 8 "Axle - Drive" 9 "Brakes - System Controller" 10 "Brakes - Steer Axle" 11 "Brakes - Drive Axle" 12 "Retarder - Engine" 13 "Retarder - Driveline" 14 "Cruise Control" 15 "Fuel System" 16 "Steering Controller" 17 "Suspension - Steer Axle" 18 "Suspension - Drive Axle" 19 "Instrument Cluster" 20 "Trip Recorder" 21 "Cab Climate Control" 22 "Aerodynamic Control" 23 "Vehicle Navigation" 24 "Vehicle Security" 107 "Reserved" 108 "Reserved" 109 "Reserved" 110 "Reserved" 111 "Reserved" 112 "Reserved" 113 "Reserved" 114 "Reserved" 115 "Reserved" 116 "Reserved" 117 "Reserved" 118 "Reserved" 119 "Reserved" 120 "Reserved" 121 "Reserved" 122 "Reserved" 123 "Reserved" 124 "Reserved" 125 "Reserved" 126 "Reserved" 127 "Reserved" 25 "Network Interconnect ECU" 26 "Body Controller" 27 "Power TakeOff (Secondary or Front)" 28 "Off Vehicle Gateway" 29 "Virtual Terminal (in cab)" 43 "Transmission Display" 44 "Exhaust Emission Control" 45 "Vehicle Dynamic Stability Control" 46 "Oil Sensor Unit" 47 "Information System Controller" 48 "Ramp Control" 49 "Clutch/Converter Control" 50 "Auxiliary Heater" 51 "Forward-Looking Collision Warning System" 52 "Chassis Controller" 53 "Alternator/Charging System" 54 "Communications Unit, Cellular" 55 "Communications Unit, Satellite" 56 "Communications Unit, Radio" 32 "Headway Controller" 33 "System Monitor" 34 "Hydraulic Pump Controller" 35 "Suspension - System Controller" 36 "Pneumatic - System Controller" 37 "Cab Controller" 38 "Tire Pressure Control" 39 "Ignition Control Module" 40 "Seat Control" 41 "Lighting - Operator Controls" 42 "Water Pump Control" 101 "Reserved" 102 "Reserved" 103 "Reserved" ;
VAL_ 2565799694 IndstryGrp 7 "NotAvailable" 5 "Reserved" 4 "Marine" 3 "Construction" 2 "AgriculturalAndForestry" 1 "OnHighway" 0 "Global" ;
VAL_ 2565799694 ManufctCod 195 "General Engine Products" 196 "LEMKEN GmbH & Co. KG" 197 "Mechron Power Systems" 198 "Mystic Valley Communications" 199 "Actia Corp." 200 "MGM Brakes" 201 "Disenos y Tecnologia S.A." 202 "Curtis Instruments, Inc." 203 "MILtronik GmbH" 204 "The Morey Corporation" 205 "SmarTire Systems Inc" 206 "port GmbH" 207 "Otto Engineering" 208 "Drew Technologies, Inc." 209 "Bell Equip. Co. SA (PTY) LTD" 210 "Iteris, Inc." 211 "DNA Group" 212 "Sure Power Industries, Inc." 213 "CNH Belgium N.V." 214 "MC elettronica Srl" 215 "Aetna Engineering/Fireboy-Xintex" 216 "Paneltronics Inc." 217 "RM Michaelides Software & Elektronik GmbH" 218 "Gits Manufacturing Company" 219 "Cat OEM Solutions" 220 "Beede Electrical Instrument Company, Inc." 221 "SiE" 222 "Generac Power Systems, Inc." 1850 "Teleflex" 1851 "Raymarine" 1852 "Navionics" 1853 "Japan Radio Co." 1854 "Northstar Technologies" 1855 "Furuno USA" 1856 "Trimble" 1857 "Simrad" 1858 "Litton" 1859 "Kvasar AB" 1860 "MMP" 1861 "Vector CANtech" 1862 "Sanshin" 1863 "Thomas G. Faria Co." 232 "TSD Integrated Controls" 234 "Mondial electronic GmbH" 235 "SailorMade Marine Telemetry - Tetra Technology Ltd." 236 "Norac Systems International Inc" 237 "Agtron Enterprises Inc" 238 "ZF Friedrichshafen AG" 239 "May & Scofield Ltd" 240 "Vanair Mfg" 241 "Schneider Automation SAS " 242 "Kokusandenki Co. Ltd" 243 "eRide, Inc." 244 "Techno-Matic" 245 "Capstan Ag Systems, Inc." 246 "Class 1, Inc" 247 "ePULSE" 248 "Cooper Standard Automotive Active Systems Group" 264 "Autolync" 265 "MTS Sensor Technologie GmbH" 266 "International Thermal Research Ltd" 114 "EControls, Inc." 115 "NACCO Materials Handling Group, Inc." 116 "BEELINE Technologies" 117 "HUSCO International" 118 "Intron GmbH" 119 "IntegriNautics" 120 "RDS Technology Ltd." 121 "HED (Hydro Electronic Devices, Inc.)" 122 "FG Wilson (Engineering) Limited" 123 "Basler Electric" 124 "Hydac Electronic" 125 "Nevada Automotive Test Center" 126 "Driver Tech" 127 "Holland USA" 128 "Gerhard Duecker GmbH & Co. KG" 129 "OMNEX Control Systems, Inc." 130 "Nido - Universal Machines B.V." 131 "ITT Industries" 132 "Mulag-Fahrzeugwerk" 133 "Bucher Schoerling GmbH" 134 "Iris Technology Ltd." 135 "Airmar Technology Corporation" 136 "Komatsu Ltd." 137 "Maretron" 138 "Georg Fritzmeier GmbH & Co. KG" 139 "Caterpillar Trimble Control Technologies (CTCT), LLC" 140 "Lowrance Electronics, Inc." 141 "Thales Navigation Ltd." 142 "TRW Automotive (Commercial Steering Systems)" 143 "W. Gmeiner GmbH & Co." 144 "Mercury Marine" 145 "MurCal Controls" 146 "Maxima Technologies" 147 "Nautibus Electronic GmbH" 148 "Blue Water Data, Inc." 149 "Holset" 150 "Fleetguard" 151 "Raven Industries Inc. - Flow Controls Division" 152 "elobau GmbH & Co. KG" 153 "Woodward, Industrial Controls Division" 154 "Westerbeke Corporation" 155 "Vetronix Corporation" 156 "ITT Industries - Cannon" 157 "ISSPRO Inc." 158 "Firestone Industrial Products Company" 159 "NTech Industries Inc." 160 "Nido" 161 "Offshore Systems (UK) Limited" 162 "Axiomatic Technologies" 163 "BRP Inc." 164 "DaimlerChrysler Off-Highway" 165 "CPAC Systems AB" 166 "Phoenix International" 167 "JLG Industries Inc." 168 "Xantrex" 169 "Marlin Technologies Inc." 170 "Computronics Corporation Ltd." 171 "Wachendorff Elektronik GmbH & Co. KG" 172 "Yanmar Marine USA" 173 "Ryeso, Inc." 174 "AB Volvo Penta" 175 "Veris Technologies, Inc." 176 "Moritz Aerospace" 177 "Diagnostic System Associates" 178 "Siemens VDO Automotive AG" 179 "TeeJet Technologies Denmark" 180 "Smart Power Systems" 181 "Coretronics, Inc." 182 "Vehicle Systems Engineering B.V." 183 "KDS Controls, Inc." 184 "EIA Electronics" 185 "Beede Electrical Instrument Company" 186 "Altronic, Inc." 187 "Air-Weigh" 188 "EMP Corp." 189 "QUALCOMM" 190 "Hella KGaA Hueck & Co." 191 "XRS Corporation" 192 "Floscan" 193 "Nobletec" 194 "TriMark Corporation" 378 "Glendinning Marine Products" 379 "Yamabiko Corporation" 380 "Suntech International Ltd." 382 "National Agricultural and Food Research Organization" 383 "MCL Industries" 384 "Camano Light" 385 "Johnson Outdoor Marine Electronics" 386 "JLG Automation BVBA" 387 "Orscheln Products, LLC" 388 "Innomatix, LLC" 389 "Benchmark Electronics, Minnesota Division" 390 "Partech Inc." 391 "Electronic Design for Industry, Inc" 392 "Tianyuan Technology Co Ltd." 393 "Harvest Tec, Inc" 394 "Capi 2 Nederland BV" 395 "GENTEC S.R.L." 396 "Beyond Measure" 397 "Sanyo-kiki Co Ltd." 398 "Hilite International" 399 "ISEKI & Co., Ltd." 400 "Livorsi Marine" 401 "Torqeedo GmbH" 402 "Simma Software, Inc." 403 "Trackwell ADS, Inc." 404 "Com Nav Marine Ltd" 405 "Wema System AS" 406 "Vecima Networks Inc." 407 "Comtech Mobile Datacom" 408 "Corvus Energy Ltd." 409 "Transfluid S.r.L." 410 "COBO S.p.A. Divisione 3B6" 411 "Hy-Drive Technologies Ltd." 412 "WebTech Wireless Inc." 413 "Datapross Nijbroek bv" 414 "Cattron Group International" 415 "Valid Manufacturing Ltd." 416 "Kubota Corporation" 417 "KZValve" 418 "Intellistick Inc" 419 "Fusion Electronics Ltd" 420 "Vermeer Corporation, ACS Group" 421 "Vertex Standard Co., Ltd" 422 "True Heading AB" 423 "BSM Wireless, Inc." 424 "Odyne LLC" 425 "Methode Electronics Inc, MDI" 426 "Egersund Marine Electronics AS" 427 "em-trak Marine Electronics Ltd" 428 "Mfg_428" 429 "Rota Engineering Ltd." 455 "ADZ NAGANO GmbH" 456 "General Kinetics" 457 "RUSELPROM-ElectricDrive Ltd" 458 "Control Solutions, Inc." 459 "Alltek Marine Electronics Corp" 1098 "Preh GmbH" 593 "Sensata Technologies" 460 "San Giorgio S.E.I.N." 267 "Red Lion Controls, Inc" 268 "Accurate Technologies" 269 "Saft America Inc.,  Space & Defense Division" 270 "Tennant" 271 "Cole Hersee" 312 "Lectronix, Inc." 313 "Ilmor Engineering, Inc" 314 "CSM GmbH" 315 "Icom Incorporated" 316 "ITT Flow Control" 317 "Navtronics Bvba" 318 "SAT Plan" 319 "Cadec Global" 320 "Miedema Landbouwwerktuigenfabriek B.V." 321 "Ultra Electronics, Electrics" 322 "MICHENKA s.r.o." 323 "Mobileye Vision Technologies Ltd." 324 "Snap-on Diagnostics" 325 "ASM Automation Sensorik Messtechnik GmbH" 326 "Akron Brass Company" 327 "Sonceboz SA" 272 "Gross Mechanical Laboratories, Inc" 273 "Active Research Limited" 274 "LTW Technology Co., LTD" 275 "Navico Egersund AS" 276 "Aqua-Hot Heating Systems" 277 "LHP Telematics" 278 "Takata Electronics" 279 "Geometris LP" 280 "Leica Geosystems Pty Ltd" 299 "Rauch Landmaschinen GmbH" 300 "Systron Donner Automotive" 301 "Parker Hannifin (UK) Ltd FDE group" 302 "Nissin Kogyo Co., LTD" 303 "CTS Corporation" 304 "EmpirBus AB" 305 "NovAtel Inc" 306 "Sleipner Motor AB" 307 "MBW Technologies" 308 "Cyntrx" 309 "Krauss-Maffei Wegmann GmbH & Co. KG" 310 "TECNORD srl" 311 "Patrick Power Products" 281 "Precision Governors LLC" 282 "Medallion Instrumentation Systems" 283 "CWF Hamilton & Co Ltd" 284 "Mobile Tech Chile" 285 "Sea Recovery Corp" 286 "Coelmo srl" 287 "NTech Industries, Inc" 288 "Mitsubishi FUSO Truck & Bus Corp." 289 "Watlow" 290 "Kuebler GmbH" 291 "Groeneveld Transport Efficiency BV" 292 "IKUSI - Angel Iglesias S.A." 293 "Spyder Controls Corp." 294 "Grayhill Inc." 295 "BEP Marine" 296 "micro dynamics GmbH" 297 "Zonar Systems Inc" 298 "Holley Performance" 253 "Mobile Control Systems" 254 "GE Sensing" 255 "MEAS France" 256 "Tyco Electronics AMP" 257 "Honda Motor Co., Ltd" 258 "ARAG" 259 "Jetter AG" 260 "Reichhardt GmbH" 261 "Red Dot Corporation" 262 "HydraForce, Inc" 263 "IMMI" 223 "Vaueo Retarder Co., Ltd." 224 "EMMI Network, S.L." 225 "SKF" 226 "Monaco Coach Corporation" 227 "Lykketronic A/S" 228 "ZF Marine Electronics" 229 "Garmin International Inc." 230 "Saucon Technologies" 231 "Topcon Positioning Systems, Inc." 0 "Reserved" 1 "Allied Signal Inc." 2 "Allison Transmission, GMC" 3 "Ametek, US Gauge Division" 4 "Ametek-Dixson" 5 "AMP Inc." 6 "Berifors Electronics AB" 7 "Case Corp." 8 "Caterpillar Inc." 9 "Chrysler Corp." 10 "Cummins Engine Co." 11 "Dearborn Group Inc." 12 "Deere & Company, Precision Farming" 13 "Delco Electronics" 14 "Detroit Diesel Corporation" 15 "Dickey-John Corp." 16 "Eaton Corp." 17 "Eaton Corp. Res & Dev" 18 "Eaton Corp, Transmission Division" 19 "Eaton Corp. Trucking Info Services" 20 "Eaton Ltd" 21 "Echilin Inc., Midland Brake Inc." 22 "Ford Motor Co., Electronic Concepts $ Systems" 23 "Ford Motor Co., Heavy Truck" 24 "Ford Motor Co., Vehicle Controls" 25 "Daimler Trucks North America LLC" 26 "General Motors Corp., Service Technology Group" 27 "GMC" 28 "Grote Ind. Inc." 29 "Hino Motors Ltd." 30 "Isuzu Motors Ltd." 31 "J Pollak Corp." 32 "Jacobs Vehicle Systems" 33 "John Deere" 34 "Kelsey Hayes Co." 35 "Kenworth Truck Co." 36 "Lucas Ltd." 37 "Mack Trucks Inc." 38 "Micro Processor Systems Inc." 39 "Microfirm Inc." 40 "Motorola AIEG Inc." 41 "Motorola Inc." 42 "International Truck and Engine Corp. Engine Electronics" 43 "International Truck and Engine Corp. Vehicle Electronics" 233 "Yacht Monitoring Solutions Inc." 249 "Schaltbau GmbH" 250 "Kuhn Group" 251 "German Agricultural Society" 252 "Sensor-Technik Wiedemann GmbH" 328 "Qwerty Electronik AB" 329 "Deif A/S" 330 "Kidde Aerospace and Defense" 331 "Horton, Inc." 332 "HWH Corporation" 333 "Hadley Products Corporation" 334 "Takata-Petri AG" 335 "Evo Electric Ltd" 336 "APE s.r.o." 337 "Carraro S.p.A." 338 "GRAF-SYTECO" 339 "Competence Center ISOBUS e.V." 340 "Continental AG" 341 "Boning GmbH & Co" 342 "THOMAS MAGNETE GmbH" 343 "Baumer Group" 344 "Parvus Corporation" 345 "Korean Maritime University" 346 "Control Solutions" 347 "Honeywell" 348 "Amazonen Werke H. Dreyer" 349 "Suonentiet" 350 "Noris Marine Systems GmbH & Co KG" 351 "Thrane & Thrane" 352 "SAME DEUTZ-FAHR" 353 "Hegemon Electronics, Inc." 354 "Junkkari OY" 355 "Mastervolt International B.V." 356 "Fischer Panda Generators, Inc" 357 "Hardi International A/S" 358 "Victron Energy BV" 359 "Ludwig Bergmann GmbH" 360 "HJS Emission Technology GmbH & Co KG" 361 "InMach" 362 "Alois Poettinger Maschinenfabrik GmbH" 363 "BEI Duncan" 364 "OEM Controls Inc." 365 "Digi-Star, LLC" 366 "Viewnyx Corp." 367 "Fliegl Agrartechnik" 368 "HANSENHOF_electronic" 369 "Power Torque Engineering Ltd" 370 "Rolls-Royce Marine AS" 371 "Heinzmann GmbH & Co. KG" 373 "Electronic Design Inc." 374 "Northern Lights, Inc." 381 "B&G" 372 "Delphi" 375 "Williams Controls Inc." 376 "Quake Global" 454 "NGK Spark Plug Co. Ltd" 480 "EnerDel, Inc." 481 "Chetco Digital Instruments" 482 "Tricon Electronics" 483 "Valeo" 484 "Headsight Inc." 485 "MATT automotive" 377 "ifm electronic gmbh" 44 "Nippondenso Co. Ltd." 45 "PACCAR" 46 "Noregon Systems, Inc" 47 "Phillips Semiconductor" 48 "Pollak Alphabet" 49 "RE America Inc." 50 "Robert Bosch Corp" 51 "Robert Bosch GmbH" 52 "Meritor Automotive, Inc." 53 "Continental Automotive Systems US, Inc." 54 "Meritor Wabco" 55 "Ryder System Inc." 56 "SAIC" 57 "Sauer-Danfoss Co." 58 "SPX Corporation, OTC Division" 59 "VES Inc." 60 "Volvo Trucks North America Inc." 61 "Volvo Truck Corp." 62 "Wabco" 63 "ZF Industries Inc." 64 "unused" 65 "MAN Nutzfahrzeuge AG" 66 "John Deere Construction Equipment Division" 67 "Funk Manufacturing Company" 68 "Scania" 69 "Trimble Navigation" 70 "Flex-Coil Limited" 71 "Vansco Electronics Ltd." 72 "Sisu Corporation" 73 "LeTourneau, Inc." 74 "Eaton Axle-Brake Division" 75 "Deere & Co. Agricultural Division" 76 "unused" 77 "Deere Power Systems Group" 78 "Frank W. Murphy Manufacturing, Inc." 79 "Daimler Benz AG - Engine Division (PBM)" 80 "Twin Disc, Inc." 81 "Fire Research Corp" 82 "Bobcat/Ingersoll-Rand" 83 "Bendix VORAD Technologies" 84 "New Holland UK Limited" 85 "Kohler Co." 86 "C.E. Niehoff & Company" 87 "J.C. Bamford Excavators Ltd (JCB)" 88 "Satloc Precision GPS" 89 "Kverneland Group, Electronics Division" 90 "Knorr-Bremse SfN GmbH" 91 "BSG Bodensee Steuergeraete GmbH" 92 "Ag-Chem Equipment Co., Inc." 93 "Perkins Engines Company Ltd." 94 "CNH Global N.V." 95 "Pacific Insight Electronics Corp." 96 "Mech@tronic IT GmbH" 97 "Ag Leader Technology, Inc." 98 "Mueller-Elektronik GmbH & Co." 99 "International Transmissions Ltd (ITL)" 100 "VDO Technik AG" 101 "Sensoria" 102 "AGCO GmbH & Co." 103 "CLAAS Agrosystems GmbH & Co. KG" 104 "Claas Selbstfahrende Erntemaschinen GmbH" 105 "Kiepe Elektrik GmbH & Co. KG" 106 "BAE Systems Controls, Inc." 107 "Grimme Landmaschinen GmbH & Co. KG" 108 "WTK-Elecktronik GmbH" 109 "TeeJet Technologies Denmark" 110 "EPIQ Sensor-Nite" 111 "Maschinenfabrik Bernard Krone GmbH" 112 "MECALAC" 113 "Stress-Tek, Inc." 461 "HAWE Hydraulik SE" 462 "IHI Shibaura Machinery Corporation" 463 "PROBOTIQ" 464 "Leach International Corporation" 465 "Ashcroft Inc" 466 "Veethree Electronics and Marine LLC" 467 "Lely Industries N.V." 468 "Tyco Fire Protection Products" 469 "RA Consulting GmbH" 470 "SI-TEX Marine Electronics" 471 "Sea Cross Marine AB" 472 "Tenneco Inc." 473 "Boss Industries, Inc." 474 "Persen Technologies Inc." 475 "GME" 476 "Hummingbird Marine Electronics" 477 "OilQuick AB" 478 "OceanSat BV" 479 "Vapor Bus International" 430 "Auteq Telematica S.A." 431 "Tohatsu Corporation" 432 "S&A Systems, Inc." 433 "Rowe Electronics" 434 "Stored Energy Systems" 435 "Zunhammer GmbH" 436 "Kinze Manufacturing" 437 "Digital Yacht Limited" 438 "Comar Systems Ltd" 439 "Hyundai Heavy Industries" 440 "Cummins Power Generation" 441 "PTG Reifendruckregelsysteme GmbH" 442 "Horsch Maschinen GmbH" 443 "SignalQuest, Inc." 444 "ITT Power Solutions" 445 "KAT MECHATRONIC, Electronic Product Division" 446 "CertTech, L.L.C." 447 "Great Plains Mfg." 448 "Stanadyne Corporation, Electronics Systems" 449 "Polaris Industries Inc" 450 "Dycor Technologies Ltd." 451 "Parker Hannifin Corp" 452 "WIKA Alexander Wiegand SE & Co. KG" 453 "Cooper Bussmann" 486 "Westport Innovations Inc." 487 "DSE Test Solutions A/S" 488 "The Charles Machine Works, Inc." 489 "Appareo Systems" 490 "QuikQ" 491 "Penny and Giles Ltd" 492 "Inergy Automotive Systems" 493 "Watcheye" 494 "Synerject" 495 "HOLMER Maschinenbau GmbH" 496 "W. Gessmann GmbH" 497 "SENTRON Sistemas Embarcados" 498 "Innovative Design Solutions, Inc." 499 "LCJ Capteurs" 500 "Oxbo International Corporation" 501 "Agrotronix S.A." 502 "Attwood Corporation" 503 "Naviop S.R.L." 504 "Vesper Marine" 505 "Yetter Farm Equipment" 506 "IHI STAR Machinery Corporation" 507 "Test Center ISOBUS" 508 "Transtech Innovations" 509 "MOTORTECH GmbH" 510 "Marinesoft Co. Ltd" 511 "Sulky" 512 "Inpower LLC" 513 "FarmscanAg" 514 "DISTek Integration, Inc." 515 "GINAF Trucks Nederland B.V." 516 "AVAT Automation GmbH" 517 "Noland Engineering" 518 "Transas USA Inc." 519 "Peeters Landbouwmachines b.v." 520 "Trapeze" ;
VAL_ 2632777486 CByteTPCM 16 "RTS" 17 "CTS" 19 "EoMA" 32 "BAM" 255 "Abort" ;
VAL_ 2632777486 ConnAbrtReason 1 "AlreadyInConnManagedSession" 2 "NoFreeSystemResources" 3 "Timeout_CloseSession" 4 "UnexpectedDataTransferPacket" 5 "BadSequenceNumber" 6 "DuplicateSequenceNumber" 7 "AnyOtherError" ;
VAL_ 2632777486 PGN_PktMsgTPCM_BAM 255 "NotAvailable" ;
VAL_ 2632777486 PGN_PktMsgTPCM_ConnAbort 255 "NotAvailable" ;
VAL_ 2632777486 PGN_PktMsgTPCM_CTS 255 "NotAvailable" ;
VAL_ 2632777486 PGN_PktMsgTPCM_RTS 255 "NotAvailable" ;
VAL_ 2632777486 PGN_PktMsgTPCM_RTS2 255 "NotAvailable" ;
VAL_ 2565352206 CByteAckm 3 "CannotRespond" 2 "AccessDenied" 1 "NACK" 0 "ACK" ;
VAL_ 2565352206 PGN_RQST2_0E_28 65259 "CI" 65229 "DM4Req" 64965 "ECUID" 60928 "ACL" 41728 "DM31Req" 65242 "SOFT" 65235 "DM11Req" 65228 "DM3Req" 65227 "DM2Req" ;
VAL_ 2560830222 DTCxAmbrWarnLmpSupp_andSts 2 "Reserved" 0 "Lamp OFF (Amber lamp supported)" 1 "Lamp ON (Amber lamp supported)" 3 "Amber not supported for SPN/FMI" ;
VAL_ 2560830222 DTCxFlashAmbrWarnLmpSupp_andSts 2 "Reserved" 3 "Unavailable" 0 "SlowFlash" 1 "FastFlash" ;
VAL_ 2560830222 DTCxFlashMIL_Supp_andSts 0 "SlowFlash" 1 "FastFlash" 2 "Class_C_DTC" 3 "Unavailable" ;
VAL_ 2560830222 DTCxFlashProtLmpSupp_andSts 0 "SlowFlash" 1 "FastFlash" 2 "Reserved" 3 "Unavailable" ;
VAL_ 2560830222 DTCxFlashRedStopLmpSupp_andSts 0 "SlowFlash" 1 "FastFlash" 2 "Reserved" 3 "Unavailable" ;
VAL_ 2560830222 DTCxMIL_Supp_andSts 0 "LampOff" 1 "LampOn" 2 "ShortMI" 3 "Unavailable" ;
VAL_ 2560830222 DTCxProtLmpSupp_andSts 2 "Reserved" 3 "Unavailable" 0 "LampOff" 1 "LampOn" ;
VAL_ 2560830222 DTCxRedStopLmpSupp_andSts 2 "Reserved" 0 "Lamp OFF (Red lamp supported)" 1 "Lamp ON (Red lamp supported)" 3 "Red not supported for SPN/FMI" ;
VAL_ 2565537579 PGN_RQST_2B 65235 "DM11" 64965 "ECUID" 65259 "CI" 65242 "SOFT" 65227 "DM2" 65228 "DM3" 60928 "ACL" ;
VAL_ 2565475883 PGN_RQST_2B_0E 65259 "CI" 65229 "DM4Req" 64965 "ECUID" 60928 "ACL" 41728 "DM31Req" 65242 "SOFT" 65235 "DM11Req" 65228 "DM3Req" 65227 "DM2Req" ;
VAL_ 2564487438 FlowSts 0 "Continue To Send" 1 "Wait " 2 "Overflow" ;
VAL_ 2564487438 ProtocCntrlInfo 0 "Single frame" 1 "First frame" 2 "Consecutive frame" 3 "Flow control " ;
VAL_ 2564427513 FlowSts 0 "Continue To Send" 1 "Wait " 2 "Overflow" ;
VAL_ 2564427513 ProtocCntrlInfo 0 "Single frame" 1 "First frame" 2 "Consecutive frame" 3 "Flow control " ;
VAL_ 2565351438 CByteAckm 3 "CannotRespond" 2 "AccessDenied" 1 "NACK" 0 "ACK" ;
VAL_ 2565351438 PGN_RQST2_0E_28 65259 "CI" 65229 "DM4Req" 64965 "ECUID" 60928 "ACL" 41728 "DM31Req" 65242 "SOFT" 65235 "DM11Req" 65228 "DM3Req" 65227 "DM2Req" ;
VAL_ 2560829454 DTCxAmbrWarnLmpSupp_andSts 2 "Reserved" 0 "Lamp OFF (Amber lamp supported)" 1 "Lamp ON (Amber lamp supported)" 3 "Amber not supported for SPN/FMI" ;
VAL_ 2560829454 DTCxFlashAmbrWarnLmpSupp_andSts 2 "Reserved" 3 "Unavailable" 0 "SlowFlash" 1 "FastFlash" ;
VAL_ 2560829454 DTCxFlashMIL_Supp_andSts 0 "SlowFlash" 1 "FastFlash" 2 "Class_C_DTC" 3 "Unavailable" ;
VAL_ 2560829454 DTCxFlashProtLmpSupp_andSts 0 "SlowFlash" 1 "FastFlash" 2 "Reserved" 3 "Unavailable" ;
VAL_ 2560829454 DTCxFlashRedStopLmpSupp_andSts 0 "SlowFlash" 1 "FastFlash" 2 "Reserved" 3 "Unavailable" ;
VAL_ 2560829454 DTCxMIL_Supp_andSts 0 "LampOff" 1 "LampOn" 2 "ShortMI" 3 "Unavailable" ;
VAL_ 2560829454 DTCxProtLmpSupp_andSts 2 "Reserved" 3 "Unavailable" 0 "LampOff" 1 "LampOn" ;
VAL_ 2560829454 DTCxRedStopLmpSupp_andSts 2 "Reserved" 0 "Lamp OFF (Red lamp supported)" 1 "Lamp ON (Red lamp supported)" 3 "Red not supported for SPN/FMI" ;
VAL_ 2565537576 PGN_RQST_28 65235 "DM11" 64965 "ECUID" 65259 "CI" 65242 "SOFT" 65227 "DM2" 65228 "DM3" 60928 "ACL" ;
VAL_ 2565475880 PGN_RQST_28_0E 65259 "CI" 65229 "DM4Req" 64965 "ECUID" 60928 "ACL" 41728 "DM31Req" 65242 "SOFT" 65235 "DM11Req" 65228 "DM3Req" 65227 "DM2Req" ;
VAL_ 2564489209 FlowSts 0 "Continue To Send" 1 "Wait " 2 "Overflow" ;
VAL_ 2564489209 ProtocCntrlInfo 0 "Single frame" 1 "First frame" 2 "Consecutive frame" 3 "Flow control " ;
VAL_ 2566848701 PTO_SpdSelStsFlag_5 1 "On" 0 "Off" ;
VAL_ 2566848701 PTO_SpdSelStsFlag_4 1 "On" 0 "Off" ;
VAL_ 2566848701 PTO_SpdSelStsFlag_3 1 "On" 0 "Off" ;
VAL_ 2566848701 PTO_SpdSelStsFlag_2 1 "On" 0 "Off" ;
VAL_ 2566848701 PTO_SpdSelStsFlag_1 1 "On" 0 "Off" ;
VAL_ 2566848701 PTO_SpdSelErrCod 9 "SMPS error (internal)" 8 "Heart beat error (internal)" 7 "Temperature error" 6 "Power on block state" 5 "ESS error" 4 "CAN keep alive signal failed" 3 "Under Voltage" 2 "Over Voltage" 1 "Hall error" 0 "No error" ;
VAL_ 2365475111 GndBsdDirect 3 "NotAvailable" 2 "ErrorIndication" 1 "Forward" 0 "Reverse" ;
VAL_ 2499803662 LimpHomeReq 3 "N/A" 2 "Error" 1 "Active" 0 "Not Active" ;
VAL_ 2499803662 AmbrWarnLmp 2 "flashing" 0 "Lamp off" 1 "Lamp on" 3 "Not available" ;
VAL_ 2499803662 SecBrakeMode 0 "Inactive" 1 "Active" 2 "Active with errors" 3 "101 - Reserved" 6 "Secondary brake not functional" 7 "Not available" ;
VAL_ 2499803662 ServBrakeMode 0 "Inactive" 1 "Active" 2 "Active, with errors" 3 "101 - Reserved" 6 "Service brake not functional" 7 "Not available" ;
VAL_ 2499803662 TrailBrakeCntrlMode 15 " NA" 14 "Error" 13 "Reserved" 12 "Reserved" 11 "Reserved" 10 "Reserved" 9 "Reserved" 8 "Reserved" 7 "Reserved" 6 "Park brake demand" 5 "No braking due to active SBL" 4 "External pressure demand" 3 "Stabilization function demand" 2 "Secondary brakes demand" 1 "Service brakes demand" 0 "No brake demand executed" ;
VAL_ 2499803662 XPD_ActvCntrlMode 0 "No brake demandExecutedDefltMode" 1 "DrivBrakeDemandExecNoExtBrakDem" 2 "AddModeXBR AccelCntrlBeingExec" 3 "MaxModeXBR Accel Cntrl beingExec" 4 "StabilBrakingModeContinuous" 15 "Not available" 7 "to E - reserved" 6 "SBL active" 5 "StabilBrakingModeIntermittant" ;
VAL_ 2499803662 XPD_SysSts 0 "AnyExteBrakeDemandAccep-FullyOp" 1 "OnlyExterBrakeDemWithHighXBRprio" 2 "NoExterBrakeDemandWillBeAccepted" 3 "not available" ;
VAL_ 2564459257 ProtocCntrlInfo 0 "Single frame" 1 "First frame" 2 "Consecutive frame" 3 "Flow control " ;
VAL_ 2564459257 FlowSts 0 "Continue To Send" 1 "Wait " 2 "Overflow" ;
